VERSION ""

NS_ :

BS_:

BU_: CGM_HS TCM_HS RDCM_HS EPS_HS ECM_HS EBCM_HS BSM_HS BCM_HS

BO_ 313 Body_Information_4_HS: 8 BCM_HS
 SG_ LnchCtrlRelLnLockReqd : 15|1@0+ (1,0) [0|1] ""  CGM_HS,EBCM_HS
 SG_ VehStbEnhmntCurStRq : 47|2@0+ (1,0) [0|3] ""  CGM_HS,EBCM_HS
 SG_ TCSysCurStReq : 23|2@0+ (1,0) [0|3] ""  CGM_HS,EBCM_HS
 SG_ DrvrDrOpenSwVDA : 14|1@0+ (1,0) [0|1] ""  CGM_HS,ECM_HS
 SG_ DrDoorOpenSwActV : 12|1@0+ (1,0) [0|1] ""  CGM_HS,ECM_HS
 SG_ DrDoorOpenSwAct : 11|1@0+ (1,0) [0|1] ""  CGM_HS,ECM_HS
 SG_ LnchCtrlWhlSlpReq : 55|5@0+ (1,0) [0|31] ""  CGM_HS,EBCM_HS
 SG_ LnchCtrlMdReq : 57|2@0+ (1,0) [0|3] ""  CGM_HS,EBCM_HS
 SG_ LnchCtrlEngRPMReq : 63|6@0+ (1,0) [0|63] ""  CGM_HS,EBCM_HS
 SG_ ExtHlStrAssCsStRq : 50|3@0+ (1,0) [0|7] ""  CGM_HS,EBCM_HS
 SG_ DrvStyPerfMdCsStReq : 45|3@0+ (1,0) [0|7] ""  CGM_HS,EBCM_HS
 SG_ PsngStPerfMdCsStReq : 42|3@0+ (1,0) [0|7] ""  CGM_HS,EBCM_HS
 SG_ DrvrStPerfMdCsStReq : 31|3@0+ (1,0) [0|7] ""  CGM_HS,EBCM_HS
 SG_ ACCPerfMdCsStReq : 28|3@0+ (1,0) [0|7] ""  CGM_HS,EBCM_HS
 SG_ PrkAstAdvSysAct : 8|1@0+ (1,0) [0|1] ""  CGM_HS,EBCM_HS
 SG_ SndPerfMdCsStRq : 18|3@0+ (1,0) [0|7] ""  CGM_HS,EBCM_HS
 SG_ HptcStVbnStat : 2|2@0+ (1,0) [0|3] ""  CGM_HS
 SG_ ACCSettingType : 10|2@0+ (1,0) [0|3] ""  CGM_HS
 SG_ FCABrkPrflReq : 13|1@0+ (1,0) [0|1] ""  CGM_HS,EBCM_HS
 SG_ ISA2CCC_ScndCdChr : 36|5@0+ (1,0) [0|31] ""  CGM_HS
 SG_ ISA2CCC_FrstCdChr : 25|5@0+ (1,0) [0|31] ""  CGM_HS
 SG_ DispPerfMdCsStRq : 21|3@0+ (1,0) [0|7] ""  CGM_HS,EBCM_HS
 SG_ CrshAlrtStPrsnt : 0|1@0+ (1,0) [0|1] ""  CGM_HS,EBCM_HS
 SG_ FwdClnAlrtCustStngReq : 5|3@0+ (1,0) [0|7] ""  CGM_HS
 SG_ GNCustStngReq : 7|2@0+ (1,0) [0|3] ""  CGM_HS

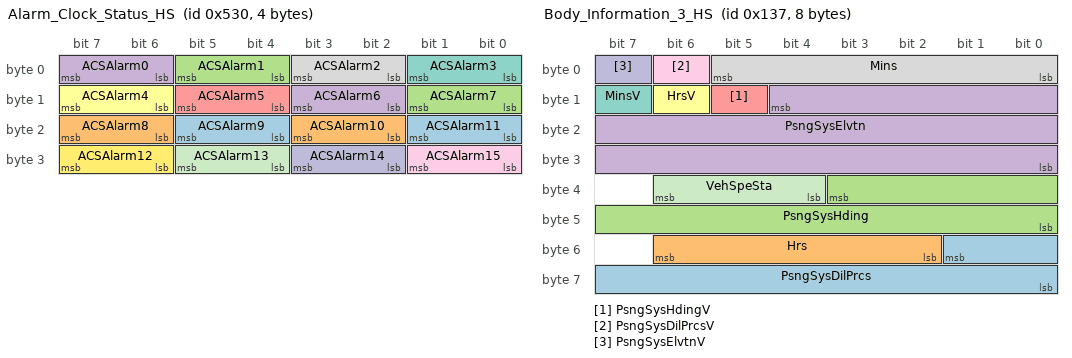
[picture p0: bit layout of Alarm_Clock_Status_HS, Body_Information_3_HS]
BO_ 1328 Alarm_Clock_Status_HS: 4 BCM_HS
 SG_ ACSAlarm9 : 21|2@0+ (1,0) [0|3] ""  CGM_HS
 SG_ ACSAlarm8 : 23|2@0+ (1,0) [0|3] ""  CGM_HS
 SG_ ACSAlarm7 : 9|2@0+ (1,0) [0|3] ""  CGM_HS
 SG_ ACSAlarm6 : 11|2@0+ (1,0) [0|3] ""  CGM_HS
 SG_ ACSAlarm5 : 13|2@0+ (1,0) [0|3] ""  CGM_HS
 SG_ ACSAlarm4 : 15|2@0+ (1,0) [0|3] ""  CGM_HS
 SG_ ACSAlarm3 : 1|2@0+ (1,0) [0|3] ""  CGM_HS
 SG_ ACSAlarm2 : 3|2@0+ (1,0) [0|3] ""  CGM_HS
 SG_ ACSAlarm15 : 25|2@0+ (1,0) [0|3] ""  CGM_HS
 SG_ ACSAlarm14 : 27|2@0+ (1,0) [0|3] ""  CGM_HS
 SG_ ACSAlarm13 : 29|2@0+ (1,0) [0|3] ""  CGM_HS
 SG_ ACSAlarm12 : 31|2@0+ (1,0) [0|3] ""  CGM_HS
 SG_ ACSAlarm11 : 17|2@0+ (1,0) [0|3] ""  CGM_HS
 SG_ ACSAlarm10 : 19|2@0+ (1,0) [0|3] ""  CGM_HS
 SG_ ACSAlarm1 : 5|2@0+ (1,0) [0|3] ""  CGM_HS
 SG_ ACSAlarm0 : 7|2@0+ (1,0) [0|3] ""  CGM_HS

BO_ 311 Body_Information_3_HS: 8 BCM_HS
 SG_ PsngSysDilPrcs : 49|10@0+ (0.1,0) [0|102.3] ""  CGM_HS
 SG_ Hrs : 54|5@0+ (1,0) [0|31] "h"  CGM_HS
 SG_ PsngSysHding : 35|12@0+ (0.1,0) [0|409.5] "deg"  CGM_HS
 SG_ PsngSysElvtn : 12|21@0+ (1,-100000) [-100000|1997151] "cm"  CGM_HS
 SG_ PsngSysHdingV : 13|1@0+ (1,0) [0|1] ""  CGM_HS
 SG_ HrsV : 14|1@0+ (1,0) [0|1] ""  CGM_HS
 SG_ MinsV : 15|1@0+ (1,0) [0|1] ""  CGM_HS
 SG_ Mins : 5|6@0+ (1,0) [0|63] "min"  CGM_HS
 SG_ PsngSysDilPrcsV : 6|1@0+ (1,0) [0|1] ""  CGM_HS
 SG_ PsngSysElvtnV : 7|1@0+ (1,0) [0|1] ""  CGM_HS
 SG_ VehSpeSta : 38|3@0+ (1,0) [0|7] ""  CGM_HS

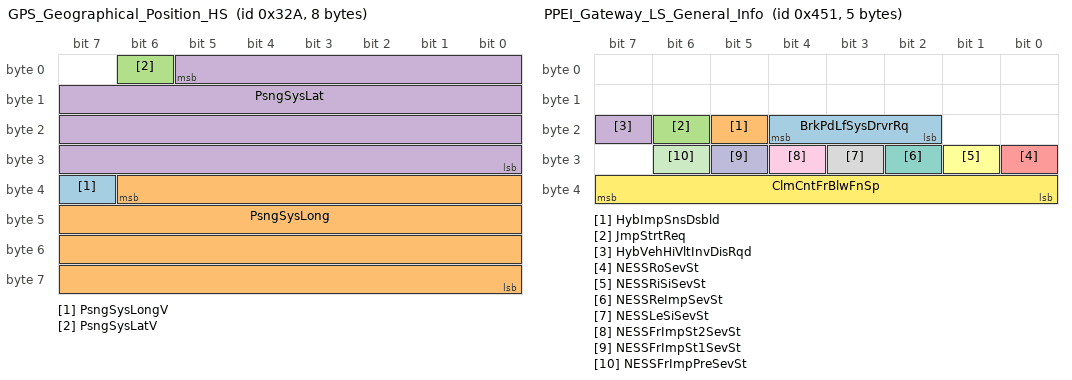
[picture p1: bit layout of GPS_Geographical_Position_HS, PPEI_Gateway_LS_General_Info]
BO_ 810 GPS_Geographical_Position_HS: 8 BCM_HS
 SG_ PsngSysLongV : 39|1@0+ (1,0) [0|1] ""  CGM_HS,EBCM_HS
 SG_ PsngSysLong : 38|31@0- (1,0) [-1073741824|1073741823] "ms arc"  CGM_HS,EBCM_HS
 SG_ PsngSysLatV : 6|1@0+ (1,0) [0|1] ""  CGM_HS,EBCM_HS
 SG_ PsngSysLat : 5|30@0- (1,0) [-536870912|536870911] "ms arc"  CGM_HS,EBCM_HS

BO_ 304 Content_Theft_Sensor_Status_HS: 1 BCM_HS
 SG_ PedFrndlyAlrtCsStReq : 5|3@0+ (1,0) [0|7] ""  CGM_HS
 SG_ AlrmStat : 2|3@0+ (1,0) [0|7] ""  CGM_HS

BO_ 1105 PPEI_Gateway_LS_General_Info: 5 BCM_HS
 SG_ BrkPdLfSysDrvrRq : 20|3@0+ (1,0) [0|7] ""  CGM_HS,EBCM_HS
 SG_ HybImpSnsDsbld : 21|1@0+ (1,0) [0|1] ""  CGM_HS
 SG_ JmpStrtReq : 22|1@0+ (1,0) [0|1] ""  CGM_HS,BSM_HS
 SG_ HybVehHiVltInvDisRqd : 23|1@0+ (1,0) [0|1] ""  CGM_HS
 SG_ NESSRoSevSt : 24|1@0+ (1,0) [0|1] ""  CGM_HS,ECM_HS
 SG_ NESSRiSiSevSt : 25|1@0+ (1,0) [0|1] ""  CGM_HS,ECM_HS
 SG_ NESSReImpSevSt : 26|1@0+ (1,0) [0|1] ""  CGM_HS,ECM_HS
 SG_ NESSLeSiSevSt : 27|1@0+ (1,0) [0|1] ""  CGM_HS,ECM_HS
 SG_ NESSFrImpSt2SevSt : 28|1@0+ (1,0) [0|1] ""  CGM_HS,ECM_HS
 SG_ NESSFrImpSt1SevSt : 29|1@0+ (1,0) [0|1] ""  CGM_HS,ECM_HS
 SG_ NESSFrImpPreSevSt : 30|1@0+ (1,0) [0|1] ""  CGM_HS,ECM_HS
 SG_ ClmCntFrBlwFnSp : 39|8@0+ (0.392157,0) [0|100.000035] "%"  CGM_HS,EBCM_HS

BO_ 1345 UUDT_Resp_From_BCM_HS: 8 BCM_HS
 SG_ DgnInf_HS541 : 7|64@0+ (1,0) [0|1.84467440737096E+019] ""  CGM_HS

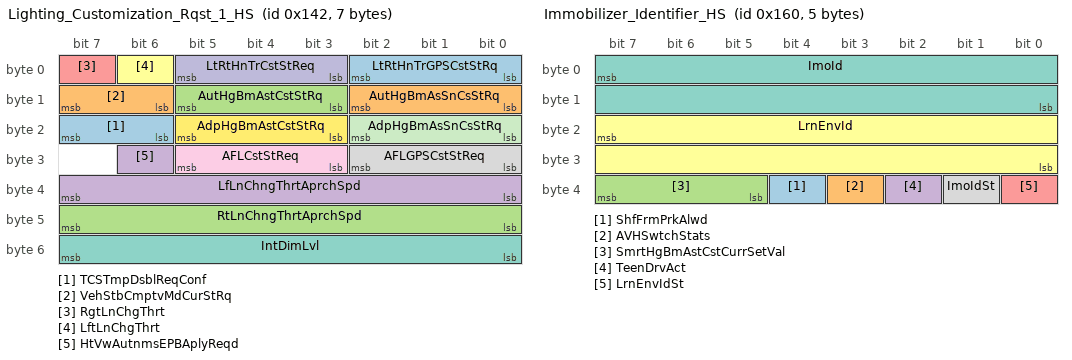
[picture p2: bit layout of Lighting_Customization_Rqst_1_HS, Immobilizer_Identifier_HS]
BO_ 322 Lighting_Customization_Rqst_1_HS: 7 BCM_HS
 SG_ TCSTmpDsblReqConf : 23|2@0+ (1,0) [0|3] ""  CGM_HS,EBCM_HS
 SG_ VehStbCmptvMdCurStRq : 15|2@0+ (1,0) [0|3] ""  CGM_HS,EBCM_HS
 SG_ RtLnChngThrtAprchSpd : 47|8@0- (1,0) [-128|127] "km/h"  CGM_HS
 SG_ LfLnChngThrtAprchSpd : 39|8@0- (1,0) [-128|127] "km/h"  CGM_HS
 SG_ RgtLnChgThrt : 7|1@0+ (1,0) [0|1] ""  CGM_HS
 SG_ LftLnChgThrt : 6|1@0+ (1,0) [0|1] ""  CGM_HS
 SG_ IntDimLvl : 55|8@0+ (0.392157,0) [0|100.000035] "%"  CGM_HS,ECM_HS,EBCM_HS
 SG_ AFLGPSCstStReq : 26|3@0+ (1,0) [0|7] ""  CGM_HS
 SG_ AFLCstStReq : 29|3@0+ (1,0) [0|7] ""  CGM_HS
 SG_ LtRtHnTrCstStReq : 5|3@0+ (1,0) [0|7] ""  CGM_HS
 SG_ AdpHgBmAsSnCsStRq : 18|3@0+ (1,0) [0|7] ""  CGM_HS
 SG_ AdpHgBmAstCstStRq : 21|3@0+ (1,0) [0|7] ""  CGM_HS
 SG_ LtRtHnTrGPSCstStRq : 2|3@0+ (1,0) [0|7] ""  CGM_HS
 SG_ AutHgBmAsSnCsStRq : 10|3@0+ (1,0) [0|7] ""  CGM_HS
 SG_ AutHgBmAstCstStRq : 13|3@0+ (1,0) [0|7] ""  CGM_HS
 SG_ HtVwAutnmsEPBAplyReqd : 30|1@0+ (1,0) [0|1] ""  CGM_HS,EBCM_HS

BO_ 309 Body_Information_2_HS: 8 BCM_HS
 SG_ PedFrndlyAlrtSndMnAct : 8|1@0+ (1,0) [0|1] ""  CGM_HS
 SG_ StBltTgtCSRq : 23|3@0+ (1,0) [0|7] ""  CGM_HS,EBCM_HS
 SG_ ColPrSysCustReq : 15|3@0+ (1,0) [0|7] ""  CGM_HS
 SG_ SecV : 62|1@0+ (1,0) [0|1] ""  CGM_HS
 SG_ Sec : 61|6@0+ (1,0) [0|63] "s"  CGM_HS
 SG_ CldrYr_154 : 55|8@0+ (1,2000) [2000|2255] "year"  CGM_HS
 SG_ CldrYr : 47|8@0+ (1,2000) [2000|2255] "year"  CGM_HS,EBCM_HS
 SG_ CldrMth_154 : 39|4@0+ (1,0) [0|15] ""  CGM_HS
 SG_ CldrMth : 35|4@0+ (1,0) [0|15] ""  CGM_HS,EBCM_HS
 SG_ CldrDay_154 : 30|5@0+ (1,0) [0|31] "days"  CGM_HS
 SG_ CldrDay : 20|5@0+ (1,0) [0|31] "days"  CGM_HS,EBCM_HS
 SG_ AutoHiBmVDA : 25|1@0+ (1,0) [0|1] ""  CGM_HS
 SG_ CtLghtDet : 24|1@0+ (1,0) [0|1] ""  CGM_HS
 SG_ RrClosVDA : 11|1@0+ (1,0) [0|1] ""  CGM_HS
 SG_ TCSysDisSwAtv : 4|1@0+ (1,0) [0|1] ""  CGM_HS,EBCM_HS
 SG_ VehMovState : 2|3@0+ (1,0) [0|7] ""  CGM_HS,RDCM_HS,EBCM_HS
 SG_ TCSysDisSwAtvV : 3|1@0+ (1,0) [0|1] ""  CGM_HS,EBCM_HS
 SG_ HillDesCtrlMdSwActV : 10|1@0+ (1,0) [0|1] ""  CGM_HS,EBCM_HS
 SG_ WSWshSwAtv : 5|1@0+ (1,0) [0|1] ""  CGM_HS
 SG_ HillDesCtrlMdSwAct : 9|1@0+ (1,0) [0|1] ""  CGM_HS,EBCM_HS
 SG_ RrClosAjarSwAct : 12|1@0+ (1,0) [0|1] ""  CGM_HS
 SG_ WSWprAct : 6|1@0+ (1,0) [0|1] ""  CGM_HS,ECM_HS,EBCM_HS

BO_ 352 Immobilizer_Identifier_HS: 5 BCM_HS
 SG_ ShfFrmPrkAlwd : 36|1@0+ (1,0) [0|1] ""  CGM_HS,ECM_HS
 SG_ AVHSwtchStats : 35|1@0+ (1,0) [0|1] ""  CGM_HS,EBCM_HS
 SG_ SmrtHgBmAstCstCurrSetVal : 39|3@0+ (1,0) [0|7] ""  CGM_HS
 SG_ TeenDrvAct : 34|1@0+ (1,0) [0|1] ""  CGM_HS,EBCM_HS
 SG_ LrnEnvIdSt : 32|1@0+ (1,0) [0|1] ""  CGM_HS,EBCM_HS
 SG_ LrnEnvId : 23|16@0+ (1,0) [0|65535] ""  CGM_HS,EBCM_HS
 SG_ ImoId : 7|16@0+ (1,0) [0|65535] ""  CGM_HS,EBCM_HS
 SG_ ImoIdSt : 33|1@0+ (1,0) [0|1] ""  CGM_HS,EBCM_HS

BO_ 320 Exterior_Lighting_HS: 3 BCM_HS
 SG_ Ky_IdDevPrgmAuthReq : 14|1@0+ (1,0) [0|1] ""  CGM_HS,EPS_HS
 SG_ ClmnLckStatV : 15|1@0+ (1,0) [0|1] ""  CGM_HS,EPS_HS
 SG_ ClmnLckStat : 21|2@0+ (1,0) [0|3] ""  CGM_HS,EPS_HS
 SG_ AutoBmSlctAllwd : 13|1@0+ (1,0) [0|1] ""  CGM_HS
 SG_ BrkLtsAtv : 6|1@0+ (1,0) [0|1] ""  CGM_HS
 SG_ TrnSwAct : 19|2@0+ (1,0) [0|3] ""  CGM_HS,ECM_HS,EBCM_HS
 SG_ RrFogLmpsAct : 8|1@0+ (1,0) [0|1] ""  CGM_HS
 SG_ OtsdAmbtLtLvlStatV : 2|1@0+ (1,0) [0|1] ""  CGM_HS,ECM_HS,EBCM_HS
 SG_ OtsdAmbtLtLvlStat : 17|2@0+ (1,0) [0|3] ""  CGM_HS,ECM_HS,EBCM_HS
 SG_ MainLghtSw : 12|2@0+ (1,0) [0|3] "N/A"  CGM_HS
 SG_ LowBmAct : 1|1@0+ (1,0) [0|1] ""  CGM_HS
 SG_ HighBmAct : 7|1@0+ (1,0) [0|1] ""  CGM_HS
 SG_ HdlmpBmSelectStat : 10|2@0+ (1,0) [0|3] ""  CGM_HS
 SG_ FlToPsSwAtv : 5|1@0+ (1,0) [0|1] ""  CGM_HS
 SG_ AdvFrntLghtSysEnbld : 3|1@0+ (1,0) [0|1] ""  CGM_HS
 SG_ FrFogLmpsAct : 0|1@0+ (1,0) [0|1] ""  CGM_HS
 SG_ AutLghtCtrl : 4|1@0+ (1,0) [0|1] "N/A"  CGM_HS

BO_ 2041 PCU_Resp_From_SDM_HS: 8 BCM_HS
 SG_ PCUInfo_7F9 : 7|64@0+ (1,0) [0|1.84467440737096E+019] ""  CGM_HS

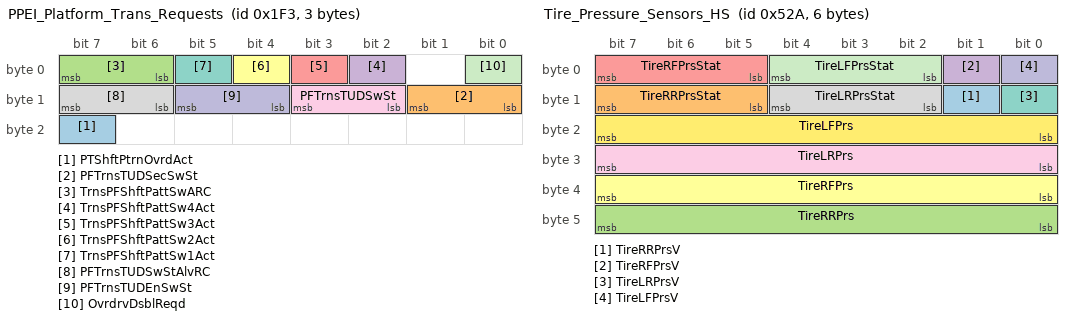
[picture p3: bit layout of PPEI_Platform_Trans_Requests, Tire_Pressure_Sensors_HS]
BO_ 499 PPEI_Platform_Trans_Requests: 3 BCM_HS
 SG_ PTShftPtrnOvrdAct : 23|1@0+ (1,0) [0|1] ""  CGM_HS,TCM_HS
 SG_ PFTrnsTUDSecSwSt : 9|2@0+ (1,0) [0|3] ""  CGM_HS,TCM_HS
 SG_ TrnsPFShftPattSwARC : 7|2@0+ (1,0) [0|3] ""  CGM_HS,TCM_HS,ECM_HS
 SG_ TrnsPFShftPattSw4Act : 2|1@0+ (1,0) [0|1] ""  CGM_HS,TCM_HS,ECM_HS
 SG_ TrnsPFShftPattSw3Act : 3|1@0+ (1,0) [0|1] ""  CGM_HS,TCM_HS,ECM_HS
 SG_ TrnsPFShftPattSw2Act : 4|1@0+ (1,0) [0|1] ""  CGM_HS,TCM_HS,ECM_HS
 SG_ TrnsPFShftPattSw1Act : 5|1@0+ (1,0) [0|1] ""  CGM_HS,TCM_HS,ECM_HS
 SG_ PFTrnsTUDSwStAlvRC : 15|2@0+ (1,0) [0|3] ""  CGM_HS,TCM_HS
 SG_ PFTrnsTUDSwSt : 11|2@0+ (1,0) [0|3] ""  CGM_HS,TCM_HS
 SG_ PFTrnsTUDEnSwSt : 13|2@0+ (1,0) [0|3] ""  CGM_HS,TCM_HS
 SG_ OvrdrvDsblReqd : 0|1@0+ (1,0) [0|1] ""  CGM_HS

BO_ 298 Body_Information_HS: 8 BCM_HS
 SG_ DrvrDrAjrSwVDA : 58|1@0+ (1,0) [0|1] ""  CGM_HS,ECM_HS
 SG_ ValetMdAct : 59|1@0+ (1,0) [0|1] ""  CGM_HS,EBCM_HS
 SG_ AutoMdSpdLmtCnfrmd : 57|1@0+ (1,0) [0|1] ""  CGM_HS,ECM_HS
 SG_ TCSysDisSwAtvARC : 61|2@0+ (1,0) [0|3] ""  CGM_HS,ECM_HS,EBCM_HS
 SG_ TCSysDisSwAtv_12A : 62|1@0+ (1,0) [0|1] ""  CGM_HS,ECM_HS
 SG_ ChmAct : 55|1@0+ (1,0) [0|1] ""  CGM_HS
 SG_ Ky_IdDevPr : 56|1@0+ (1,0) [0|1] ""  CGM_HS,EBCM_HS
 SG_ DDAjrSwAtvM : 63|1@0+ (1,0) [0|1] ""  CGM_HS,ECM_HS,EBCM_HS
 SG_ CrshAlrtDrvrSlctdType : 5|1@0+ (1,0) [0|1] ""  CGM_HS,EBCM_HS
 SG_ PsSbltAtcV : 54|1@0+ (1,0) [0|1] ""  CGM_HS,EBCM_HS
 SG_ PsSbltAtc : 53|1@0+ (1,0) [0|1] ""  CGM_HS,EBCM_HS
 SG_ TrlrBrkDsplyAct : 51|1@0+ (1,0) [0|1] ""  CGM_HS,EBCM_HS
 SG_ RdSpdCatType : 45|2@0+ (1,0) [0|3] ""  CGM_HS
 SG_ LnCat : 47|2@0+ (1,0) [0|3] ""  CGM_HS
 SG_ FncRdClass : 50|3@0+ (1,0) [0|7] ""  CGM_HS
 SG_ SprtLnRd : 43|1@0+ (1,0) [0|1] ""  CGM_HS
 SG_ CntrldAccRd : 39|1@0+ (1,0) [0|1] ""  CGM_HS
 SG_ BldUpArDet : 11|1@0+ (1,0) [0|1] ""  CGM_HS
 SG_ MpDataAvlbl : 3|1@0+ (1,0) [0|1] ""  CGM_HS
 SG_ SusCustStngReq : 42|3@0+ (1,0) [0|7] ""  CGM_HS,EBCM_HS
 SG_ StrCustStngReq : 38|3@0+ (1,0) [0|7] ""  CGM_HS,EBCM_HS
 SG_ RstrCustFctrDef : 35|1@0+ (1,0) [0|1] ""  CGM_HS,EBCM_HS
 SG_ DrvlnCustStngReq : 34|3@0+ (1,0) [0|7] ""  CGM_HS,EBCM_HS
 SG_ ChmMstrVDA : 22|1@0+ (1,0) [0|1] ""  CGM_HS
 SG_ IPCVDA : 21|1@0+ (1,0) [0|1] ""  CGM_HS,EBCM_HS
 SG_ HeadUpDispVDA : 20|1@0+ (1,0) [0|1] ""  CGM_HS
 SG_ HapticSeatVDA : 52|1@0+ (1,0) [0|1] ""  CGM_HS
 SG_ RRDoorAjarSwAct : 23|1@0+ (1,0) [0|1] ""  CGM_HS
 SG_ PDAjrSwAtv : 10|1@0+ (1,0) [0|1] ""  CGM_HS
 SG_ DDAjrSwAtv : 9|1@0+ (1,0) [0|1] ""  CGM_HS,ECM_HS,EBCM_HS
 SG_ TrlrHWIntrfcVDA : 4|1@0+ (1,0) [0|1] ""  CGM_HS,RDCM_HS,EBCM_HS
 SG_ DrId : 15|3@0+ (1,0) [0|7] ""  CGM_HS,EBCM_HS
 SG_ EnrgMgtLdShdRq : 19|4@0+ (1,0) [0|15] ""  CGM_HS
 SG_ DrSbltAtcV : 2|1@0+ (1,0) [0|1] ""  CGM_HS,ECM_HS,EBCM_HS
 SG_ TrlrHtchSwAtv : 0|1@0+ (1,0) [0|1] ""  CGM_HS,RDCM_HS,ECM_HS,EBCM_HS
 SG_ TreInfMonSysRstReq : 7|1@0+ (1,0) [0|1] ""  CGM_HS,EBCM_HS
 SG_ HUDActv : 6|1@0+ (1,0) [0|1] ""  CGM_HS
 SG_ BatVltV : 1|1@0+ (1,0) [0|1] ""  CGM_HS,TCM_HS,ECM_HS
 SG_ BatVlt : 31|8@0+ (0.1,3) [3|28.5] "volts"  CGM_HS,TCM_HS,ECM_HS
 SG_ RLDoorAjarSwAct : 8|1@0+ (1,0) [0|1] ""  CGM_HS
 SG_ DrSbltAtc : 12|1@0+ (1,0) [0|1] ""  CGM_HS,ECM_HS,EBCM_HS

BO_ 1322 Tire_Pressure_Sensors_HS: 6 BCM_HS
 SG_ TireRRPrsV : 9|1@0+ (1,0) [0|1] ""  CGM_HS,RDCM_HS,EBCM_HS
 SG_ TireRRPrsStat : 15|3@0+ (1,0) [0|7] ""  CGM_HS,RDCM_HS,EBCM_HS
 SG_ TireRRPrs : 47|8@0+ (4,0) [0|1020] "kPaG"  CGM_HS,RDCM_HS,EBCM_HS
 SG_ TireRFPrsV : 1|1@0+ (1,0) [0|1] ""  CGM_HS,RDCM_HS,EBCM_HS
 SG_ TireRFPrsStat : 7|3@0+ (1,0) [0|7] ""  CGM_HS,RDCM_HS,EBCM_HS
 SG_ TireRFPrs : 39|8@0+ (4,0) [0|1020] "kPaG"  CGM_HS,RDCM_HS,EBCM_HS
 SG_ TireLRPrsV : 8|1@0+ (1,0) [0|1] ""  CGM_HS,RDCM_HS,EBCM_HS
 SG_ TireLRPrsStat : 12|3@0+ (1,0) [0|7] ""  CGM_HS,RDCM_HS,EBCM_HS
 SG_ TireLRPrs : 31|8@0+ (4,0) [0|1020] "kPaG"  CGM_HS,RDCM_HS,EBCM_HS
 SG_ TireLFPrsV : 0|1@0+ (1,0) [0|1] ""  CGM_HS,RDCM_HS,EBCM_HS
 SG_ TireLFPrsStat : 4|3@0+ (1,0) [0|7] ""  CGM_HS,RDCM_HS,EBCM_HS
 SG_ TireLFPrs : 23|8@0+ (4,0) [0|1020] "kPaG"  CGM_HS,RDCM_HS,EBCM_HS

BO_ 1601 USDT_Resp_From_BCM_HS: 8 BCM_HS
 SG_ DgnInf : 7|64@0+ (1,0) [0|1.84467440737096E+019] ""  CGM_HS

BO_ 1300 VIN_Digits_2_to_9_HS: 8 BCM_HS
 SG_ VehIdNmDig2_9 : 7|64@0+ (1,0) [0|1] ""  CGM_HS,RDCM_HS,EPS_HS,EBCM_HS

BO_ 288 Vehicle_Odometer_HS: 5 BCM_HS
 SG_ VehOdo : 7|32@0+ (0.015625,0) [0|67108863.984375] "km"  CGM_HS,RDCM_HS,ECM_HS,EBCM_HS
 SG_ VehOdoV : 32|1@0+ (1,0) [0|1] ""  CGM_HS,RDCM_HS,ECM_HS,EBCM_HS

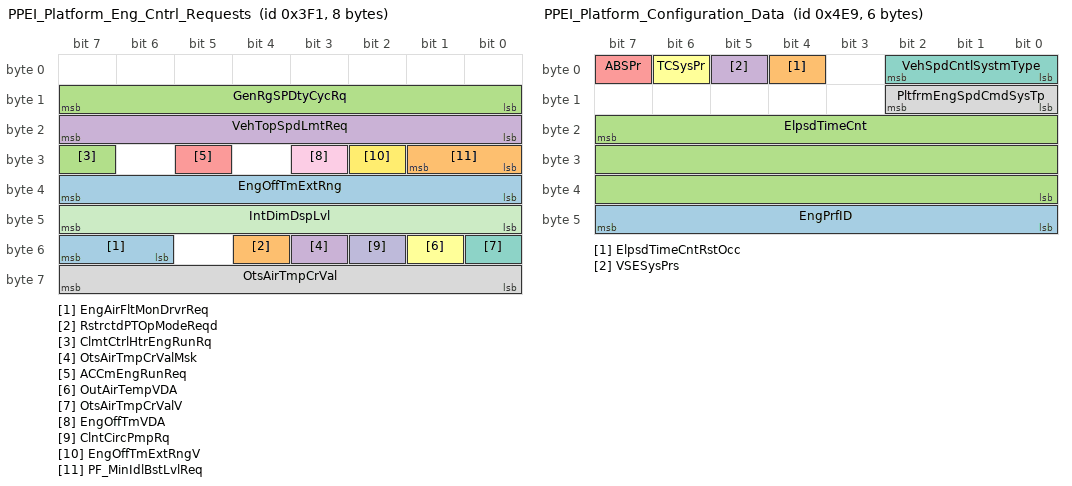
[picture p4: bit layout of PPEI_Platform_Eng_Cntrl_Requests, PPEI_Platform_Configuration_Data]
BO_ 1009 PPEI_Platform_Eng_Cntrl_Requests: 8 BCM_HS
 SG_ EngAirFltMonDrvrReq : 55|2@0+ (1,0) [0|3] ""  CGM_HS,ECM_HS
 SG_ RstrctdPTOpModeReqd : 52|1@0+ (1,0) [0|1] ""  CGM_HS,ECM_HS
 SG_ ClmtCtrlHtrEngRunRq : 31|1@0+ (1,0) [0|1] ""  CGM_HS,ECM_HS
 SG_ OtsAirTmpCrValMsk : 51|1@0+ (1,0) [0|1] ""  CGM_HS,RDCM_HS,ECM_HS,EPS_HS
 SG_ ACCmEngRunReq : 29|1@0+ (1,0) [0|1] ""  CGM_HS,ECM_HS,BSM_HS
 SG_ OutAirTempVDA : 49|1@0+ (1,0) [0|1] ""  CGM_HS,TCM_HS,RDCM_HS,ECM_HS
 SG_ OtsAirTmpCrValV : 48|1@0+ (1,0) [0|1] ""  CGM_HS,TCM_HS,RDCM_HS,ECM_HS,EPS_HS,EBCM_HS
 SG_ OtsAirTmpCrVal : 63|8@0+ (0.5,-40) [-40|87.5] "deg C"  CGM_HS,TCM_HS,RDCM_HS,ECM_HS,EPS_HS,EBCM_HS
 SG_ EngOffTmVDA : 27|1@0+ (1,0) [0|1] ""  CGM_HS,EPS_HS,EBCM_HS
 SG_ ClntCircPmpRq : 50|1@0+ (1,0) [0|1] ""  CGM_HS,ECM_HS,BSM_HS
 SG_ IntDimDspLvl : 47|8@0+ (0.392157,0) [0|100.000035] "%"  CGM_HS,ECM_HS,EBCM_HS
 SG_ EngOffTmExtRngV : 26|1@0+ (1,0) [0|1] ""  CGM_HS,RDCM_HS,EPS_HS,EBCM_HS
 SG_ EngOffTmExtRng : 39|8@0+ (4,0) [0|1020] "min"  CGM_HS,RDCM_HS,EPS_HS,EBCM_HS
 SG_ PF_MinIdlBstLvlReq : 25|2@0+ (1,0) [0|3] ""  CGM_HS,ECM_HS
 SG_ GenRgSPDtyCycRq : 15|8@0+ (0.392157,0) [0|100.000035] "%"  CGM_HS,ECM_HS
 SG_ VehTopSpdLmtReq : 23|8@0+ (2,0) [0|510] "km / h"  CGM_HS,ECM_HS

BO_ 1257 PPEI_Platform_Configuration_Data: 6 BCM_HS
 SG_ EngPrfID : 47|8@0+ (2,0) [0|510] "kW"  CGM_HS,ECM_HS
 SG_ ElpsdTimeCntRstOcc : 4|1@0+ (1,0) [0|1] ""  CGM_HS,RDCM_HS
 SG_ ElpsdTimeCnt : 23|24@0+ (1,0) [0|16777215] "min"  CGM_HS,RDCM_HS,ECM_HS
 SG_ VSESysPrs : 5|1@0+ (1,0) [0|1] ""  CGM_HS,TCM_HS,ECM_HS
 SG_ ABSPr : 7|1@0+ (1,0) [0|1] ""  CGM_HS,TCM_HS,ECM_HS
 SG_ TCSysPr : 6|1@0+ (1,0) [0|1] ""  CGM_HS,TCM_HS,ECM_HS
 SG_ VehSpdCntlSystmType : 2|3@0+ (1,0) [0|7] ""  CGM_HS,ECM_HS
 SG_ PltfrmEngSpdCmdSysTp : 10|3@0+ (1,0) [0|7] ""  CGM_HS,TCM_HS,ECM_HS

BO_ 505 PPEI_PTO_Command_Data: 8 BCM_HS
 SG_ AllNodesVNA_1F9 : 43|1@0+ (1,0) [0|1] ""  CGM_HS,BCM_HS
 SG_ PTOVehTopSpdLimVal : 63|8@0+ (2,0) [0|510] "km / h"  CGM_HS,BCM_HS
 SG_ AccPdlPwrTkOffOvrAct : 4|1@0+ (1,0) [0|1] ""  CGM_HS,ECM_HS
 SG_ PTOTGRReqdGear : 35|4@0+ (1,0) [0|15] ""  CGM_HS,TCM_HS
 SG_ PTOTGRReqType : 37|2@0+ (1,0) [0|3] ""  CGM_HS,TCM_HS
 SG_ PTORmtEngStrtReq : 44|1@0+ (1,0) [0|1] ""  CGM_HS,BCM_HS
 SG_ TrnsPTOCltchRelRqd : 38|1@0+ (1,0) [0|1] ""  CGM_HS,TCM_HS
 SG_ FstIdlMdAct : 47|1@0+ (1,0) [0|1] ""  CGM_HS,ECM_HS,BCM_HS
 SG_ PTOMdAct : 46|1@0+ (1,0) [0|1] ""  CGM_HS,ECM_HS,EBCM_HS
 SG_ PTOEngTrqLmtRchd : 45|1@0+ (1,0) [0|1] ""  CGM_HS,ECM_HS
 SG_ PTOEngTrqLmtValER : 55|8@0+ (8,0) [0|2040] "Nm"  CGM_HS,ECM_HS
 SG_ PltfrmEngSpdCmdMdAct : 3|1@0+ (1,0) [0|1] ""  CGM_HS,TCM_HS,ECM_HS,EBCM_HS
 SG_ PltfrmEngSpdReq : 2|11@0+ (4,0) [0|8188] "rpm"  CGM_HS,TCM_HS,ECM_HS,EBCM_HS
 SG_ PFESpdCmdOnSwAct : 7|1@0+ (1,0) [0|1] ""  CGM_HS,ECM_HS
 SG_ PFESpdCmdDeSwAct : 5|1@0+ (1,0) [0|1] ""  CGM_HS,ECM_HS
 SG_ PFESpdCmdInSwAct : 6|1@0+ (1,0) [0|1] ""  CGM_HS,ECM_HS
 SG_ PFESpdCmdSwDIntg : 21|2@0+ (1,0) [0|3] ""  CGM_HS,ECM_HS
 SG_ PFEngSpdCmdAlvRlgCnt : 23|2@0+ (1,0) [0|3] ""  CGM_HS,TCM_HS,ECM_HS,EBCM_HS
 SG_ PltfrmEngSpdCmdProtVal : 19|12@0+ (1,0) [0|4095] ""  CGM_HS,ECM_HS,EBCM_HS
 SG_ PTORmtEngShtdwnReqd : 39|1@0+ (1,0) [0|1] ""  CGM_HS,ECM_HS,BCM_HS

BO_ 497 PPEI_Platform_General_Status: 8 BCM_HS
 SG_ ElvtdIdlCstStReq : 33|2@0+ (1,0) [0|3] ""  CGM_HS,ECM_HS
 SG_ FuelFltLfRstRqd : 56|1@0+ (1,0) [0|1] ""  CGM_HS,ECM_HS
 SG_ ACCompSysVDA : 9|1@0+ (1,0) [0|1] ""  CGM_HS,ECM_HS
 SG_ BkupPwrModeMstrVDA : 7|1@0+ (1,0) [0|1] ""  CGM_HS,EBCM_HS
 SG_ PrkBrkVDA : 35|1@0+ (1,0) [0|1] ""  CGM_HS,RDCM_HS
 SG_ PrkBrkVDM : 62|1@0+ (1,0) [0|1] ""  CGM_HS
 SG_ BkupPwrModeMstrVDM : 61|1@0+ (1,0) [0|1] ""  CGM_HS
 SG_ ACCompSysVDM : 60|1@0+ (1,0) [0|1] ""  CGM_HS
 SG_ AirbgVDA : 57|1@0+ (1,0) [0|1] ""  CGM_HS,ECM_HS
 SG_ SysBkupPwrMdEn : 6|1@0+ (1,0) [0|1] ""  CGM_HS,TCM_HS,RDCM_HS,ECM_HS,EPS_HS,EBCM_HS
 SG_ SysBkUpPwrMd : 5|2@0+ (1,0) [0|3] ""  CGM_HS,TCM_HS,RDCM_HS,ECM_HS,EPS_HS,EBCM_HS
 SG_ SysPwrMd : 1|2@0+ (1,0) [0|3] ""  CGM_HS,TCM_HS,RDCM_HS,ECM_HS,EPS_HS,EBCM_HS,BSM_HS
 SG_ TrStLgMdAtv : 34|1@0+ (1,0) [0|1] ""  CGM_HS,TCM_HS,RDCM_HS,ECM_HS,EPS_HS,EBCM_HS,BSM_HS
 SG_ DispMeasSys : 59|1@0+ (1,0) [0|1] ""  CGM_HS,ECM_HS,EBCM_HS
 SG_ ACCmpsrFldOn : 63|1@0+ (1,0) [0|1] ""  CGM_HS,ECM_HS
 SG_ ACCompModReq : 12|2@0+ (1,0) [0|3] ""  CGM_HS,ECM_HS
 SG_ ACCompNormLd : 55|8@0+ (0.1,0) [0|25.5] "l/min"  CGM_HS,ECM_HS
 SG_ ACCompNormLdV : 10|1@0+ (1,0) [0|1] ""  CGM_HS,ECM_HS
 SG_ PTORSMstrEngShtReq : 13|1@0+ (1,0) [0|1] ""  CGM_HS,ECM_HS
 SG_ EngOilLfRstRq : 37|1@0+ (1,0) [0|1] ""  CGM_HS,ECM_HS
 SG_ SIRDpl : 58|1@0+ (1,0) [0|1] ""  CGM_HS,ECM_HS
 SG_ PTORmStMsEngStRq : 14|1@0+ (1,0) [0|1] ""  CGM_HS,TCM_HS,ECM_HS
 SG_ RmVehStrRq : 15|1@0+ (1,0) [0|1] ""  CGM_HS,ECM_HS,BSM_HS
 SG_ ThrtlPrgrsnReq : 39|2@0+ (1,0) [0|3] ""  CGM_HS,ECM_HS
 SG_ PrkBrkSwAtv : 36|1@0+ (1,0) [0|1] ""  CGM_HS,TCM_HS,RDCM_HS,ECM_HS,EBCM_HS
 SG_ PMMAccTrmSt : 2|1@0+ (1,0) [0|1] ""  CGM_HS,TCM_HS,ECM_HS
 SG_ PMMRunCrkTrmSt : 3|1@0+ (1,0) [0|1] ""  CGM_HS,TCM_HS,ECM_HS
 SG_ ImmblzrPreRelPswdStat : 8|1@0+ (1,0) [0|1] ""  CGM_HS,ECM_HS
 SG_ ImmblzrPreRelPswrd : 23|16@0+ (1,0) [0|65535] "passwrd"  CGM_HS,ECM_HS

BO_ 969 PPEI_Platform_Immobilizer_Data: 8 BCM_HS
 SG_ ImoInf : 7|64@0+ (1,0) [0|1.84467440737096E+019] ""  CGM_HS,ECM_HS

BO_ 1249 PPEI_VIN_Digits_10_to_17: 8 BCM_HS
 SG_ VehIdNmDig10_17 : 7|64@0+ (1,0) [0|1] ""  CGM_HS,TCM_HS,RDCM_HS,ECM_HS,EPS_HS,EBCM_HS

BO_ 481 PPEI_Cruise_Control_Sw_Status: 7 BCM_HS
 SG_ CrsSecSwStatPVal : 51|4@0+ (1,0) [0|15] ""  CGM_HS,ECM_HS
 SG_ CrsSecSwStatARC : 41|2@0+ (1,0) [0|3] ""  CGM_HS,ECM_HS
 SG_ CrsSecSwStat : 27|4@0+ (1,0) [0|15] ""  CGM_HS,ECM_HS
 SG_ DrvSelMdSw3Sta : 37|1@0+ (1,0) [0|1] ""  CGM_HS,ECM_HS
 SG_ DrvSelMdSw2Sta : 38|1@0+ (1,0) [0|1] ""  CGM_HS,ECM_HS
 SG_ AuxHtrRq : 31|1@0+ (1,0) [0|1] ""  CGM_HS,ECM_HS
 SG_ AuxHtrAtv : 30|1@0+ (1,0) [0|1] ""  CGM_HS,ECM_HS
 SG_ DrvSelMdSwStaARC : 33|2@0+ (1,0) [0|3] ""  CGM_HS,ECM_HS
 SG_ DrvSelMdSw1Sta : 39|1@0+ (1,0) [0|1] ""  CGM_HS,ECM_HS
 SG_ CrsSpdLmtrSwStatPVal : 55|4@0+ (1,0) [0|15] ""  CGM_HS,ECM_HS,EBCM_HS
 SG_ CrsSpdLmtrSwStatARC : 43|2@0+ (1,0) [0|3] ""  CGM_HS,ECM_HS,EBCM_HS
 SG_ FuelMdSwActV : 29|1@0+ (1,0) [0|1] ""  CGM_HS,ECM_HS
 SG_ FuelMdSwAct : 28|1@0+ (1,0) [0|1] ""  CGM_HS,ECM_HS
 SG_ CrsSpdLmtrSwStat : 47|4@0+ (1,0) [0|15] ""  CGM_HS,ECM_HS,EBCM_HS
 SG_ AdptCrsGapSwAct : 23|2@0+ (1,0) [0|3] ""  CGM_HS
 SG_ CrsCntrlSwStCanSwAct : 7|1@0+ (1,0) [0|1] ""  CGM_HS,ECM_HS
 SG_ CrsCntrlSwStSwDataIntgty : 1|2@0+ (1,0) [0|3] ""  CGM_HS,ECM_HS
 SG_ CrsCntrlSwStSpdInSwAct : 3|1@0+ (1,0) [0|1] ""  CGM_HS,ECM_HS
 SG_ CrsCntrlSwStSpDcSwAct : 2|1@0+ (1,0) [0|1] ""  CGM_HS,ECM_HS
 SG_ CrsCntrlSwStSetSwAct : 4|1@0+ (1,0) [0|1] ""  CGM_HS,ECM_HS
 SG_ CrsCntrlSwStResSwAct : 5|1@0+ (1,0) [0|1] ""  CGM_HS,ECM_HS
 SG_ CrsCntrlSwStOnSwAct : 6|1@0+ (1,0) [0|1] ""  CGM_HS,ECM_HS
 SG_ CrsCntrlSwStatProtValue : 15|8@0+ (1,0) [0|255] ""  CGM_HS,ECM_HS
 SG_ CrsCntrlSwStAlvRollCnt : 17|2@0+ (1,0) [0|3] ""  CGM_HS,ECM_HS
 SG_ CrsCntCncRq : 18|1@0+ (1,0) [0|1] ""  CGM_HS,ECM_HS

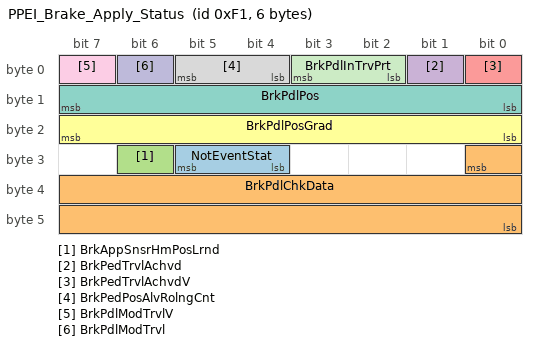
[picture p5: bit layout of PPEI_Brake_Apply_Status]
BO_ 241 PPEI_Brake_Apply_Status: 6 BCM_HS
 SG_ NotEventStat : 29|2@0+ (1,0) [0|3] ""  ECM_HS,EPS_HS,CGM_HS,EBCM_HS
 SG_ BrkPdlChkData : 24|17@0+ (1,0) [0|131071] ""  CGM_HS
 SG_ BrkAppSnsrHmPosLrnd : 30|1@0+ (1,0) [0|1] ""  ECM_HS,EPS_HS,CGM_HS,EBCM_HS
 SG_ BrkPedTrvlAchvd : 1|1@0+ (1,0) [0|1] ""  RDCM_HS,ECM_HS,TCM_HS,EPS_HS,CGM_HS,EBCM_HS,BSM_HS
 SG_ BrkPedTrvlAchvdV : 0|1@0+ (1,0) [0|1] ""  RDCM_HS,ECM_HS,TCM_HS,EPS_HS,CGM_HS,EBCM_HS,BSM_HS
 SG_ BrkPdlPosGrad : 23|8@0- (40,0) [-5120|5080] "%/s"  EPS_HS,CGM_HS,EBCM_HS
 SG_ BrkPdlPos : 15|8@0+ (0.392157,0) [0|100.000035] "% full"  ECM_HS,TCM_HS,EPS_HS,CGM_HS,EBCM_HS
 SG_ BrkPedPosAlvRolngCnt : 5|2@0+ (1,0) [0|3] ""  RDCM_HS,ECM_HS,TCM_HS,EPS_HS,CGM_HS,EBCM_HS
 SG_ BrkPdlModTrvlV : 7|1@0+ (1,0) [0|1] ""  ECM_HS,TCM_HS,EPS_HS,CGM_HS,EBCM_HS
 SG_ BrkPdlModTrvl : 6|1@0+ (1,0) [0|1] ""  ECM_HS,TCM_HS,EPS_HS,CGM_HS,EBCM_HS
 SG_ BrkPdlInTrvPrt : 3|2@0+ (1,0) [0|3] ""  RDCM_HS,ECM_HS,TCM_HS,EPS_HS,CGM_HS,EBCM_HS

CM_ SG_ 311 PsngSysHding "The 'usable' range is somewhat less than the encoded range (0.0 to 359.9 degrees).  0.0 degrees represents North, 90.0 degrees represents East.";
CM_ SG_ 810 PsngSysLong "The units of the data are milli-arcseconds (1/3,600,000 of a degree).  The actual 'usable' range of this data is somewhat less than the encoded range (+/- 648,000,000, corresponding to +/- 180 degrees)";
CM_ SG_ 810 PsngSysLat "The units of the data are milli-arcseconds (1/3,600,000 of a degree).  The actual 'usable' range of this data is somewhat less than the encoded range (+/- 324,000,000, corresponding to +/- 90 degrees)";
CM_ SG_ 320 MainLghtSw "Operator selection for the main lighting switch";
CM_ SG_ 320 AutLghtCtrl "This signal represents if Automatic Lights Control feature is active/inactive";
CM_ SG_ 499 PFTrnsTUDSecSwSt "Added 2006 Nov 10 according to CR1112";
CM_ SG_ 298 DrId "Driver 8 changed to Unknown on 3/30/99";
CM_ SG_ 1300 VehIdNmDig2_9 "Desc: 8 ASCII Characters";
CM_ SG_ 1249 VehIdNmDig10_17 "Desc: 8 ASCII Characters";
CM_ SG_ 481 AuxHtrRq "Auxiliary Heater shall be used to denote a heater function that uses some kind of power, electrical or mechanical,  that was generated by the engine.";
CM_ SG_ 481 AuxHtrAtv "Auxiliary Heater shall be used to denote a heater function that uses some kind of power, electrical or mechanical,  that was generated by the engine.";
CM_ SG_ 241 BrkPdlModTrvlV "Indicates that the brake pedal position has passed a threshold for brake torque management and some 2 channel Vehicle Dynamics Control systems.";
CM_ SG_ 241 BrkPdlModTrvl "Indicates that the brake pedal position has passed a threshold for brake torque management and some 2 channel Vehicle Dynamics Control systems.";
BA_DEF_ SG_  "GenSigSendOnInit" ENUM  "Not Initialized","Application","Handler","DLCLS","DLCHS","DLCCE","DLCFO";
BA_DEF_ SG_  "GenSigSendType" ENUM  "not used","not used","not used","not used","not used","not used","not used","NoSigSendType","not used","not used","OnAnyChange","OnChangeIfActive","OnDelta","DLCLS","DLCHS","DLCCE","DLCFO";
BA_DEF_ SG_  "GenSigDeltaValue" INT 0 0;
BA_DEF_ SG_  "VNSigAllNodes" ENUM  "No","Yes","DLCLS","DLCHS","DLCCE","DLCFO";
BA_DEF_ SG_  "VNSigSLHSSharedDiagnostic" ENUM  "No","Yes","DLCLS","DLCHS","DLCCE","DLCFO";
BA_DEF_ SG_  "VNSigSLHS_VNReq" ENUM  "No","Yes","DLCLS","DLCHS","DLCCE","DLCFO";
BA_DEF_ SG_  "SignalType" STRING ;
BA_DEF_ SG_  "PacketOrder" INT 0 65535;
BA_DEF_ SG_  "SignalLongName" STRING ;
BA_DEF_ SG_  "GenSigStartValue" INT 0 65535;
BA_DEF_ SG_  "TxSignalSendOnInit" ENUM  "Not Initialized","Application","Handler";
BA_DEF_ BO_  "GenMsgILSupport" ENUM  "No","Yes","DLCLS","DLCHS","DLCCE","DLCFO";
BA_DEF_ BO_  "AppGenMsgCycleTime" INT 0 0;
BA_DEF_ BO_  "TpApplType" STRING ;
BA_DEF_ BO_  "Prio" INT 0 7;
BA_DEF_ BO_  "MessageSubnet" ENUM  "LS","MS","HS","CE","PE","HV","FO","S1","HE","LE","HE2","DLCLS","DLCHS","DLCCE","DLCFO","vector_leerstring";
BA_DEF_ BO_  "DiagState" ENUM  "No","Yes";
BA_DEF_ BO_  "GenMsgIlSupport" ENUM  "No","Yes";
BA_DEF_ BO_  "GenMsgStartDelayTime" INT 0 100000;
BA_DEF_ BO_  "GenMsgDelayTime" INT 0 100000;
BA_DEF_ BO_  "GenMsgCycleTime" INT 0 100000;
BA_DEF_ BO_  "GenMsgSendType" ENUM  "cyclicX","spontanX","cyclicIfActiveX","spontanWithDelay","cyclicAndSpontanX","cyclicAndSpontanWithDelay","spontanWithRepitition","cyclicIfActiveAndSpontanWD";
BA_DEF_ BO_  "DiagResponse" ENUM  "No","Yes";
BA_DEF_ BO_  "DiagRequest" ENUM  "No","Yes";
BA_DEF_ BO_  "NmMessage" ENUM  "No","Yes";
BA_DEF_REL_ BU_SG_REL_  "GenSigSuprvResp" ENUM  "None","Notify App","Substitute Default","DLCLS","DLCHS","DLCCE","DLCFO";
BA_DEF_REL_ BU_SG_REL_  "GenSigSuprvRespSubValue" INT 0 65535;
BA_DEF_REL_ BU_SG_REL_  "GenSigRxStartValue" STRING ;
BA_DEF_REL_ BU_SG_REL_  "GenSigVDAFailResp" ENUM  "No","Yes","DLCLS","DLCHS","DLCCE","DLCFO";
BA_DEF_REL_ BU_SG_REL_  "GenSigVDAFailComment" STRING ;
BA_DEF_REL_ BU_SG_REL_  "GenSigVBitRespComment" STRING ;
BA_DEF_REL_ BU_SG_REL_  "GenSigVBitResp" ENUM  "No","Yes","DLCLS","DLCHS","DLCCE","DLCFO";
BA_DEF_REL_ BU_SG_REL_  "GenSigSuprvRespComment" STRING ;
BA_DEF_REL_ BU_SG_REL_  "GenSigTimeoutMsg" HEX 0 268435455;
BA_DEF_REL_ BU_SG_REL_  "GenSigTimeoutTime" INT 0 5000;
BA_DEF_DEF_  "GenSigSendOnInit" "Not Initialized";
BA_DEF_DEF_  "GenSigSendType" "NoSigSendType";
BA_DEF_DEF_  "GenSigDeltaValue" 0;
BA_DEF_DEF_  "VNSigAllNodes" "No";
BA_DEF_DEF_  "VNSigSLHSSharedDiagnostic" "No";
BA_DEF_DEF_  "VNSigSLHS_VNReq" "No";
BA_DEF_DEF_  "SignalType" "";
BA_DEF_DEF_  "PacketOrder" 0;
BA_DEF_DEF_  "SignalLongName" "";
BA_DEF_DEF_  "GenSigStartValue" 0;
BA_DEF_DEF_  "TxSignalSendOnInit" "Not Initialized";
BA_DEF_DEF_  "GenMsgILSupport" "Yes";
BA_DEF_DEF_  "AppGenMsgCycleTime" 0;
BA_DEF_DEF_  "TpApplType" "";
BA_DEF_DEF_  "Prio" 0;
BA_DEF_DEF_  "MessageSubnet" "LS";
BA_DEF_DEF_  "DiagState" "No";
BA_DEF_DEF_  "GenMsgIlSupport" "Yes";
BA_DEF_DEF_  "GenMsgStartDelayTime" 0;
BA_DEF_DEF_  "GenMsgDelayTime" 0;
BA_DEF_DEF_  "GenMsgCycleTime" 0;
BA_DEF_DEF_  "GenMsgSendType" "spontanX";
BA_DEF_DEF_  "DiagResponse" "No";
BA_DEF_DEF_  "DiagRequest" "No";
BA_DEF_DEF_  "NmMessage" "No";
BA_DEF_DEF_REL_ "GenSigSuprvResp" "None";
BA_DEF_DEF_REL_ "GenSigSuprvRespSubValue" 0;
BA_DEF_DEF_REL_ "GenSigRxStartValue" "";
BA_DEF_DEF_REL_ "GenSigVDAFailResp" "No";
BA_DEF_DEF_REL_ "GenSigVDAFailComment" "";
BA_DEF_DEF_REL_ "GenSigVBitRespComment" "";
BA_DEF_DEF_REL_ "GenSigVBitResp" "No";
BA_DEF_DEF_REL_ "GenSigSuprvRespComment" "";
BA_DEF_DEF_REL_ "GenSigTimeoutMsg" 0;
BA_DEF_DEF_REL_ "GenSigTimeoutTime" 0;
BA_ "GenMsgSendType" BO_ 313 0;
BA_ "GenMsgCycleTime" BO_ 313 100;
BA_ "GenMsgStartDelayTime" BO_ 313 70;
BA_ "MessageSubnet" BO_ 313 2;
BA_ "GenMsgSendType" BO_ 1328 0;
BA_ "GenMsgCycleTime" BO_ 1328 1000;
BA_ "GenMsgStartDelayTime" BO_ 1328 80;
BA_ "MessageSubnet" BO_ 1328 2;
BA_ "GenMsgSendType" BO_ 311 0;
BA_ "GenMsgCycleTime" BO_ 311 100;
BA_ "GenMsgStartDelayTime" BO_ 311 60;
BA_ "MessageSubnet" BO_ 311 2;
BA_ "GenMsgSendType" BO_ 810 0;
BA_ "GenMsgCycleTime" BO_ 810 100;
BA_ "GenMsgStartDelayTime" BO_ 810 80;
BA_ "MessageSubnet" BO_ 810 2;
BA_ "GenMsgSendType" BO_ 304 0;
BA_ "GenMsgCycleTime" BO_ 304 1000;
BA_ "GenMsgStartDelayTime" BO_ 304 20;
BA_ "MessageSubnet" BO_ 304 2;
BA_ "GenMsgSendType" BO_ 1105 0;
BA_ "GenMsgCycleTime" BO_ 1105 100;
BA_ "GenMsgStartDelayTime" BO_ 1105 10;
BA_ "MessageSubnet" BO_ 1105 2;
BA_ "MessageSubnet" BO_ 1345 2;
BA_ "TpApplType" BO_ 1345 "DiagUUDTResponse";
BA_ "GenMsgILSupport" BO_ 1345 0;
BA_ "GenMsgSendType" BO_ 322 0;
BA_ "GenMsgCycleTime" BO_ 322 100;
BA_ "GenMsgStartDelayTime" BO_ 322 90;
BA_ "MessageSubnet" BO_ 322 2;
BA_ "GenMsgSendType" BO_ 309 0;
BA_ "GenMsgCycleTime" BO_ 309 100;
BA_ "GenMsgStartDelayTime" BO_ 309 50;
BA_ "MessageSubnet" BO_ 309 2;
BA_ "GenMsgSendType" BO_ 352 0;
BA_ "GenMsgCycleTime" BO_ 352 100;
BA_ "GenMsgStartDelayTime" BO_ 352 30;
BA_ "MessageSubnet" BO_ 352 2;
BA_ "GenMsgSendType" BO_ 320 0;
BA_ "GenMsgCycleTime" BO_ 320 1000;
BA_ "GenMsgDelayTime" BO_ 320 10;
BA_ "GenMsgStartDelayTime" BO_ 320 30;
BA_ "MessageSubnet" BO_ 320 2;
BA_ "MessageSubnet" BO_ 2041 2;
BA_ "GenMsgSendType" BO_ 499 0;
BA_ "GenMsgCycleTime" BO_ 499 30;
BA_ "GenMsgStartDelayTime" BO_ 499 20;
BA_ "MessageSubnet" BO_ 499 2;
BA_ "GenMsgSendType" BO_ 298 0;
BA_ "GenMsgCycleTime" BO_ 298 100;
BA_ "GenMsgStartDelayTime" BO_ 298 40;
BA_ "MessageSubnet" BO_ 298 2;
BA_ "GenMsgSendType" BO_ 1322 0;
BA_ "GenMsgCycleTime" BO_ 1322 1000;
BA_ "GenMsgStartDelayTime" BO_ 1322 40;
BA_ "MessageSubnet" BO_ 1322 2;
BA_ "DiagResponse" BO_ 1601 1;
BA_ "MessageSubnet" BO_ 1601 2;
BA_ "GenMsgSendType" BO_ 1300 0;
BA_ "GenMsgCycleTime" BO_ 1300 1000;
BA_ "GenMsgStartDelayTime" BO_ 1300 70;
BA_ "MessageSubnet" BO_ 1300 2;
BA_ "GenMsgSendType" BO_ 288 0;
BA_ "GenMsgCycleTime" BO_ 288 1000;
BA_ "GenMsgStartDelayTime" BO_ 288 10;
BA_ "MessageSubnet" BO_ 288 2;
BA_ "GenMsgSendType" BO_ 1009 0;
BA_ "GenMsgCycleTime" BO_ 1009 250;
BA_ "GenMsgStartDelayTime" BO_ 1009 10;
BA_ "MessageSubnet" BO_ 1009 2;
BA_ "GenMsgSendType" BO_ 1257 0;
BA_ "GenMsgCycleTime" BO_ 1257 1000;
BA_ "GenMsgStartDelayTime" BO_ 1257 10;
BA_ "MessageSubnet" BO_ 1257 2;
BA_ "GenMsgSendType" BO_ 505 0;
BA_ "GenMsgCycleTime" BO_ 505 30;
BA_ "GenMsgStartDelayTime" BO_ 505 20;
BA_ "MessageSubnet" BO_ 505 2;
BA_ "GenMsgSendType" BO_ 497 0;
BA_ "GenMsgCycleTime" BO_ 497 100;
BA_ "GenMsgDelayTime" BO_ 497 30;
BA_ "GenMsgStartDelayTime" BO_ 497 10;
BA_ "MessageSubnet" BO_ 497 2;
BA_ "GenMsgSendType" BO_ 969 0;
BA_ "GenMsgCycleTime" BO_ 969 100;
BA_ "GenMsgStartDelayTime" BO_ 969 20;
BA_ "MessageSubnet" BO_ 969 2;
BA_ "GenMsgSendType" BO_ 1249 0;
BA_ "GenMsgCycleTime" BO_ 1249 1000;
BA_ "GenMsgStartDelayTime" BO_ 1249 60;
BA_ "MessageSubnet" BO_ 1249 2;
BA_ "GenMsgSendType" BO_ 481 0;
BA_ "GenMsgCycleTime" BO_ 481 30;
BA_ "GenMsgStartDelayTime" BO_ 481 10;
BA_ "MessageSubnet" BO_ 481 2;
BA_ "GenMsgSendType" BO_ 241 0;
BA_ "GenMsgCycleTime" BO_ 241 10;
BA_ "MessageSubnet" BO_ 241 2;
BA_ "SignalLongName" SG_ 313 LnchCtrlRelLnLockReqd "Launch Control Release Line Lock Requested";
BA_ "SignalType" SG_ 313 LnchCtrlRelLnLockReqd "BLN";
BA_ "VNSigAllNodes" SG_ 313 LnchCtrlRelLnLockReqd 1;
BA_ "GenSigSendType" SG_ 313 LnchCtrlRelLnLockReqd 10;
BA_ "SignalLongName" SG_ 313 VehStbEnhmntCurStRq "Vehicle Stability Enhancement Current State Request";
BA_ "SignalType" SG_ 313 VehStbEnhmntCurStRq "ENM";
BA_ "VNSigAllNodes" SG_ 313 VehStbEnhmntCurStRq 1;
BA_ "GenSigSendType" SG_ 313 VehStbEnhmntCurStRq 10;
BA_ "SignalLongName" SG_ 313 TCSysCurStReq "Traction Control System Current State Request";
BA_ "SignalType" SG_ 313 TCSysCurStReq "ENM";
BA_ "VNSigAllNodes" SG_ 313 TCSysCurStReq 1;
BA_ "GenSigSendType" SG_ 313 TCSysCurStReq 10;
BA_ "SignalLongName" SG_ 313 DrvrDrOpenSwVDA "Driver Door Open Switch Virtual Device Availability";
BA_ "SignalType" SG_ 313 DrvrDrOpenSwVDA "ENM";
BA_ "VNSigAllNodes" SG_ 313 DrvrDrOpenSwVDA 1;
BA_ "SignalLongName" SG_ 313 DrDoorOpenSwActV "Driver Door Open Switch Active Validity";
BA_ "SignalType" SG_ 313 DrDoorOpenSwActV "ENM";
BA_ "VNSigAllNodes" SG_ 313 DrDoorOpenSwActV 1;
BA_ "GenSigSendType" SG_ 313 DrDoorOpenSwActV 10;
BA_ "SignalLongName" SG_ 313 DrDoorOpenSwAct "Driver Door Open Switch Active";
BA_ "SignalType" SG_ 313 DrDoorOpenSwAct "BLN";
BA_ "VNSigAllNodes" SG_ 313 DrDoorOpenSwAct 1;
BA_ "GenSigSendType" SG_ 313 DrDoorOpenSwAct 10;
BA_ "GenSigSendOnInit" SG_ 313 DrDoorOpenSwAct 1;
BA_ "SignalLongName" SG_ 313 LnchCtrlWhlSlpReq "Launch Control Wheel Slip Request";
BA_ "SignalType" SG_ 313 LnchCtrlWhlSlpReq "ENM";
BA_ "VNSigAllNodes" SG_ 313 LnchCtrlWhlSlpReq 1;
BA_ "GenSigSendType" SG_ 313 LnchCtrlWhlSlpReq 10;
BA_ "SignalLongName" SG_ 313 LnchCtrlMdReq "Launch Control Mode Request";
BA_ "SignalType" SG_ 313 LnchCtrlMdReq "ENM";
BA_ "VNSigAllNodes" SG_ 313 LnchCtrlMdReq 1;
BA_ "GenSigSendType" SG_ 313 LnchCtrlMdReq 10;
BA_ "SignalLongName" SG_ 313 LnchCtrlEngRPMReq "Launch Control Engine RPM Request";
BA_ "SignalType" SG_ 313 LnchCtrlEngRPMReq "ENM";
BA_ "VNSigAllNodes" SG_ 313 LnchCtrlEngRPMReq 1;
BA_ "GenSigSendType" SG_ 313 LnchCtrlEngRPMReq 10;
BA_ "SignalLongName" SG_ 313 ExtHlStrAssCsStRq "Extended Hill Start Assist Customization Setting Request";
BA_ "SignalType" SG_ 313 ExtHlStrAssCsStRq "ENM";
BA_ "VNSigAllNodes" SG_ 313 ExtHlStrAssCsStRq 1;
BA_ "GenSigSendType" SG_ 313 ExtHlStrAssCsStRq 10;
BA_ "GenSigSendOnInit" SG_ 313 ExtHlStrAssCsStRq 1;
BA_ "SignalLongName" SG_ 313 DrvStyPerfMdCsStReq "Driving Style Performance Mode Customization Setting Request";
BA_ "SignalType" SG_ 313 DrvStyPerfMdCsStReq "ENM";
BA_ "VNSigAllNodes" SG_ 313 DrvStyPerfMdCsStReq 1;
BA_ "GenSigSendType" SG_ 313 DrvStyPerfMdCsStReq 10;
BA_ "SignalLongName" SG_ 313 PsngStPerfMdCsStReq "Passenger Seat Performance Mode Customization Setting Request";
BA_ "SignalType" SG_ 313 PsngStPerfMdCsStReq "ENM";
BA_ "VNSigAllNodes" SG_ 313 PsngStPerfMdCsStReq 1;
BA_ "GenSigSendType" SG_ 313 PsngStPerfMdCsStReq 10;
BA_ "SignalLongName" SG_ 313 DrvrStPerfMdCsStReq "Driver Seat Performance Mode Customization Setting Request";
BA_ "SignalType" SG_ 313 DrvrStPerfMdCsStReq "ENM";
BA_ "VNSigAllNodes" SG_ 313 DrvrStPerfMdCsStReq 1;
BA_ "GenSigSendType" SG_ 313 DrvrStPerfMdCsStReq 10;
BA_ "SignalLongName" SG_ 313 ACCPerfMdCsStReq "Adaptive Cruise Control Performance Mode Customization Setting Request";
BA_ "SignalType" SG_ 313 ACCPerfMdCsStReq "ENM";
BA_ "VNSigAllNodes" SG_ 313 ACCPerfMdCsStReq 1;
BA_ "GenSigSendType" SG_ 313 ACCPerfMdCsStReq 10;
BA_ "SignalLongName" SG_ 313 PrkAstAdvSysAct "Parking Assistance Advanced  System Active";
BA_ "SignalType" SG_ 313 PrkAstAdvSysAct "BLN";
BA_ "VNSigAllNodes" SG_ 313 PrkAstAdvSysAct 1;
BA_ "GenSigSendType" SG_ 313 PrkAstAdvSysAct 10;
BA_ "SignalLongName" SG_ 313 SndPerfMdCsStRq "Sound Performance Mode Customization Setting Request";
BA_ "SignalType" SG_ 313 SndPerfMdCsStRq "ENM";
BA_ "VNSigAllNodes" SG_ 313 SndPerfMdCsStRq 1;
BA_ "GenSigSendType" SG_ 313 SndPerfMdCsStRq 10;
BA_ "SignalLongName" SG_ 313 HptcStVbnStat "Haptic Seat Vibration Status";
BA_ "SignalType" SG_ 313 HptcStVbnStat "ENM";
BA_ "VNSigAllNodes" SG_ 313 HptcStVbnStat 1;
BA_ "GenSigSendType" SG_ 313 HptcStVbnStat 10;
BA_ "SignalLongName" SG_ 313 ACCSettingType "Adaptive Cruise Control Setting Type";
BA_ "SignalType" SG_ 313 ACCSettingType "ENM";
BA_ "VNSigAllNodes" SG_ 313 ACCSettingType 1;
BA_ "GenSigSendType" SG_ 313 ACCSettingType 10;
BA_ "SignalLongName" SG_ 313 FCABrkPrflReq "Forward Collision Alert Brake Prefill Request";
BA_ "SignalType" SG_ 313 FCABrkPrflReq "BLN";
BA_ "VNSigAllNodes" SG_ 313 FCABrkPrflReq 1;
BA_ "GenSigSendType" SG_ 313 FCABrkPrflReq 10;
BA_ "SignalLongName" SG_ 313 ISA2CCC_ScndCdChr "International Standard Alpha 2 Coded Country Code : Second Code Character";
BA_ "PacketOrder" SG_ 313 ISA2CCC_ScndCdChr 2;
BA_ "SignalType" SG_ 313 ISA2CCC_ScndCdChr "ENM";
BA_ "VNSigAllNodes" SG_ 313 ISA2CCC_ScndCdChr 1;
BA_ "GenSigSendType" SG_ 313 ISA2CCC_ScndCdChr 10;
BA_ "SignalLongName" SG_ 313 ISA2CCC_FrstCdChr "International Standard Alpha 2 Coded Country Code : First Code Character";
BA_ "PacketOrder" SG_ 313 ISA2CCC_FrstCdChr 1;
BA_ "SignalType" SG_ 313 ISA2CCC_FrstCdChr "ENM";
BA_ "VNSigAllNodes" SG_ 313 ISA2CCC_FrstCdChr 1;
BA_ "GenSigSendType" SG_ 313 ISA2CCC_FrstCdChr 10;
BA_ "SignalLongName" SG_ 313 DispPerfMdCsStRq "Display Performance Mode Customization Setting Request";
BA_ "SignalType" SG_ 313 DispPerfMdCsStRq "ENM";
BA_ "VNSigAllNodes" SG_ 313 DispPerfMdCsStRq 1;
BA_ "GenSigSendType" SG_ 313 DispPerfMdCsStRq 10;
BA_ "SignalLongName" SG_ 313 CrshAlrtStPrsnt "Crash Alert Seat Present";
BA_ "SignalType" SG_ 313 CrshAlrtStPrsnt "BLN";
BA_ "VNSigAllNodes" SG_ 313 CrshAlrtStPrsnt 1;
BA_ "GenSigSendType" SG_ 313 CrshAlrtStPrsnt 10;
BA_ "GenSigSendOnInit" SG_ 313 CrshAlrtStPrsnt 1;
BA_ "SignalLongName" SG_ 313 FwdClnAlrtCustStngReq "Forward Collision Alert Customization Setting Request";
BA_ "SignalType" SG_ 313 FwdClnAlrtCustStngReq "ENM";
BA_ "VNSigAllNodes" SG_ 313 FwdClnAlrtCustStngReq 1;
BA_ "GenSigSendType" SG_ 313 FwdClnAlrtCustStngReq 10;
BA_ "GenSigSendOnInit" SG_ 313 FwdClnAlrtCustStngReq 1;
BA_ "SignalLongName" SG_ 313 GNCustStngReq "Go Notifier Customization Setting Request";
BA_ "SignalType" SG_ 313 GNCustStngReq "ENM";
BA_ "VNSigAllNodes" SG_ 313 GNCustStngReq 1;
BA_ "GenSigSendType" SG_ 313 GNCustStngReq 10;
BA_ "GenSigSendOnInit" SG_ 313 GNCustStngReq 1;
BA_ "SignalLongName" SG_ 1328 ACSAlarm9 "Alarm Clock Status : Alarm 9";
BA_ "PacketOrder" SG_ 1328 ACSAlarm9 10;
BA_ "SignalType" SG_ 1328 ACSAlarm9 "ENM";
BA_ "VNSigAllNodes" SG_ 1328 ACSAlarm9 1;
BA_ "GenSigSendType" SG_ 1328 ACSAlarm9 10;
BA_ "SignalLongName" SG_ 1328 ACSAlarm8 "Alarm Clock Status : Alarm 8";
BA_ "PacketOrder" SG_ 1328 ACSAlarm8 9;
BA_ "SignalType" SG_ 1328 ACSAlarm8 "ENM";
BA_ "VNSigAllNodes" SG_ 1328 ACSAlarm8 1;
BA_ "GenSigSendType" SG_ 1328 ACSAlarm8 10;
BA_ "SignalLongName" SG_ 1328 ACSAlarm7 "Alarm Clock Status : Alarm 7";
BA_ "PacketOrder" SG_ 1328 ACSAlarm7 8;
BA_ "SignalType" SG_ 1328 ACSAlarm7 "ENM";
BA_ "VNSigAllNodes" SG_ 1328 ACSAlarm7 1;
BA_ "GenSigSendType" SG_ 1328 ACSAlarm7 10;
BA_ "SignalLongName" SG_ 1328 ACSAlarm6 "Alarm Clock Status : Alarm 6";
BA_ "PacketOrder" SG_ 1328 ACSAlarm6 7;
BA_ "SignalType" SG_ 1328 ACSAlarm6 "ENM";
BA_ "VNSigAllNodes" SG_ 1328 ACSAlarm6 1;
BA_ "GenSigSendType" SG_ 1328 ACSAlarm6 10;
BA_ "SignalLongName" SG_ 1328 ACSAlarm5 "Alarm Clock Status : Alarm 5";
BA_ "PacketOrder" SG_ 1328 ACSAlarm5 6;
BA_ "SignalType" SG_ 1328 ACSAlarm5 "ENM";
BA_ "VNSigAllNodes" SG_ 1328 ACSAlarm5 1;
BA_ "GenSigSendType" SG_ 1328 ACSAlarm5 10;
BA_ "SignalLongName" SG_ 1328 ACSAlarm4 "Alarm Clock Status : Alarm 4";
BA_ "PacketOrder" SG_ 1328 ACSAlarm4 5;
BA_ "SignalType" SG_ 1328 ACSAlarm4 "ENM";
BA_ "VNSigAllNodes" SG_ 1328 ACSAlarm4 1;
BA_ "GenSigSendType" SG_ 1328 ACSAlarm4 10;
BA_ "SignalLongName" SG_ 1328 ACSAlarm3 "Alarm Clock Status : Alarm 3";
BA_ "PacketOrder" SG_ 1328 ACSAlarm3 4;
BA_ "SignalType" SG_ 1328 ACSAlarm3 "ENM";
BA_ "VNSigAllNodes" SG_ 1328 ACSAlarm3 1;
BA_ "GenSigSendType" SG_ 1328 ACSAlarm3 10;
BA_ "SignalLongName" SG_ 1328 ACSAlarm2 "Alarm Clock Status : Alarm 2";
BA_ "PacketOrder" SG_ 1328 ACSAlarm2 3;
BA_ "SignalType" SG_ 1328 ACSAlarm2 "ENM";
BA_ "VNSigAllNodes" SG_ 1328 ACSAlarm2 1;
BA_ "GenSigSendType" SG_ 1328 ACSAlarm2 10;
BA_ "SignalLongName" SG_ 1328 ACSAlarm15 "Alarm Clock Status : Alarm 15";
BA_ "PacketOrder" SG_ 1328 ACSAlarm15 16;
BA_ "SignalType" SG_ 1328 ACSAlarm15 "ENM";
BA_ "VNSigAllNodes" SG_ 1328 ACSAlarm15 1;
BA_ "GenSigSendType" SG_ 1328 ACSAlarm15 10;
BA_ "SignalLongName" SG_ 1328 ACSAlarm14 "Alarm Clock Status : Alarm 14";
BA_ "PacketOrder" SG_ 1328 ACSAlarm14 15;
BA_ "SignalType" SG_ 1328 ACSAlarm14 "ENM";
BA_ "VNSigAllNodes" SG_ 1328 ACSAlarm14 1;
BA_ "GenSigSendType" SG_ 1328 ACSAlarm14 10;
BA_ "SignalLongName" SG_ 1328 ACSAlarm13 "Alarm Clock Status : Alarm 13";
BA_ "PacketOrder" SG_ 1328 ACSAlarm13 14;
BA_ "SignalType" SG_ 1328 ACSAlarm13 "ENM";
BA_ "VNSigAllNodes" SG_ 1328 ACSAlarm13 1;
BA_ "GenSigSendType" SG_ 1328 ACSAlarm13 10;
BA_ "SignalLongName" SG_ 1328 ACSAlarm12 "Alarm Clock Status : Alarm 12";
BA_ "PacketOrder" SG_ 1328 ACSAlarm12 13;
BA_ "SignalType" SG_ 1328 ACSAlarm12 "ENM";
BA_ "VNSigAllNodes" SG_ 1328 ACSAlarm12 1;
BA_ "GenSigSendType" SG_ 1328 ACSAlarm12 10;
BA_ "SignalLongName" SG_ 1328 ACSAlarm11 "Alarm Clock Status : Alarm 11";
BA_ "PacketOrder" SG_ 1328 ACSAlarm11 12;
BA_ "SignalType" SG_ 1328 ACSAlarm11 "ENM";
BA_ "VNSigAllNodes" SG_ 1328 ACSAlarm11 1;
BA_ "GenSigSendType" SG_ 1328 ACSAlarm11 10;
BA_ "SignalLongName" SG_ 1328 ACSAlarm10 "Alarm Clock Status : Alarm 10";
BA_ "PacketOrder" SG_ 1328 ACSAlarm10 11;
BA_ "SignalType" SG_ 1328 ACSAlarm10 "ENM";
BA_ "VNSigAllNodes" SG_ 1328 ACSAlarm10 1;
BA_ "GenSigSendType" SG_ 1328 ACSAlarm10 10;
BA_ "SignalLongName" SG_ 1328 ACSAlarm1 "Alarm Clock Status : Alarm 1";
BA_ "PacketOrder" SG_ 1328 ACSAlarm1 2;
BA_ "SignalType" SG_ 1328 ACSAlarm1 "ENM";
BA_ "VNSigAllNodes" SG_ 1328 ACSAlarm1 1;
BA_ "GenSigSendType" SG_ 1328 ACSAlarm1 10;
BA_ "SignalLongName" SG_ 1328 ACSAlarm0 "Alarm Clock Status : Alarm 0";
BA_ "PacketOrder" SG_ 1328 ACSAlarm0 1;
BA_ "SignalType" SG_ 1328 ACSAlarm0 "ENM";
BA_ "VNSigAllNodes" SG_ 1328 ACSAlarm0 1;
BA_ "GenSigSendType" SG_ 1328 ACSAlarm0 10;
BA_ "SignalLongName" SG_ 311 PsngSysDilPrcs "Positioning System Dilution of Precision";
BA_ "SignalType" SG_ 311 PsngSysDilPrcs "UNM";
BA_ "VNSigAllNodes" SG_ 311 PsngSysDilPrcs 1;
BA_ "GenSigDeltaValue" SG_ 311 PsngSysDilPrcs 10;
BA_ "GenSigSendType" SG_ 311 PsngSysDilPrcs 12;
BA_ "SignalLongName" SG_ 311 Hrs "Hours";
BA_ "SignalType" SG_ 311 Hrs "UNM";
BA_ "VNSigAllNodes" SG_ 311 Hrs 1;
BA_ "GenSigDeltaValue" SG_ 311 Hrs 1;
BA_ "GenSigSendType" SG_ 311 Hrs 12;
BA_ "GenSigSendOnInit" SG_ 311 Hrs 1;
BA_ "SignalLongName" SG_ 311 PsngSysHding "Positioning System Heading";
BA_ "SignalType" SG_ 311 PsngSysHding "UNM";
BA_ "VNSigAllNodes" SG_ 311 PsngSysHding 1;
BA_ "GenSigDeltaValue" SG_ 311 PsngSysHding 50;
BA_ "GenSigSendType" SG_ 311 PsngSysHding 12;
BA_ "SignalLongName" SG_ 311 PsngSysElvtn "Positioning System Elevation";
BA_ "SignalType" SG_ 311 PsngSysElvtn "UNM";
BA_ "VNSigAllNodes" SG_ 311 PsngSysElvtn 1;
BA_ "GenSigDeltaValue" SG_ 311 PsngSysElvtn 100;
BA_ "GenSigSendType" SG_ 311 PsngSysElvtn 12;
BA_ "SignalLongName" SG_ 311 PsngSysHdingV "Positioning System Heading Validity";
BA_ "SignalType" SG_ 311 PsngSysHdingV "ENM";
BA_ "VNSigAllNodes" SG_ 311 PsngSysHdingV 1;
BA_ "GenSigSendType" SG_ 311 PsngSysHdingV 10;
BA_ "SignalLongName" SG_ 311 HrsV "Hours Validity";
BA_ "SignalType" SG_ 311 HrsV "ENM";
BA_ "VNSigAllNodes" SG_ 311 HrsV 1;
BA_ "GenSigSendType" SG_ 311 HrsV 10;
BA_ "GenSigSendOnInit" SG_ 311 HrsV 1;
BA_ "SignalLongName" SG_ 311 MinsV "Minutes Validity";
BA_ "SignalType" SG_ 311 MinsV "ENM";
BA_ "VNSigAllNodes" SG_ 311 MinsV 1;
BA_ "GenSigSendType" SG_ 311 MinsV 10;
BA_ "GenSigSendOnInit" SG_ 311 MinsV 1;
BA_ "SignalLongName" SG_ 311 Mins "Minutes";
BA_ "SignalType" SG_ 311 Mins "UNM";
BA_ "VNSigAllNodes" SG_ 311 Mins 1;
BA_ "GenSigDeltaValue" SG_ 311 Mins 1;
BA_ "GenSigSendType" SG_ 311 Mins 12;
BA_ "GenSigSendOnInit" SG_ 311 Mins 1;
BA_ "SignalLongName" SG_ 311 PsngSysDilPrcsV "Positioning System Dilution of Precision Validity";
BA_ "SignalType" SG_ 311 PsngSysDilPrcsV "ENM";
BA_ "VNSigAllNodes" SG_ 311 PsngSysDilPrcsV 1;
BA_ "GenSigSendType" SG_ 311 PsngSysDilPrcsV 10;
BA_ "SignalLongName" SG_ 311 PsngSysElvtnV "Positioning System Elevation Validity";
BA_ "SignalType" SG_ 311 PsngSysElvtnV "ENM";
BA_ "VNSigAllNodes" SG_ 311 PsngSysElvtnV 1;
BA_ "GenSigSendType" SG_ 311 PsngSysElvtnV 10;
BA_ "SignalLongName" SG_ 311 VehSpeSta "Vehicle Speed State";
BA_ "SignalType" SG_ 311 VehSpeSta "ENM";
BA_ "VNSigAllNodes" SG_ 311 VehSpeSta 1;
BA_ "SignalLongName" SG_ 810 PsngSysLongV "Positioning System Longitude Validity";
BA_ "SignalType" SG_ 810 PsngSysLongV "ENM";
BA_ "VNSigAllNodes" SG_ 810 PsngSysLongV 1;
BA_ "GenSigSendType" SG_ 810 PsngSysLongV 10;
BA_ "SignalLongName" SG_ 810 PsngSysLong "Positioning System Longitude";
BA_ "SignalType" SG_ 810 PsngSysLong "SNM";
BA_ "VNSigAllNodes" SG_ 810 PsngSysLong 1;
BA_ "GenSigDeltaValue" SG_ 810 PsngSysLong 10;
BA_ "GenSigSendType" SG_ 810 PsngSysLong 12;
BA_ "SignalLongName" SG_ 810 PsngSysLatV "Positioning System Latitude Validity";
BA_ "SignalType" SG_ 810 PsngSysLatV "ENM";
BA_ "VNSigAllNodes" SG_ 810 PsngSysLatV 1;
BA_ "GenSigSendType" SG_ 810 PsngSysLatV 10;
BA_ "SignalLongName" SG_ 810 PsngSysLat "Positioning System Latitude";
BA_ "SignalType" SG_ 810 PsngSysLat "SNM";
BA_ "VNSigAllNodes" SG_ 810 PsngSysLat 1;
BA_ "GenSigDeltaValue" SG_ 810 PsngSysLat 10;
BA_ "GenSigSendType" SG_ 810 PsngSysLat 12;
BA_ "GenSigSendOnInit" SG_ 810 PsngSysLat 2;
BA_ "SignalLongName" SG_ 304 PedFrndlyAlrtCsStReq "Pedestrian Friendly Alert Customization Setting Request";
BA_ "SignalType" SG_ 304 PedFrndlyAlrtCsStReq "ENM";
BA_ "VNSigAllNodes" SG_ 304 PedFrndlyAlrtCsStReq 1;
BA_ "GenSigSendType" SG_ 304 PedFrndlyAlrtCsStReq 10;
BA_ "SignalLongName" SG_ 304 AlrmStat "Alarm Status";
BA_ "SignalType" SG_ 304 AlrmStat "ENM";
BA_ "VNSigAllNodes" SG_ 304 AlrmStat 1;
BA_ "GenSigSendType" SG_ 304 AlrmStat 10;
BA_ "GenSigSendOnInit" SG_ 304 AlrmStat 2;
BA_ "SignalLongName" SG_ 1105 BrkPdLfSysDrvrRq "Brake Pad Life System Driver Request";
BA_ "SignalType" SG_ 1105 BrkPdLfSysDrvrRq "ENM";
BA_ "VNSigAllNodes" SG_ 1105 BrkPdLfSysDrvrRq 1;
BA_ "GenSigSendType" SG_ 1105 BrkPdLfSysDrvrRq 10;
BA_ "GenSigSendOnInit" SG_ 1105 BrkPdLfSysDrvrRq 1;
BA_ "SignalLongName" SG_ 1105 HybImpSnsDsbld "Hybrid Impact Sensing Disabled";
BA_ "SignalType" SG_ 1105 HybImpSnsDsbld "BLN";
BA_ "VNSigAllNodes" SG_ 1105 HybImpSnsDsbld 1;
BA_ "GenSigSendType" SG_ 1105 HybImpSnsDsbld 10;
BA_ "SignalLongName" SG_ 1105 JmpStrtReq "Jump Start Requested";
BA_ "SignalType" SG_ 1105 JmpStrtReq "BLN";
BA_ "VNSigAllNodes" SG_ 1105 JmpStrtReq 1;
BA_ "GenSigSendType" SG_ 1105 JmpStrtReq 10;
BA_ "GenSigSendOnInit" SG_ 1105 JmpStrtReq 1;
BA_ "SignalLongName" SG_ 1105 HybVehHiVltInvDisRqd "Hybrid Vehicle High Voltage Inverter Disable Requested";
BA_ "SignalType" SG_ 1105 HybVehHiVltInvDisRqd "BLN";
BA_ "VNSigAllNodes" SG_ 1105 HybVehHiVltInvDisRqd 1;
BA_ "GenSigSendType" SG_ 1105 HybVehHiVltInvDisRqd 10;
BA_ "SignalLongName" SG_ 1105 NESSRoSevSt "Notification Event Severity Status : Rollover Severity Achieved";
BA_ "PacketOrder" SG_ 1105 NESSRoSevSt 7;
BA_ "SignalType" SG_ 1105 NESSRoSevSt "BLN";
BA_ "VNSigAllNodes" SG_ 1105 NESSRoSevSt 1;
BA_ "GenSigSendType" SG_ 1105 NESSRoSevSt 10;
BA_ "SignalLongName" SG_ 1105 NESSRiSiSevSt "Notification Event Severity Status : Right Side Severity Achieved";
BA_ "PacketOrder" SG_ 1105 NESSRiSiSevSt 6;
BA_ "SignalType" SG_ 1105 NESSRiSiSevSt "BLN";
BA_ "VNSigAllNodes" SG_ 1105 NESSRiSiSevSt 1;
BA_ "GenSigSendType" SG_ 1105 NESSRiSiSevSt 10;
BA_ "SignalLongName" SG_ 1105 NESSReImpSevSt "Notification Event Severity Status : Rear Impact Severity Achieved";
BA_ "PacketOrder" SG_ 1105 NESSReImpSevSt 5;
BA_ "SignalType" SG_ 1105 NESSReImpSevSt "BLN";
BA_ "VNSigAllNodes" SG_ 1105 NESSReImpSevSt 1;
BA_ "GenSigSendType" SG_ 1105 NESSReImpSevSt 10;
BA_ "SignalLongName" SG_ 1105 NESSLeSiSevSt "Notification Event Severity Status : Left Side Severity Achieved";
BA_ "PacketOrder" SG_ 1105 NESSLeSiSevSt 4;
BA_ "SignalType" SG_ 1105 NESSLeSiSevSt "BLN";
BA_ "VNSigAllNodes" SG_ 1105 NESSLeSiSevSt 1;
BA_ "GenSigSendType" SG_ 1105 NESSLeSiSevSt 10;
BA_ "SignalLongName" SG_ 1105 NESSFrImpSt2SevSt "Notification Event Severity Status : Frontal Impact Stage 2 Severity Achieved";
BA_ "PacketOrder" SG_ 1105 NESSFrImpSt2SevSt 3;
BA_ "SignalType" SG_ 1105 NESSFrImpSt2SevSt "BLN";
BA_ "VNSigAllNodes" SG_ 1105 NESSFrImpSt2SevSt 1;
BA_ "GenSigSendType" SG_ 1105 NESSFrImpSt2SevSt 10;
BA_ "SignalLongName" SG_ 1105 NESSFrImpSt1SevSt "Notification Event Severity Status : Frontal Impact Stage 1 Severity Achieved";
BA_ "PacketOrder" SG_ 1105 NESSFrImpSt1SevSt 2;
BA_ "SignalType" SG_ 1105 NESSFrImpSt1SevSt "BLN";
BA_ "VNSigAllNodes" SG_ 1105 NESSFrImpSt1SevSt 1;
BA_ "GenSigSendType" SG_ 1105 NESSFrImpSt1SevSt 10;
BA_ "SignalLongName" SG_ 1105 NESSFrImpPreSevSt "Notification Event Severity Status : Frontal Impact Pretensioner Severity Achieved";
BA_ "PacketOrder" SG_ 1105 NESSFrImpPreSevSt 1;
BA_ "SignalType" SG_ 1105 NESSFrImpPreSevSt "BLN";
BA_ "VNSigAllNodes" SG_ 1105 NESSFrImpPreSevSt 1;
BA_ "GenSigSendType" SG_ 1105 NESSFrImpPreSevSt 10;
BA_ "SignalLongName" SG_ 1105 ClmCntFrBlwFnSp "Climate Control Front Blower Fan Speed";
BA_ "SignalType" SG_ 1105 ClmCntFrBlwFnSp "UNM";
BA_ "VNSigAllNodes" SG_ 1105 ClmCntFrBlwFnSp 1;
BA_ "GenSigDeltaValue" SG_ 1105 ClmCntFrBlwFnSp 1;
BA_ "GenSigSendType" SG_ 1105 ClmCntFrBlwFnSp 12;
BA_ "GenSigSendOnInit" SG_ 1105 ClmCntFrBlwFnSp 2;
BA_ "SignalLongName" SG_ 1345 DgnInf_HS541 "Diagnostic Information HS541";
BA_ "SignalType" SG_ 1345 DgnInf_HS541 "UNM";
BA_ "VNSigSLHSSharedDiagnostic" SG_ 1345 DgnInf_HS541 1;
BA_ "VNSigAllNodes" SG_ 1345 DgnInf_HS541 1;
BA_ "SignalLongName" SG_ 322 TCSTmpDsblReqConf "Traction Control System Temporary Disable Request Confirmation";
BA_ "SignalType" SG_ 322 TCSTmpDsblReqConf "ENM";
BA_ "VNSigAllNodes" SG_ 322 TCSTmpDsblReqConf 1;
BA_ "GenSigSendType" SG_ 322 TCSTmpDsblReqConf 10;
BA_ "SignalLongName" SG_ 322 VehStbCmptvMdCurStRq "Vehicle Stability Competitive Mode Current State Request";
BA_ "SignalType" SG_ 322 VehStbCmptvMdCurStRq "ENM";
BA_ "VNSigAllNodes" SG_ 322 VehStbCmptvMdCurStRq 1;
BA_ "GenSigSendType" SG_ 322 VehStbCmptvMdCurStRq 10;
BA_ "SignalLongName" SG_ 322 RtLnChngThrtAprchSpd "Right Lane Change Threat Approach Speed";
BA_ "SignalType" SG_ 322 RtLnChngThrtAprchSpd "SNM";
BA_ "VNSigAllNodes" SG_ 322 RtLnChngThrtAprchSpd 1;
BA_ "GenSigDeltaValue" SG_ 322 RtLnChngThrtAprchSpd 1;
BA_ "GenSigSendType" SG_ 322 RtLnChngThrtAprchSpd 12;
BA_ "SignalLongName" SG_ 322 LfLnChngThrtAprchSpd "Left Lane Change Threat Approach Speed";
BA_ "SignalType" SG_ 322 LfLnChngThrtAprchSpd "SNM";
BA_ "VNSigAllNodes" SG_ 322 LfLnChngThrtAprchSpd 1;
BA_ "GenSigDeltaValue" SG_ 322 LfLnChngThrtAprchSpd 1;
BA_ "GenSigSendType" SG_ 322 LfLnChngThrtAprchSpd 12;
BA_ "SignalLongName" SG_ 322 RgtLnChgThrt "Right Lane Change Threat";
BA_ "SignalType" SG_ 322 RgtLnChgThrt "BLN";
BA_ "VNSigAllNodes" SG_ 322 RgtLnChgThrt 1;
BA_ "GenSigSendType" SG_ 322 RgtLnChgThrt 10;
BA_ "GenSigSendOnInit" SG_ 322 RgtLnChgThrt 2;
BA_ "SignalLongName" SG_ 322 LftLnChgThrt "Left Lane Change Threat";
BA_ "SignalType" SG_ 322 LftLnChgThrt "BLN";
BA_ "VNSigAllNodes" SG_ 322 LftLnChgThrt 1;
BA_ "GenSigSendType" SG_ 322 LftLnChgThrt 10;
BA_ "GenSigSendOnInit" SG_ 322 LftLnChgThrt 2;
BA_ "SignalLongName" SG_ 322 IntDimLvl "Interior Dimming Level";
BA_ "SignalType" SG_ 322 IntDimLvl "UNM";
BA_ "VNSigAllNodes" SG_ 322 IntDimLvl 1;
BA_ "GenSigDeltaValue" SG_ 322 IntDimLvl 1;
BA_ "GenSigSendType" SG_ 322 IntDimLvl 12;
BA_ "GenSigSendOnInit" SG_ 322 IntDimLvl 2;
BA_ "SignalLongName" SG_ 322 AFLGPSCstStReq "Adaptive Forward Lighting With GPS Customization Setting Request";
BA_ "SignalType" SG_ 322 AFLGPSCstStReq "ENM";
BA_ "VNSigAllNodes" SG_ 322 AFLGPSCstStReq 1;
BA_ "GenSigSendType" SG_ 322 AFLGPSCstStReq 10;
BA_ "SignalLongName" SG_ 322 AFLCstStReq "Adaptive Forward Lighting Customization Setting Request";
BA_ "SignalType" SG_ 322 AFLCstStReq "ENM";
BA_ "VNSigAllNodes" SG_ 322 AFLCstStReq 1;
BA_ "GenSigSendType" SG_ 322 AFLCstStReq 10;
BA_ "SignalLongName" SG_ 322 LtRtHnTrCstStReq "Left Right Hand Traffic Customization Setting Request";
BA_ "SignalType" SG_ 322 LtRtHnTrCstStReq "ENM";
BA_ "VNSigAllNodes" SG_ 322 LtRtHnTrCstStReq 1;
BA_ "GenSigSendType" SG_ 322 LtRtHnTrCstStReq 10;
BA_ "SignalLongName" SG_ 322 AdpHgBmAsSnCsStRq "Adaptive High Beam Assist With Sensitivity Customization Setting Request";
BA_ "SignalType" SG_ 322 AdpHgBmAsSnCsStRq "ENM";
BA_ "VNSigAllNodes" SG_ 322 AdpHgBmAsSnCsStRq 1;
BA_ "GenSigSendType" SG_ 322 AdpHgBmAsSnCsStRq 10;
BA_ "SignalLongName" SG_ 322 AdpHgBmAstCstStRq "Adaptive High Beam Assist Customization Setting Request";
BA_ "SignalType" SG_ 322 AdpHgBmAstCstStRq "ENM";
BA_ "VNSigAllNodes" SG_ 322 AdpHgBmAstCstStRq 1;
BA_ "GenSigSendType" SG_ 322 AdpHgBmAstCstStRq 10;
BA_ "SignalLongName" SG_ 322 LtRtHnTrGPSCstStRq "Left Right Hand Traffic With GPS Customization Setting Request";
BA_ "SignalType" SG_ 322 LtRtHnTrGPSCstStRq "ENM";
BA_ "VNSigAllNodes" SG_ 322 LtRtHnTrGPSCstStRq 1;
BA_ "GenSigSendType" SG_ 322 LtRtHnTrGPSCstStRq 10;
BA_ "SignalLongName" SG_ 322 AutHgBmAsSnCsStRq "Auto High Beam Assist With Sensitivity Customization Setting Request";
BA_ "SignalType" SG_ 322 AutHgBmAsSnCsStRq "ENM";
BA_ "VNSigAllNodes" SG_ 322 AutHgBmAsSnCsStRq 1;
BA_ "GenSigSendType" SG_ 322 AutHgBmAsSnCsStRq 10;
BA_ "SignalLongName" SG_ 322 AutHgBmAstCstStRq "Auto High Beam Assist Customization Setting Request";
BA_ "SignalType" SG_ 322 AutHgBmAstCstStRq "ENM";
BA_ "VNSigAllNodes" SG_ 322 AutHgBmAstCstStRq 1;
BA_ "GenSigSendType" SG_ 322 AutHgBmAstCstStRq 10;
BA_ "SignalLongName" SG_ 322 HtVwAutnmsEPBAplyReqd "Hitch View Autonomous Electric Park Brake Apply Requested";
BA_ "SignalType" SG_ 322 HtVwAutnmsEPBAplyReqd "BLN";
BA_ "VNSigAllNodes" SG_ 322 HtVwAutnmsEPBAplyReqd 1;
BA_ "GenSigSendType" SG_ 322 HtVwAutnmsEPBAplyReqd 10;
BA_ "SignalLongName" SG_ 309 PedFrndlyAlrtSndMnAct "Pedestrian Friendly Alert Sound Manual Activation";
BA_ "SignalType" SG_ 309 PedFrndlyAlrtSndMnAct "BLN";
BA_ "VNSigAllNodes" SG_ 309 PedFrndlyAlrtSndMnAct 1;
BA_ "SignalLongName" SG_ 309 StBltTgtCSRq "Seat Belt Tightening Customize Setting Request";
BA_ "SignalType" SG_ 309 StBltTgtCSRq "ENM";
BA_ "VNSigAllNodes" SG_ 309 StBltTgtCSRq 1;
BA_ "GenSigSendType" SG_ 309 StBltTgtCSRq 10;
BA_ "GenSigSendOnInit" SG_ 309 StBltTgtCSRq 1;
BA_ "SignalLongName" SG_ 309 ColPrSysCustReq "Collision Preparation System Customization Setting Request";
BA_ "SignalType" SG_ 309 ColPrSysCustReq "ENM";
BA_ "VNSigAllNodes" SG_ 309 ColPrSysCustReq 1;
BA_ "GenSigSendType" SG_ 309 ColPrSysCustReq 10;
BA_ "GenSigSendOnInit" SG_ 309 ColPrSysCustReq 1;
BA_ "SignalLongName" SG_ 309 SecV "Seconds Validity";
BA_ "SignalType" SG_ 309 SecV "ENM";
BA_ "VNSigAllNodes" SG_ 309 SecV 1;
BA_ "GenSigSendType" SG_ 309 SecV 10;
BA_ "GenSigSendOnInit" SG_ 309 SecV 1;
BA_ "SignalLongName" SG_ 309 Sec "Seconds";
BA_ "SignalType" SG_ 309 Sec "UNM";
BA_ "VNSigAllNodes" SG_ 309 Sec 1;
BA_ "GenSigDeltaValue" SG_ 309 Sec 1;
BA_ "GenSigSendType" SG_ 309 Sec 12;
BA_ "GenSigSendOnInit" SG_ 309 Sec 1;
BA_ "SignalLongName" SG_ 309 CldrYr_154 "Calendar Year";
BA_ "SignalType" SG_ 309 CldrYr_154 "UNM";
BA_ "VNSigAllNodes" SG_ 309 CldrYr_154 1;
BA_ "GenSigDeltaValue" SG_ 309 CldrYr_154 1;
BA_ "GenSigSendType" SG_ 309 CldrYr_154 12;
BA_ "GenSigSendOnInit" SG_ 309 CldrYr_154 1;
BA_ "SignalLongName" SG_ 309 CldrYr "Calendar Year";
BA_ "SignalType" SG_ 309 CldrYr "UNM";
BA_ "VNSigAllNodes" SG_ 309 CldrYr 1;
BA_ "GenSigDeltaValue" SG_ 309 CldrYr 1;
BA_ "GenSigSendType" SG_ 309 CldrYr 12;
BA_ "GenSigSendOnInit" SG_ 309 CldrYr 1;
BA_ "SignalLongName" SG_ 309 CldrMth_154 "Calendar Month";
BA_ "SignalType" SG_ 309 CldrMth_154 "ENM";
BA_ "VNSigAllNodes" SG_ 309 CldrMth_154 1;
BA_ "GenSigSendType" SG_ 309 CldrMth_154 10;
BA_ "GenSigSendOnInit" SG_ 309 CldrMth_154 1;
BA_ "SignalLongName" SG_ 309 CldrMth "Calendar Month";
BA_ "SignalType" SG_ 309 CldrMth "ENM";
BA_ "VNSigAllNodes" SG_ 309 CldrMth 1;
BA_ "GenSigSendType" SG_ 309 CldrMth 10;
BA_ "GenSigSendOnInit" SG_ 309 CldrMth 1;
BA_ "SignalLongName" SG_ 309 CldrDay_154 "Calendar Day";
BA_ "SignalType" SG_ 309 CldrDay_154 "UNM";
BA_ "VNSigAllNodes" SG_ 309 CldrDay_154 1;
BA_ "GenSigDeltaValue" SG_ 309 CldrDay_154 1;
BA_ "GenSigSendType" SG_ 309 CldrDay_154 12;
BA_ "GenSigSendOnInit" SG_ 309 CldrDay_154 1;
BA_ "SignalLongName" SG_ 309 CldrDay "Calendar Day";
BA_ "SignalType" SG_ 309 CldrDay "UNM";
BA_ "VNSigAllNodes" SG_ 309 CldrDay 1;
BA_ "GenSigDeltaValue" SG_ 309 CldrDay 1;
BA_ "GenSigSendType" SG_ 309 CldrDay 12;
BA_ "GenSigSendOnInit" SG_ 309 CldrDay 1;
BA_ "GenSigStartValue" SG_ 309 AutoHiBmVDA 1;
BA_ "SignalLongName" SG_ 309 AutoHiBmVDA "Automatic High Beam Virtual Device Availability";
BA_ "SignalType" SG_ 309 AutoHiBmVDA "ENM";
BA_ "VNSigAllNodes" SG_ 309 AutoHiBmVDA 1;
BA_ "SignalLongName" SG_ 309 CtLghtDet "City Light Detected";
BA_ "SignalType" SG_ 309 CtLghtDet "BLN";
BA_ "VNSigAllNodes" SG_ 309 CtLghtDet 1;
BA_ "GenSigSendType" SG_ 309 CtLghtDet 10;
BA_ "GenSigSendOnInit" SG_ 309 CtLghtDet 2;
BA_ "GenSigStartValue" SG_ 309 RrClosVDA 1;
BA_ "SignalLongName" SG_ 309 RrClosVDA "Rear Closure Virtual Device Availability";
BA_ "SignalType" SG_ 309 RrClosVDA "ENM";
BA_ "VNSigAllNodes" SG_ 309 RrClosVDA 1;
BA_ "SignalLongName" SG_ 309 TCSysDisSwAtv "Traction Control System Disable Switch Active";
BA_ "SignalType" SG_ 309 TCSysDisSwAtv "BLN";
BA_ "VNSigAllNodes" SG_ 309 TCSysDisSwAtv 1;
BA_ "SignalLongName" SG_ 309 VehMovState "Vehicle Movement State";
BA_ "SignalType" SG_ 309 VehMovState "ENM";
BA_ "VNSigAllNodes" SG_ 309 VehMovState 1;
BA_ "GenSigSendType" SG_ 309 VehMovState 10;
BA_ "GenSigSendOnInit" SG_ 309 VehMovState 1;
BA_ "SignalLongName" SG_ 309 TCSysDisSwAtvV "Traction Control System Disable Switch Active Validity";
BA_ "SignalType" SG_ 309 TCSysDisSwAtvV "ENM";
BA_ "VNSigAllNodes" SG_ 309 TCSysDisSwAtvV 1;
BA_ "SignalLongName" SG_ 309 HillDesCtrlMdSwActV "Hill Descent Control Mode Switch Active Validity";
BA_ "SignalType" SG_ 309 HillDesCtrlMdSwActV "ENM";
BA_ "VNSigAllNodes" SG_ 309 HillDesCtrlMdSwActV 1;
BA_ "SignalLongName" SG_ 309 WSWshSwAtv "Windshield Washer Switch Active";
BA_ "SignalType" SG_ 309 WSWshSwAtv "BLN";
BA_ "VNSigAllNodes" SG_ 309 WSWshSwAtv 1;
BA_ "GenSigSendType" SG_ 309 WSWshSwAtv 10;
BA_ "SignalLongName" SG_ 309 HillDesCtrlMdSwAct "Hill Descent Control Mode Switch Active";
BA_ "SignalType" SG_ 309 HillDesCtrlMdSwAct "BLN";
BA_ "VNSigAllNodes" SG_ 309 HillDesCtrlMdSwAct 1;
BA_ "SignalLongName" SG_ 309 RrClosAjarSwAct "Rear Closure Ajar Switch Active";
BA_ "SignalType" SG_ 309 RrClosAjarSwAct "BLN";
BA_ "VNSigAllNodes" SG_ 309 RrClosAjarSwAct 1;
BA_ "GenSigSendType" SG_ 309 RrClosAjarSwAct 10;
BA_ "GenSigSendOnInit" SG_ 309 RrClosAjarSwAct 1;
BA_ "SignalLongName" SG_ 309 WSWprAct "Windshield Wiper Active";
BA_ "SignalType" SG_ 309 WSWprAct "BLN";
BA_ "VNSigAllNodes" SG_ 309 WSWprAct 1;
BA_ "GenSigSendType" SG_ 309 WSWprAct 10;
BA_ "SignalLongName" SG_ 352 ShfFrmPrkAlwd "Shift From Park Allowed";
BA_ "SignalType" SG_ 352 ShfFrmPrkAlwd "BLN";
BA_ "VNSigAllNodes" SG_ 352 ShfFrmPrkAlwd 1;
BA_ "SignalLongName" SG_ 352 AVHSwtchStats "Auto Vehicle Hold Switch Status";
BA_ "SignalType" SG_ 352 AVHSwtchStats "ENM";
BA_ "VNSigAllNodes" SG_ 352 AVHSwtchStats 1;
BA_ "SignalLongName" SG_ 352 SmrtHgBmAstCstCurrSetVal "Smart High Beam Assist Customization Current Setting Value";
BA_ "SignalType" SG_ 352 SmrtHgBmAstCstCurrSetVal "ENM";
BA_ "VNSigAllNodes" SG_ 352 SmrtHgBmAstCstCurrSetVal 1;
BA_ "GenSigSendType" SG_ 352 SmrtHgBmAstCstCurrSetVal 10;
BA_ "GenSigSendOnInit" SG_ 352 SmrtHgBmAstCstCurrSetVal 2;
BA_ "SignalLongName" SG_ 352 TeenDrvAct "Teen Driver Active";
BA_ "SignalType" SG_ 352 TeenDrvAct "BLN";
BA_ "VNSigAllNodes" SG_ 352 TeenDrvAct 1;
BA_ "GenSigSendType" SG_ 352 TeenDrvAct 10;
BA_ "GenSigSendOnInit" SG_ 352 TeenDrvAct 2;
BA_ "SignalLongName" SG_ 352 LrnEnvIdSt "Learn Environment Identification Status";
BA_ "SignalType" SG_ 352 LrnEnvIdSt "ENM";
BA_ "VNSigAllNodes" SG_ 352 LrnEnvIdSt 1;
BA_ "GenSigSendOnInit" SG_ 352 LrnEnvIdSt 2;
BA_ "SignalLongName" SG_ 352 LrnEnvId "Learn Environment Identification";
BA_ "SignalType" SG_ 352 LrnEnvId "UNM";
BA_ "VNSigAllNodes" SG_ 352 LrnEnvId 1;
BA_ "GenSigSendOnInit" SG_ 352 LrnEnvId 2;
BA_ "SignalLongName" SG_ 352 ImoId "Immobilizer Identifier";
BA_ "SignalType" SG_ 352 ImoId "UNM";
BA_ "VNSigAllNodes" SG_ 352 ImoId 1;
BA_ "GenSigSendOnInit" SG_ 352 ImoId 2;
BA_ "SignalLongName" SG_ 352 ImoIdSt "Immobilizer Identifier Status";
BA_ "SignalType" SG_ 352 ImoIdSt "ENM";
BA_ "VNSigAllNodes" SG_ 352 ImoIdSt 1;
BA_ "GenSigSendOnInit" SG_ 352 ImoIdSt 2;
BA_ "SignalLongName" SG_ 320 Ky_IdDevPrgmAuthReq "Key / Identification Device Programming Authentication Requested";
BA_ "SignalType" SG_ 320 Ky_IdDevPrgmAuthReq "BLN";
BA_ "VNSigAllNodes" SG_ 320 Ky_IdDevPrgmAuthReq 1;
BA_ "GenSigSendType" SG_ 320 Ky_IdDevPrgmAuthReq 10;
BA_ "SignalLongName" SG_ 320 ClmnLckStatV "Column Lock Status Validity";
BA_ "SignalType" SG_ 320 ClmnLckStatV "ENM";
BA_ "VNSigAllNodes" SG_ 320 ClmnLckStatV 1;
BA_ "GenSigSendType" SG_ 320 ClmnLckStatV 10;
BA_ "SignalLongName" SG_ 320 ClmnLckStat "Column Lock Status";
BA_ "SignalType" SG_ 320 ClmnLckStat "ENM";
BA_ "VNSigAllNodes" SG_ 320 ClmnLckStat 1;
BA_ "GenSigSendType" SG_ 320 ClmnLckStat 10;
BA_ "GenSigSendOnInit" SG_ 320 ClmnLckStat 2;
BA_ "SignalLongName" SG_ 320 AutoBmSlctAllwd "Automatic Beam Select Allowed";
BA_ "SignalType" SG_ 320 AutoBmSlctAllwd "BLN";
BA_ "VNSigAllNodes" SG_ 320 AutoBmSlctAllwd 1;
BA_ "GenSigSendType" SG_ 320 AutoBmSlctAllwd 10;
BA_ "GenSigSendOnInit" SG_ 320 AutoBmSlctAllwd 2;
BA_ "SignalLongName" SG_ 320 BrkLtsAtv "Brake Lights Active";
BA_ "SignalType" SG_ 320 BrkLtsAtv "BLN";
BA_ "VNSigAllNodes" SG_ 320 BrkLtsAtv 1;
BA_ "GenSigSendType" SG_ 320 BrkLtsAtv 10;
BA_ "GenSigSendOnInit" SG_ 320 BrkLtsAtv 1;
BA_ "SignalLongName" SG_ 320 TrnSwAct "Turn Switch Activation";
BA_ "SignalType" SG_ 320 TrnSwAct "ENM";
BA_ "VNSigAllNodes" SG_ 320 TrnSwAct 1;
BA_ "GenSigSendType" SG_ 320 TrnSwAct 10;
BA_ "GenSigSendOnInit" SG_ 320 TrnSwAct 1;
BA_ "SignalLongName" SG_ 320 RrFogLmpsAct "Rear Fog Lamps Active";
BA_ "SignalType" SG_ 320 RrFogLmpsAct "BLN";
BA_ "VNSigAllNodes" SG_ 320 RrFogLmpsAct 1;
BA_ "GenSigSendType" SG_ 320 RrFogLmpsAct 10;
BA_ "GenSigSendOnInit" SG_ 320 RrFogLmpsAct 1;
BA_ "SignalLongName" SG_ 320 OtsdAmbtLtLvlStatV "Outside Ambient Light Level Status Validity";
BA_ "SignalType" SG_ 320 OtsdAmbtLtLvlStatV "ENM";
BA_ "VNSigAllNodes" SG_ 320 OtsdAmbtLtLvlStatV 1;
BA_ "GenSigSendType" SG_ 320 OtsdAmbtLtLvlStatV 10;
BA_ "SignalLongName" SG_ 320 OtsdAmbtLtLvlStat "Outside Ambient Light Level Status";
BA_ "SignalType" SG_ 320 OtsdAmbtLtLvlStat "ENM";
BA_ "VNSigAllNodes" SG_ 320 OtsdAmbtLtLvlStat 1;
BA_ "GenSigSendType" SG_ 320 OtsdAmbtLtLvlStat 10;
BA_ "SignalLongName" SG_ 320 MainLghtSw "Main Light Switch";
BA_ "SignalType" SG_ 320 MainLghtSw "ENM";
BA_ "VNSigAllNodes" SG_ 320 MainLghtSw 1;
BA_ "GenSigSendType" SG_ 320 MainLghtSw 10;
BA_ "GenSigSendOnInit" SG_ 320 MainLghtSw 1;
BA_ "SignalLongName" SG_ 320 LowBmAct "Low Beam Active";
BA_ "SignalType" SG_ 320 LowBmAct "BLN";
BA_ "VNSigAllNodes" SG_ 320 LowBmAct 1;
BA_ "GenSigSendType" SG_ 320 LowBmAct 10;
BA_ "SignalLongName" SG_ 320 HighBmAct "High Beam Active";
BA_ "SignalType" SG_ 320 HighBmAct "BLN";
BA_ "VNSigAllNodes" SG_ 320 HighBmAct 1;
BA_ "GenSigSendType" SG_ 320 HighBmAct 10;
BA_ "SignalLongName" SG_ 320 HdlmpBmSelectStat "Headlamp Beam Select Status";
BA_ "SignalType" SG_ 320 HdlmpBmSelectStat "ENM";
BA_ "VNSigAllNodes" SG_ 320 HdlmpBmSelectStat 1;
BA_ "GenSigSendType" SG_ 320 HdlmpBmSelectStat 10;
BA_ "GenSigSendOnInit" SG_ 320 HdlmpBmSelectStat 1;
BA_ "SignalLongName" SG_ 320 FlToPsSwAtv "Flash To Pass Switch Active";
BA_ "SignalType" SG_ 320 FlToPsSwAtv "BLN";
BA_ "VNSigAllNodes" SG_ 320 FlToPsSwAtv 1;
BA_ "GenSigSendType" SG_ 320 FlToPsSwAtv 10;
BA_ "SignalLongName" SG_ 320 AdvFrntLghtSysEnbld "Advanced Front Lighting System Enabled";
BA_ "SignalType" SG_ 320 AdvFrntLghtSysEnbld "BLN";
BA_ "VNSigAllNodes" SG_ 320 AdvFrntLghtSysEnbld 1;
BA_ "GenSigSendType" SG_ 320 AdvFrntLghtSysEnbld 10;
BA_ "SignalLongName" SG_ 320 FrFogLmpsAct "Front Fog Lamps Active";
BA_ "SignalType" SG_ 320 FrFogLmpsAct "BLN";
BA_ "VNSigAllNodes" SG_ 320 FrFogLmpsAct 1;
BA_ "GenSigSendType" SG_ 320 FrFogLmpsAct 10;
BA_ "SignalLongName" SG_ 320 AutLghtCtrl "Auto Light Control";
BA_ "SignalType" SG_ 320 AutLghtCtrl "BLN";
BA_ "VNSigAllNodes" SG_ 320 AutLghtCtrl 1;
BA_ "GenSigSendType" SG_ 320 AutLghtCtrl 10;
BA_ "SignalLongName" SG_ 2041 PCUInfo_7F9 "Pyrotechnical Control Unit Information 7F9";
BA_ "SignalType" SG_ 2041 PCUInfo_7F9 "UNM";
BA_ "VNSigAllNodes" SG_ 2041 PCUInfo_7F9 1;
BA_ "GenSigDeltaValue" SG_ 2041 PCUInfo_7F9 1;
BA_ "GenSigSendType" SG_ 2041 PCUInfo_7F9 12;
BA_ "SignalLongName" SG_ 499 PTShftPtrnOvrdAct "Powertrain Shift Pattern Override Active";
BA_ "SignalType" SG_ 499 PTShftPtrnOvrdAct "BLN";
BA_ "VNSigAllNodes" SG_ 499 PTShftPtrnOvrdAct 1;
BA_ "SignalLongName" SG_ 499 PFTrnsTUDSecSwSt "Platform Transmission Tap Up/Down Secondary Switch State";
BA_ "SignalType" SG_ 499 PFTrnsTUDSecSwSt "ENM";
BA_ "VNSigAllNodes" SG_ 499 PFTrnsTUDSecSwSt 1;
BA_ "SignalLongName" SG_ 499 TrnsPFShftPattSwARC "Transmission Platform Shift Pattern Switch Alive Rolling Count";
BA_ "SignalType" SG_ 499 TrnsPFShftPattSwARC "UNM";
BA_ "VNSigAllNodes" SG_ 499 TrnsPFShftPattSwARC 1;
BA_ "SignalLongName" SG_ 499 TrnsPFShftPattSw4Act "Transmission Platform Shift Pattern Switch 4 Active";
BA_ "SignalType" SG_ 499 TrnsPFShftPattSw4Act "BLN";
BA_ "VNSigAllNodes" SG_ 499 TrnsPFShftPattSw4Act 1;
BA_ "SignalLongName" SG_ 499 TrnsPFShftPattSw3Act "Transmission Platform Shift Pattern Switch 3 Active";
BA_ "SignalType" SG_ 499 TrnsPFShftPattSw3Act "BLN";
BA_ "VNSigAllNodes" SG_ 499 TrnsPFShftPattSw3Act 1;
BA_ "SignalLongName" SG_ 499 TrnsPFShftPattSw2Act "Transmission Platform Shift Pattern Switch 2 Active";
BA_ "SignalType" SG_ 499 TrnsPFShftPattSw2Act "BLN";
BA_ "VNSigAllNodes" SG_ 499 TrnsPFShftPattSw2Act 1;
BA_ "SignalLongName" SG_ 499 TrnsPFShftPattSw1Act "Transmission Platform Shift Pattern Switch 1 Active";
BA_ "SignalType" SG_ 499 TrnsPFShftPattSw1Act "BLN";
BA_ "VNSigAllNodes" SG_ 499 TrnsPFShftPattSw1Act 1;
BA_ "SignalLongName" SG_ 499 PFTrnsTUDSwStAlvRC "Platform Transmission Tap Up/Down Switch Status Alive Rolling Count";
BA_ "SignalType" SG_ 499 PFTrnsTUDSwStAlvRC "UNM";
BA_ "VNSigAllNodes" SG_ 499 PFTrnsTUDSwStAlvRC 1;
BA_ "SignalLongName" SG_ 499 PFTrnsTUDSwSt "Platform Transmission Tap Up/Down Switch State";
BA_ "SignalType" SG_ 499 PFTrnsTUDSwSt "ENM";
BA_ "VNSigAllNodes" SG_ 499 PFTrnsTUDSwSt 1;
BA_ "SignalLongName" SG_ 499 PFTrnsTUDEnSwSt "Platform Transmission Tap Up/Down Enable Switch State";
BA_ "SignalType" SG_ 499 PFTrnsTUDEnSwSt "ENM";
BA_ "VNSigAllNodes" SG_ 499 PFTrnsTUDEnSwSt 1;
BA_ "SignalLongName" SG_ 499 OvrdrvDsblReqd "Overdrive Disable Requested";
BA_ "SignalType" SG_ 499 OvrdrvDsblReqd "BLN";
BA_ "VNSigAllNodes" SG_ 499 OvrdrvDsblReqd 1;
BA_ "SignalLongName" SG_ 298 DrvrDrAjrSwVDA "Driver Door Ajar Switch Virtual Device Availability";
BA_ "SignalType" SG_ 298 DrvrDrAjrSwVDA "ENM";
BA_ "VNSigAllNodes" SG_ 298 DrvrDrAjrSwVDA 1;
BA_ "SignalLongName" SG_ 298 ValetMdAct "Valet Mode Active";
BA_ "SignalType" SG_ 298 ValetMdAct "BLN";
BA_ "VNSigAllNodes" SG_ 298 ValetMdAct 1;
BA_ "GenSigSendType" SG_ 298 ValetMdAct 10;
BA_ "SignalLongName" SG_ 298 AutoMdSpdLmtCnfrmd "Auto Mode Speed Limit Confirmed";
BA_ "SignalType" SG_ 298 AutoMdSpdLmtCnfrmd "BLN";
BA_ "VNSigAllNodes" SG_ 298 AutoMdSpdLmtCnfrmd 1;
BA_ "GenSigSendType" SG_ 298 AutoMdSpdLmtCnfrmd 10;
BA_ "SignalLongName" SG_ 298 TCSysDisSwAtvARC "Traction Control System Disable Switch Active Alive Rolling Count";
BA_ "SignalType" SG_ 298 TCSysDisSwAtvARC "UNM";
BA_ "VNSigAllNodes" SG_ 298 TCSysDisSwAtvARC 1;
BA_ "SignalLongName" SG_ 298 TCSysDisSwAtv_12A "Traction Control System Disable Switch Active";
BA_ "SignalType" SG_ 298 TCSysDisSwAtv_12A "BLN";
BA_ "VNSigAllNodes" SG_ 298 TCSysDisSwAtv_12A 1;
BA_ "SignalLongName" SG_ 298 ChmAct "Chime Active";
BA_ "SignalType" SG_ 298 ChmAct "BLN";
BA_ "VNSigAllNodes" SG_ 298 ChmAct 1;
BA_ "GenSigSendType" SG_ 298 ChmAct 10;
BA_ "GenSigSendOnInit" SG_ 298 ChmAct 1;
BA_ "SignalLongName" SG_ 298 Ky_IdDevPr "Key / Identification Device Present";
BA_ "SignalType" SG_ 298 Ky_IdDevPr "BLN";
BA_ "VNSigAllNodes" SG_ 298 Ky_IdDevPr 1;
BA_ "GenSigSendType" SG_ 298 Ky_IdDevPr 10;
BA_ "GenSigSendOnInit" SG_ 298 Ky_IdDevPr 1;
BA_ "SignalLongName" SG_ 298 DDAjrSwAtvM "Driver Door Ajar Switch Active Mask";
BA_ "SignalType" SG_ 298 DDAjrSwAtvM "ENM";
BA_ "VNSigAllNodes" SG_ 298 DDAjrSwAtvM 1;
BA_ "GenSigSendType" SG_ 298 DDAjrSwAtvM 10;
BA_ "SignalLongName" SG_ 298 CrshAlrtDrvrSlctdType "Crash Alert Driver Selected Type";
BA_ "SignalType" SG_ 298 CrshAlrtDrvrSlctdType "ENM";
BA_ "VNSigAllNodes" SG_ 298 CrshAlrtDrvrSlctdType 1;
BA_ "GenSigSendType" SG_ 298 CrshAlrtDrvrSlctdType 10;
BA_ "GenSigSendOnInit" SG_ 298 CrshAlrtDrvrSlctdType 1;
BA_ "SignalLongName" SG_ 298 PsSbltAtcV "Passenger Seatbelt Attached Validity";
BA_ "SignalType" SG_ 298 PsSbltAtcV "ENM";
BA_ "VNSigAllNodes" SG_ 298 PsSbltAtcV 1;
BA_ "GenSigSendType" SG_ 298 PsSbltAtcV 10;
BA_ "GenSigSendOnInit" SG_ 298 PsSbltAtcV 2;
BA_ "SignalLongName" SG_ 298 PsSbltAtc "Passenger Seatbelt Attached";
BA_ "SignalType" SG_ 298 PsSbltAtc "BLN";
BA_ "VNSigAllNodes" SG_ 298 PsSbltAtc 1;
BA_ "GenSigSendType" SG_ 298 PsSbltAtc 10;
BA_ "GenSigSendOnInit" SG_ 298 PsSbltAtc 2;
BA_ "SignalLongName" SG_ 298 TrlrBrkDsplyAct "Trailer Brake Display Active";
BA_ "SignalType" SG_ 298 TrlrBrkDsplyAct "BLN";
BA_ "VNSigAllNodes" SG_ 298 TrlrBrkDsplyAct 1;
BA_ "GenSigSendType" SG_ 298 TrlrBrkDsplyAct 10;
BA_ "GenSigSendOnInit" SG_ 298 TrlrBrkDsplyAct 1;
BA_ "SignalLongName" SG_ 298 RdSpdCatType "Road Speed Category Type";
BA_ "SignalType" SG_ 298 RdSpdCatType "ENM";
BA_ "VNSigAllNodes" SG_ 298 RdSpdCatType 1;
BA_ "GenSigSendType" SG_ 298 RdSpdCatType 10;
BA_ "GenSigSendOnInit" SG_ 298 RdSpdCatType 1;
BA_ "SignalLongName" SG_ 298 LnCat "Lane Category";
BA_ "SignalType" SG_ 298 LnCat "ENM";
BA_ "VNSigAllNodes" SG_ 298 LnCat 1;
BA_ "GenSigSendType" SG_ 298 LnCat 10;
BA_ "GenSigSendOnInit" SG_ 298 LnCat 1;
BA_ "SignalLongName" SG_ 298 FncRdClass "Functional Road Class";
BA_ "SignalType" SG_ 298 FncRdClass "ENM";
BA_ "VNSigAllNodes" SG_ 298 FncRdClass 1;
BA_ "GenSigSendType" SG_ 298 FncRdClass 10;
BA_ "GenSigSendOnInit" SG_ 298 FncRdClass 1;
BA_ "SignalLongName" SG_ 298 SprtLnRd "Separate Lane Road";
BA_ "SignalType" SG_ 298 SprtLnRd "BLN";
BA_ "VNSigAllNodes" SG_ 298 SprtLnRd 1;
BA_ "GenSigSendType" SG_ 298 SprtLnRd 10;
BA_ "GenSigSendOnInit" SG_ 298 SprtLnRd 1;
BA_ "SignalLongName" SG_ 298 CntrldAccRd "Controlled Access Road";
BA_ "SignalType" SG_ 298 CntrldAccRd "BLN";
BA_ "VNSigAllNodes" SG_ 298 CntrldAccRd 1;
BA_ "GenSigSendType" SG_ 298 CntrldAccRd 10;
BA_ "GenSigSendOnInit" SG_ 298 CntrldAccRd 1;
BA_ "SignalLongName" SG_ 298 BldUpArDet "Build Up Area Detected";
BA_ "SignalType" SG_ 298 BldUpArDet "BLN";
BA_ "VNSigAllNodes" SG_ 298 BldUpArDet 1;
BA_ "GenSigSendType" SG_ 298 BldUpArDet 10;
BA_ "GenSigSendOnInit" SG_ 298 BldUpArDet 1;
BA_ "SignalLongName" SG_ 298 MpDataAvlbl "Map Data Available";
BA_ "SignalType" SG_ 298 MpDataAvlbl "BLN";
BA_ "VNSigAllNodes" SG_ 298 MpDataAvlbl 1;
BA_ "GenSigSendType" SG_ 298 MpDataAvlbl 10;
BA_ "GenSigSendOnInit" SG_ 298 MpDataAvlbl 1;
BA_ "SignalLongName" SG_ 298 SusCustStngReq "Suspension Customization Setting Request";
BA_ "SignalType" SG_ 298 SusCustStngReq "ENM";
BA_ "VNSigAllNodes" SG_ 298 SusCustStngReq 1;
BA_ "GenSigSendType" SG_ 298 SusCustStngReq 10;
BA_ "GenSigSendOnInit" SG_ 298 SusCustStngReq 1;
BA_ "SignalLongName" SG_ 298 StrCustStngReq "Steering Customization Setting Request";
BA_ "SignalType" SG_ 298 StrCustStngReq "ENM";
BA_ "VNSigAllNodes" SG_ 298 StrCustStngReq 1;
BA_ "GenSigSendType" SG_ 298 StrCustStngReq 10;
BA_ "GenSigSendOnInit" SG_ 298 StrCustStngReq 1;
BA_ "SignalLongName" SG_ 298 RstrCustFctrDef "Restore Customization Factory Defaults";
BA_ "SignalType" SG_ 298 RstrCustFctrDef "ENM";
BA_ "VNSigAllNodes" SG_ 298 RstrCustFctrDef 1;
BA_ "GenSigSendType" SG_ 298 RstrCustFctrDef 10;
BA_ "GenSigSendOnInit" SG_ 298 RstrCustFctrDef 1;
BA_ "SignalLongName" SG_ 298 DrvlnCustStngReq "Driveline Customization Setting Request";
BA_ "SignalType" SG_ 298 DrvlnCustStngReq "ENM";
BA_ "VNSigAllNodes" SG_ 298 DrvlnCustStngReq 1;
BA_ "GenSigSendType" SG_ 298 DrvlnCustStngReq 10;
BA_ "GenSigSendOnInit" SG_ 298 DrvlnCustStngReq 1;
BA_ "GenSigStartValue" SG_ 298 ChmMstrVDA 1;
BA_ "SignalLongName" SG_ 298 ChmMstrVDA "Chime Master Virtual Device Availability";
BA_ "SignalType" SG_ 298 ChmMstrVDA "ENM";
BA_ "VNSigAllNodes" SG_ 298 ChmMstrVDA 1;
BA_ "GenSigStartValue" SG_ 298 IPCVDA 1;
BA_ "SignalLongName" SG_ 298 IPCVDA "Instrument Panel Cluster Virtual Device Availability";
BA_ "SignalType" SG_ 298 IPCVDA "ENM";
BA_ "VNSigAllNodes" SG_ 298 IPCVDA 1;
BA_ "GenSigStartValue" SG_ 298 HeadUpDispVDA 1;
BA_ "SignalLongName" SG_ 298 HeadUpDispVDA "Head Up Display Virtual Device Availability";
BA_ "SignalType" SG_ 298 HeadUpDispVDA "ENM";
BA_ "VNSigAllNodes" SG_ 298 HeadUpDispVDA 1;
BA_ "GenSigStartValue" SG_ 298 HapticSeatVDA 1;
BA_ "SignalLongName" SG_ 298 HapticSeatVDA "Haptic Seat Virtual Device Availability";
BA_ "SignalType" SG_ 298 HapticSeatVDA "ENM";
BA_ "VNSigAllNodes" SG_ 298 HapticSeatVDA 1;
BA_ "SignalLongName" SG_ 298 RRDoorAjarSwAct "Rear Right Door Ajar Switch Active";
BA_ "SignalType" SG_ 298 RRDoorAjarSwAct "BLN";
BA_ "VNSigAllNodes" SG_ 298 RRDoorAjarSwAct 1;
BA_ "GenSigSendType" SG_ 298 RRDoorAjarSwAct 10;
BA_ "GenSigSendOnInit" SG_ 298 RRDoorAjarSwAct 2;
BA_ "SignalLongName" SG_ 298 PDAjrSwAtv "Passenger Door Ajar Switch Active";
BA_ "SignalType" SG_ 298 PDAjrSwAtv "BLN";
BA_ "VNSigAllNodes" SG_ 298 PDAjrSwAtv 1;
BA_ "GenSigSendType" SG_ 298 PDAjrSwAtv 10;
BA_ "GenSigSendOnInit" SG_ 298 PDAjrSwAtv 2;
BA_ "SignalLongName" SG_ 298 DDAjrSwAtv "Driver Door Ajar Switch Active";
BA_ "SignalType" SG_ 298 DDAjrSwAtv "BLN";
BA_ "VNSigAllNodes" SG_ 298 DDAjrSwAtv 1;
BA_ "GenSigSendType" SG_ 298 DDAjrSwAtv 10;
BA_ "GenSigSendOnInit" SG_ 298 DDAjrSwAtv 2;
BA_ "GenSigStartValue" SG_ 298 TrlrHWIntrfcVDA 1;
BA_ "SignalLongName" SG_ 298 TrlrHWIntrfcVDA "Trailer Hardware Interface Virtual Device Availability";
BA_ "SignalType" SG_ 298 TrlrHWIntrfcVDA "ENM";
BA_ "VNSigAllNodes" SG_ 298 TrlrHWIntrfcVDA 1;
BA_ "GenSigStartValue" SG_ 298 DrId 7;
BA_ "SignalLongName" SG_ 298 DrId "Driver Identifier";
BA_ "SignalType" SG_ 298 DrId "ENM";
BA_ "VNSigAllNodes" SG_ 298 DrId 1;
BA_ "GenSigSendType" SG_ 298 DrId 10;
BA_ "GenSigSendOnInit" SG_ 298 DrId 1;
BA_ "SignalLongName" SG_ 298 EnrgMgtLdShdRq "Energy Management Load Shedding Request";
BA_ "SignalType" SG_ 298 EnrgMgtLdShdRq "ENM";
BA_ "VNSigAllNodes" SG_ 298 EnrgMgtLdShdRq 1;
BA_ "SignalLongName" SG_ 298 DrSbltAtcV "Driver Seatbelt Attached Validity";
BA_ "SignalType" SG_ 298 DrSbltAtcV "ENM";
BA_ "VNSigAllNodes" SG_ 298 DrSbltAtcV 1;
BA_ "GenSigSendType" SG_ 298 DrSbltAtcV 10;
BA_ "SignalLongName" SG_ 298 TrlrHtchSwAtv "Trailer Hitch Switch Active";
BA_ "SignalType" SG_ 298 TrlrHtchSwAtv "BLN";
BA_ "VNSigAllNodes" SG_ 298 TrlrHtchSwAtv 1;
BA_ "GenSigSendType" SG_ 298 TrlrHtchSwAtv 10;
BA_ "GenSigSendOnInit" SG_ 298 TrlrHtchSwAtv 2;
BA_ "SignalLongName" SG_ 298 TreInfMonSysRstReq "Tire Inflation Monitoring System Reset Requested";
BA_ "SignalType" SG_ 298 TreInfMonSysRstReq "BLN";
BA_ "VNSigAllNodes" SG_ 298 TreInfMonSysRstReq 1;
BA_ "GenSigSendType" SG_ 298 TreInfMonSysRstReq 10;
BA_ "SignalLongName" SG_ 298 HUDActv "Head Up Display Active";
BA_ "SignalType" SG_ 298 HUDActv "BLN";
BA_ "VNSigAllNodes" SG_ 298 HUDActv 1;
BA_ "GenSigSendType" SG_ 298 HUDActv 10;
BA_ "SignalLongName" SG_ 298 BatVltV "Battery Voltage Validity";
BA_ "SignalType" SG_ 298 BatVltV "ENM";
BA_ "VNSigAllNodes" SG_ 298 BatVltV 1;
BA_ "SignalLongName" SG_ 298 BatVlt "Battery Voltage";
BA_ "SignalType" SG_ 298 BatVlt "UNM";
BA_ "VNSigAllNodes" SG_ 298 BatVlt 1;
BA_ "SignalLongName" SG_ 298 RLDoorAjarSwAct "Rear Left Door Ajar Switch Active";
BA_ "SignalType" SG_ 298 RLDoorAjarSwAct "BLN";
BA_ "VNSigAllNodes" SG_ 298 RLDoorAjarSwAct 1;
BA_ "GenSigSendType" SG_ 298 RLDoorAjarSwAct 10;
BA_ "GenSigSendOnInit" SG_ 298 RLDoorAjarSwAct 2;
BA_ "SignalLongName" SG_ 298 DrSbltAtc "Driver Seatbelt Attached";
BA_ "SignalType" SG_ 298 DrSbltAtc "BLN";
BA_ "VNSigAllNodes" SG_ 298 DrSbltAtc 1;
BA_ "GenSigSendType" SG_ 298 DrSbltAtc 10;
BA_ "SignalLongName" SG_ 1322 TireRRPrsV "Tire Right Rear Pressure Validity";
BA_ "SignalType" SG_ 1322 TireRRPrsV "ENM";
BA_ "VNSigAllNodes" SG_ 1322 TireRRPrsV 1;
BA_ "GenSigSendType" SG_ 1322 TireRRPrsV 10;
BA_ "GenSigSendOnInit" SG_ 1322 TireRRPrsV 1;
BA_ "SignalLongName" SG_ 1322 TireRRPrsStat "Tire Right Rear Pressure Status";
BA_ "SignalType" SG_ 1322 TireRRPrsStat "ENM";
BA_ "VNSigAllNodes" SG_ 1322 TireRRPrsStat 1;
BA_ "GenSigSendType" SG_ 1322 TireRRPrsStat 10;
BA_ "GenSigSendOnInit" SG_ 1322 TireRRPrsStat 1;
BA_ "GenSigStartValue" SG_ 1322 TireRRPrs 255;
BA_ "SignalLongName" SG_ 1322 TireRRPrs "Tire Right Rear Pressure";
BA_ "SignalType" SG_ 1322 TireRRPrs "UNM";
BA_ "VNSigAllNodes" SG_ 1322 TireRRPrs 1;
BA_ "GenSigDeltaValue" SG_ 1322 TireRRPrs 1;
BA_ "GenSigSendType" SG_ 1322 TireRRPrs 12;
BA_ "GenSigSendOnInit" SG_ 1322 TireRRPrs 1;
BA_ "SignalLongName" SG_ 1322 TireRFPrsV "Tire Right Front Pressure Validity";
BA_ "SignalType" SG_ 1322 TireRFPrsV "ENM";
BA_ "VNSigAllNodes" SG_ 1322 TireRFPrsV 1;
BA_ "GenSigSendType" SG_ 1322 TireRFPrsV 10;
BA_ "GenSigSendOnInit" SG_ 1322 TireRFPrsV 1;
BA_ "SignalLongName" SG_ 1322 TireRFPrsStat "Tire Right Front Pressure Status";
BA_ "SignalType" SG_ 1322 TireRFPrsStat "ENM";
BA_ "VNSigAllNodes" SG_ 1322 TireRFPrsStat 1;
BA_ "GenSigSendType" SG_ 1322 TireRFPrsStat 10;
BA_ "GenSigSendOnInit" SG_ 1322 TireRFPrsStat 1;
BA_ "GenSigStartValue" SG_ 1322 TireRFPrs 255;
BA_ "SignalLongName" SG_ 1322 TireRFPrs "Tire Right Front Pressure";
BA_ "SignalType" SG_ 1322 TireRFPrs "UNM";
BA_ "VNSigAllNodes" SG_ 1322 TireRFPrs 1;
BA_ "GenSigDeltaValue" SG_ 1322 TireRFPrs 1;
BA_ "GenSigSendType" SG_ 1322 TireRFPrs 12;
BA_ "GenSigSendOnInit" SG_ 1322 TireRFPrs 1;
BA_ "SignalLongName" SG_ 1322 TireLRPrsV "Tire Left Rear Pressure Validity";
BA_ "SignalType" SG_ 1322 TireLRPrsV "ENM";
BA_ "VNSigAllNodes" SG_ 1322 TireLRPrsV 1;
BA_ "GenSigSendType" SG_ 1322 TireLRPrsV 10;
BA_ "GenSigSendOnInit" SG_ 1322 TireLRPrsV 1;
BA_ "SignalLongName" SG_ 1322 TireLRPrsStat "Tire Left Rear Pressure Status";
BA_ "SignalType" SG_ 1322 TireLRPrsStat "ENM";
BA_ "VNSigAllNodes" SG_ 1322 TireLRPrsStat 1;
BA_ "GenSigSendType" SG_ 1322 TireLRPrsStat 10;
BA_ "GenSigSendOnInit" SG_ 1322 TireLRPrsStat 1;
BA_ "GenSigStartValue" SG_ 1322 TireLRPrs 255;
BA_ "SignalLongName" SG_ 1322 TireLRPrs "Tire Left Rear Pressure";
BA_ "SignalType" SG_ 1322 TireLRPrs "UNM";
BA_ "VNSigAllNodes" SG_ 1322 TireLRPrs 1;
BA_ "GenSigDeltaValue" SG_ 1322 TireLRPrs 1;
BA_ "GenSigSendType" SG_ 1322 TireLRPrs 12;
BA_ "GenSigSendOnInit" SG_ 1322 TireLRPrs 1;
BA_ "SignalLongName" SG_ 1322 TireLFPrsV "Tire Left Front Pressure Validity";
BA_ "SignalType" SG_ 1322 TireLFPrsV "ENM";
BA_ "VNSigAllNodes" SG_ 1322 TireLFPrsV 1;
BA_ "GenSigSendType" SG_ 1322 TireLFPrsV 10;
BA_ "GenSigSendOnInit" SG_ 1322 TireLFPrsV 1;
BA_ "SignalLongName" SG_ 1322 TireLFPrsStat "Tire Left Front Pressure Status";
BA_ "SignalType" SG_ 1322 TireLFPrsStat "ENM";
BA_ "VNSigAllNodes" SG_ 1322 TireLFPrsStat 1;
BA_ "GenSigSendType" SG_ 1322 TireLFPrsStat 10;
BA_ "GenSigSendOnInit" SG_ 1322 TireLFPrsStat 1;
BA_ "GenSigStartValue" SG_ 1322 TireLFPrs 255;
BA_ "SignalLongName" SG_ 1322 TireLFPrs "Tire Left Front Pressure";
BA_ "SignalType" SG_ 1322 TireLFPrs "UNM";
BA_ "VNSigAllNodes" SG_ 1322 TireLFPrs 1;
BA_ "GenSigDeltaValue" SG_ 1322 TireLFPrs 1;
BA_ "GenSigSendType" SG_ 1322 TireLFPrs 12;
BA_ "GenSigSendOnInit" SG_ 1322 TireLFPrs 1;
BA_ "SignalLongName" SG_ 1601 DgnInf "Diagnostic Information";
BA_ "SignalType" SG_ 1601 DgnInf "UNM";
BA_ "VNSigSLHSSharedDiagnostic" SG_ 1601 DgnInf 1;
BA_ "VNSigAllNodes" SG_ 1601 DgnInf 1;
BA_ "GenSigDeltaValue" SG_ 1601 DgnInf 1;
BA_ "GenSigSendType" SG_ 1601 DgnInf 12;
BA_ "SignalLongName" SG_ 1300 VehIdNmDig2_9 "Vehicle Identification Number Digits 2-9";
BA_ "SignalType" SG_ 1300 VehIdNmDig2_9 "ASC";
BA_ "VNSigAllNodes" SG_ 1300 VehIdNmDig2_9 1;
BA_ "GenSigSendOnInit" SG_ 1300 VehIdNmDig2_9 2;
BA_ "SignalLongName" SG_ 288 VehOdo "Vehicle Odometer";
BA_ "SignalType" SG_ 288 VehOdo "UNM";
BA_ "VNSigAllNodes" SG_ 288 VehOdo 1;
BA_ "SignalLongName" SG_ 288 VehOdoV "Vehicle Odometer Validity";
BA_ "SignalType" SG_ 288 VehOdoV "ENM";
BA_ "VNSigAllNodes" SG_ 288 VehOdoV 1;
BA_ "SignalLongName" SG_ 1009 EngAirFltMonDrvrReq "Engine Air Filter Monitor Driver Request";
BA_ "SignalType" SG_ 1009 EngAirFltMonDrvrReq "ENM";
BA_ "VNSigAllNodes" SG_ 1009 EngAirFltMonDrvrReq 1;
BA_ "GenSigSendType" SG_ 1009 EngAirFltMonDrvrReq 10;
BA_ "SignalLongName" SG_ 1009 RstrctdPTOpModeReqd "Restricted Powertrain Operation Mode Requested";
BA_ "SignalType" SG_ 1009 RstrctdPTOpModeReqd "BLN";
BA_ "VNSigAllNodes" SG_ 1009 RstrctdPTOpModeReqd 1;
BA_ "SignalLongName" SG_ 1009 ClmtCtrlHtrEngRunRq "Climate Control Heater Engine Run Request";
BA_ "SignalType" SG_ 1009 ClmtCtrlHtrEngRunRq "ENM";
BA_ "VNSigAllNodes" SG_ 1009 ClmtCtrlHtrEngRunRq 1;
BA_ "GenSigSendType" SG_ 1009 ClmtCtrlHtrEngRunRq 10;
BA_ "SignalLongName" SG_ 1009 OtsAirTmpCrValMsk "Outside Air Temperature Corrected Value Mask";
BA_ "SignalType" SG_ 1009 OtsAirTmpCrValMsk "ENM";
BA_ "VNSigAllNodes" SG_ 1009 OtsAirTmpCrValMsk 1;
BA_ "GenSigSendType" SG_ 1009 OtsAirTmpCrValMsk 10;
BA_ "SignalLongName" SG_ 1009 ACCmEngRunReq "Air Conditioning Compressor Engine Run Request";
BA_ "SignalType" SG_ 1009 ACCmEngRunReq "ENM";
BA_ "VNSigAllNodes" SG_ 1009 ACCmEngRunReq 1;
BA_ "GenSigSendType" SG_ 1009 ACCmEngRunReq 10;
BA_ "GenSigStartValue" SG_ 1009 OutAirTempVDA 1;
BA_ "SignalLongName" SG_ 1009 OutAirTempVDA "Outside Air Temperature Virtual Device Availability";
BA_ "SignalType" SG_ 1009 OutAirTempVDA "ENM";
BA_ "VNSigAllNodes" SG_ 1009 OutAirTempVDA 1;
BA_ "SignalLongName" SG_ 1009 OtsAirTmpCrValV "Outside Air Temperature Corrected Value Validity";
BA_ "SignalType" SG_ 1009 OtsAirTmpCrValV "ENM";
BA_ "VNSigAllNodes" SG_ 1009 OtsAirTmpCrValV 1;
BA_ "GenSigSendType" SG_ 1009 OtsAirTmpCrValV 10;
BA_ "SignalLongName" SG_ 1009 OtsAirTmpCrVal "Outside Air Temperature Corrected Value";
BA_ "SignalType" SG_ 1009 OtsAirTmpCrVal "UNM";
BA_ "VNSigAllNodes" SG_ 1009 OtsAirTmpCrVal 1;
BA_ "GenSigDeltaValue" SG_ 1009 OtsAirTmpCrVal 1;
BA_ "GenSigSendType" SG_ 1009 OtsAirTmpCrVal 12;
BA_ "GenSigSendOnInit" SG_ 1009 OtsAirTmpCrVal 1;
BA_ "GenSigStartValue" SG_ 1009 EngOffTmVDA 1;
BA_ "SignalLongName" SG_ 1009 EngOffTmVDA "Engine Off Time Virtual Device Availability";
BA_ "SignalType" SG_ 1009 EngOffTmVDA "ENM";
BA_ "VNSigAllNodes" SG_ 1009 EngOffTmVDA 1;
BA_ "SignalLongName" SG_ 1009 ClntCircPmpRq "Coolant Circulation Pump Request";
BA_ "SignalType" SG_ 1009 ClntCircPmpRq "ENM";
BA_ "VNSigAllNodes" SG_ 1009 ClntCircPmpRq 1;
BA_ "GenSigSendType" SG_ 1009 ClntCircPmpRq 10;
BA_ "GenSigSendOnInit" SG_ 1009 ClntCircPmpRq 2;
BA_ "SignalLongName" SG_ 1009 IntDimDspLvl "Interior Dimming Display Level";
BA_ "SignalType" SG_ 1009 IntDimDspLvl "UNM";
BA_ "VNSigAllNodes" SG_ 1009 IntDimDspLvl 1;
BA_ "GenSigDeltaValue" SG_ 1009 IntDimDspLvl 1;
BA_ "GenSigSendType" SG_ 1009 IntDimDspLvl 12;
BA_ "GenSigSendOnInit" SG_ 1009 IntDimDspLvl 2;
BA_ "SignalLongName" SG_ 1009 EngOffTmExtRngV "Engine Off Time Extended Range Validity";
BA_ "SignalType" SG_ 1009 EngOffTmExtRngV "ENM";
BA_ "VNSigAllNodes" SG_ 1009 EngOffTmExtRngV 1;
BA_ "GenSigSendType" SG_ 1009 EngOffTmExtRngV 10;
BA_ "SignalLongName" SG_ 1009 EngOffTmExtRng "Engine Off Time Extended Range";
BA_ "SignalType" SG_ 1009 EngOffTmExtRng "UNM";
BA_ "VNSigAllNodes" SG_ 1009 EngOffTmExtRng 1;
BA_ "GenSigDeltaValue" SG_ 1009 EngOffTmExtRng 1;
BA_ "GenSigSendType" SG_ 1009 EngOffTmExtRng 12;
BA_ "GenSigSendOnInit" SG_ 1009 EngOffTmExtRng 2;
BA_ "SignalLongName" SG_ 1009 PF_MinIdlBstLvlReq "Platform Minimum Idle Boost Level Request";
BA_ "SignalType" SG_ 1009 PF_MinIdlBstLvlReq "ENM";
BA_ "VNSigAllNodes" SG_ 1009 PF_MinIdlBstLvlReq 1;
BA_ "SignalLongName" SG_ 1009 GenRgSPDtyCycRq "Generator Regulator Setpoint Duty Cycle Request";
BA_ "SignalType" SG_ 1009 GenRgSPDtyCycRq "UNM";
BA_ "VNSigAllNodes" SG_ 1009 GenRgSPDtyCycRq 1;
BA_ "SignalLongName" SG_ 1009 VehTopSpdLmtReq "Vehicle Top Speed Limit Request";
BA_ "SignalType" SG_ 1009 VehTopSpdLmtReq "UNM";
BA_ "VNSigAllNodes" SG_ 1009 VehTopSpdLmtReq 1;
BA_ "SignalLongName" SG_ 1257 EngPrfID "Engine Performance Identifier";
BA_ "SignalType" SG_ 1257 EngPrfID "UNM";
BA_ "VNSigAllNodes" SG_ 1257 EngPrfID 1;
BA_ "SignalLongName" SG_ 1257 ElpsdTimeCntRstOcc "Elapsed Time Count Reset Occurred";
BA_ "SignalType" SG_ 1257 ElpsdTimeCntRstOcc "BLN";
BA_ "VNSigAllNodes" SG_ 1257 ElpsdTimeCntRstOcc 1;
BA_ "GenSigSendType" SG_ 1257 ElpsdTimeCntRstOcc 10;
BA_ "SignalLongName" SG_ 1257 ElpsdTimeCnt "Elapsed Time Count";
BA_ "SignalType" SG_ 1257 ElpsdTimeCnt "UNM";
BA_ "VNSigAllNodes" SG_ 1257 ElpsdTimeCnt 1;
BA_ "GenSigDeltaValue" SG_ 1257 ElpsdTimeCnt 1;
BA_ "GenSigSendType" SG_ 1257 ElpsdTimeCnt 12;
BA_ "SignalLongName" SG_ 1257 VSESysPrs "Vehicle Stability Enhancement System Present";
BA_ "SignalType" SG_ 1257 VSESysPrs "BLN";
BA_ "VNSigAllNodes" SG_ 1257 VSESysPrs 1;
BA_ "SignalLongName" SG_ 1257 ABSPr "Antilock Brake System Present";
BA_ "SignalType" SG_ 1257 ABSPr "BLN";
BA_ "VNSigAllNodes" SG_ 1257 ABSPr 1;
BA_ "SignalLongName" SG_ 1257 TCSysPr "Traction Control System Present";
BA_ "SignalType" SG_ 1257 TCSysPr "BLN";
BA_ "VNSigAllNodes" SG_ 1257 TCSysPr 1;
BA_ "SignalLongName" SG_ 1257 VehSpdCntlSystmType "Vehicle Speed Control System Type";
BA_ "SignalType" SG_ 1257 VehSpdCntlSystmType "ENM";
BA_ "VNSigAllNodes" SG_ 1257 VehSpdCntlSystmType 1;
BA_ "GenSigSendType" SG_ 1257 VehSpdCntlSystmType 10;
BA_ "SignalLongName" SG_ 1257 PltfrmEngSpdCmdSysTp "Platform Engine Speed Command System Type";
BA_ "SignalType" SG_ 1257 PltfrmEngSpdCmdSysTp "ENM";
BA_ "VNSigAllNodes" SG_ 1257 PltfrmEngSpdCmdSysTp 1;
BA_ "SignalLongName" SG_ 505 AllNodesVNA_1F9 "All Nodes Virtual Network Activation";
BA_ "SignalType" SG_ 505 AllNodesVNA_1F9 "ENM";
BA_ "VNSigSLHS_VNReq" SG_ 505 AllNodesVNA_1F9 1;
BA_ "VNSigAllNodes" SG_ 505 AllNodesVNA_1F9 1;
BA_ "SignalLongName" SG_ 505 PTOVehTopSpdLimVal "Power Take Off Vehicle Top Speed Limit Value";
BA_ "SignalType" SG_ 505 PTOVehTopSpdLimVal "UNM";
BA_ "VNSigAllNodes" SG_ 505 PTOVehTopSpdLimVal 1;
BA_ "SignalLongName" SG_ 505 AccPdlPwrTkOffOvrAct "Accelerator Pedal Power Take Off Override Active";
BA_ "SignalType" SG_ 505 AccPdlPwrTkOffOvrAct "BLN";
BA_ "VNSigAllNodes" SG_ 505 AccPdlPwrTkOffOvrAct 1;
BA_ "SignalLongName" SG_ 505 PTOTGRReqdGear "Power Take Off Transmission Gear Request : Requested Gear";
BA_ "PacketOrder" SG_ 505 PTOTGRReqdGear 2;
BA_ "SignalType" SG_ 505 PTOTGRReqdGear "ENM";
BA_ "VNSigAllNodes" SG_ 505 PTOTGRReqdGear 1;
BA_ "SignalLongName" SG_ 505 PTOTGRReqType "Power Take Off Transmission Gear Request : Request Type";
BA_ "PacketOrder" SG_ 505 PTOTGRReqType 1;
BA_ "SignalType" SG_ 505 PTOTGRReqType "ENM";
BA_ "VNSigAllNodes" SG_ 505 PTOTGRReqType 1;
BA_ "SignalLongName" SG_ 505 PTORmtEngStrtReq "Power Take Off Remote Engine Start Request";
BA_ "SignalType" SG_ 505 PTORmtEngStrtReq "ENM";
BA_ "VNSigAllNodes" SG_ 505 PTORmtEngStrtReq 1;
BA_ "SignalLongName" SG_ 505 TrnsPTOCltchRelRqd "Transmission Power Take Off Clutch Release Requested";
BA_ "SignalType" SG_ 505 TrnsPTOCltchRelRqd "BLN";
BA_ "VNSigAllNodes" SG_ 505 TrnsPTOCltchRelRqd 1;
BA_ "SignalLongName" SG_ 505 FstIdlMdAct "Fast Idle Mode Active";
BA_ "SignalType" SG_ 505 FstIdlMdAct "BLN";
BA_ "VNSigAllNodes" SG_ 505 FstIdlMdAct 1;
BA_ "GenSigSendType" SG_ 505 FstIdlMdAct 10;
BA_ "SignalLongName" SG_ 505 PTOMdAct "Power Take Off Mode Active";
BA_ "SignalType" SG_ 505 PTOMdAct "BLN";
BA_ "VNSigAllNodes" SG_ 505 PTOMdAct 1;
BA_ "SignalLongName" SG_ 505 PTOEngTrqLmtRchd "Power Take Off Engine Torque Limit Requested";
BA_ "SignalType" SG_ 505 PTOEngTrqLmtRchd "BLN";
BA_ "VNSigAllNodes" SG_ 505 PTOEngTrqLmtRchd 1;
BA_ "SignalLongName" SG_ 505 PTOEngTrqLmtValER "Power Take Off Engine Torque Limit Value Extended Range";
BA_ "SignalType" SG_ 505 PTOEngTrqLmtValER "UNM";
BA_ "VNSigAllNodes" SG_ 505 PTOEngTrqLmtValER 1;
BA_ "SignalLongName" SG_ 505 PltfrmEngSpdCmdMdAct "Platform Engine Speed Command : Platform Engine Speed Command Mode Active";
BA_ "PacketOrder" SG_ 505 PltfrmEngSpdCmdMdAct 1;
BA_ "SignalType" SG_ 505 PltfrmEngSpdCmdMdAct "BLN";
BA_ "VNSigAllNodes" SG_ 505 PltfrmEngSpdCmdMdAct 1;
BA_ "SignalLongName" SG_ 505 PltfrmEngSpdReq "Platform Engine Speed Command : Platform Engine Speed Request";
BA_ "PacketOrder" SG_ 505 PltfrmEngSpdReq 2;
BA_ "SignalType" SG_ 505 PltfrmEngSpdReq "UNM";
BA_ "VNSigAllNodes" SG_ 505 PltfrmEngSpdReq 1;
BA_ "SignalLongName" SG_ 505 PFESpdCmdOnSwAct "Platform Engine Speed Command On Switch Active";
BA_ "SignalType" SG_ 505 PFESpdCmdOnSwAct "BLN";
BA_ "VNSigAllNodes" SG_ 505 PFESpdCmdOnSwAct 1;
BA_ "SignalLongName" SG_ 505 PFESpdCmdDeSwAct "Platform Engine Speed Command Speed Decrease Switch Active";
BA_ "SignalType" SG_ 505 PFESpdCmdDeSwAct "BLN";
BA_ "VNSigAllNodes" SG_ 505 PFESpdCmdDeSwAct 1;
BA_ "SignalLongName" SG_ 505 PFESpdCmdInSwAct "Platform Engine Speed Command Speed Increase Switch Active";
BA_ "SignalType" SG_ 505 PFESpdCmdInSwAct "BLN";
BA_ "VNSigAllNodes" SG_ 505 PFESpdCmdInSwAct 1;
BA_ "SignalLongName" SG_ 505 PFESpdCmdSwDIntg "Platform Engine Speed Command Switch Data Integrity";
BA_ "SignalType" SG_ 505 PFESpdCmdSwDIntg "ENM";
BA_ "VNSigAllNodes" SG_ 505 PFESpdCmdSwDIntg 1;
BA_ "SignalLongName" SG_ 505 PFEngSpdCmdAlvRlgCnt "Platform Engine Speed Command Alive Rolling Count";
BA_ "SignalType" SG_ 505 PFEngSpdCmdAlvRlgCnt "UNM";
BA_ "VNSigAllNodes" SG_ 505 PFEngSpdCmdAlvRlgCnt 1;
BA_ "SignalLongName" SG_ 505 PltfrmEngSpdCmdProtVal "Platform Engine Speed Command Protection Value";
BA_ "SignalType" SG_ 505 PltfrmEngSpdCmdProtVal "UNM";
BA_ "VNSigAllNodes" SG_ 505 PltfrmEngSpdCmdProtVal 1;
BA_ "SignalLongName" SG_ 505 PTORmtEngShtdwnReqd "Power Take Off Remote Engine Shutdown Requested";
BA_ "SignalType" SG_ 505 PTORmtEngShtdwnReqd "BLN";
BA_ "VNSigAllNodes" SG_ 505 PTORmtEngShtdwnReqd 1;
BA_ "SignalLongName" SG_ 497 ElvtdIdlCstStReq "Elevated Idle Customization Setting Request";
BA_ "SignalType" SG_ 497 ElvtdIdlCstStReq "ENM";
BA_ "VNSigAllNodes" SG_ 497 ElvtdIdlCstStReq 1;
BA_ "GenSigSendType" SG_ 497 ElvtdIdlCstStReq 10;
BA_ "SignalLongName" SG_ 497 FuelFltLfRstRqd "Fuel Filter Life Reset Requested";
BA_ "SignalType" SG_ 497 FuelFltLfRstRqd "BLN";
BA_ "VNSigAllNodes" SG_ 497 FuelFltLfRstRqd 1;
BA_ "GenSigSendType" SG_ 497 FuelFltLfRstRqd 10;
BA_ "GenSigSendOnInit" SG_ 497 FuelFltLfRstRqd 1;
BA_ "GenSigStartValue" SG_ 497 ACCompSysVDA 1;
BA_ "SignalLongName" SG_ 497 ACCompSysVDA "Air Conditioning Compressor System Virtual Device Availability";
BA_ "SignalType" SG_ 497 ACCompSysVDA "ENM";
BA_ "VNSigAllNodes" SG_ 497 ACCompSysVDA 1;
BA_ "GenSigSendType" SG_ 497 ACCompSysVDA 10;
BA_ "GenSigStartValue" SG_ 497 BkupPwrModeMstrVDA 1;
BA_ "SignalLongName" SG_ 497 BkupPwrModeMstrVDA "Backup Power Mode Master Virtual Device Availability";
BA_ "SignalType" SG_ 497 BkupPwrModeMstrVDA "ENM";
BA_ "VNSigAllNodes" SG_ 497 BkupPwrModeMstrVDA 1;
BA_ "GenSigSendType" SG_ 497 BkupPwrModeMstrVDA 10;
BA_ "GenSigStartValue" SG_ 497 PrkBrkVDA 1;
BA_ "SignalLongName" SG_ 497 PrkBrkVDA "Park Brake Virtual Device Availability";
BA_ "SignalType" SG_ 497 PrkBrkVDA "ENM";
BA_ "VNSigAllNodes" SG_ 497 PrkBrkVDA 1;
BA_ "GenSigSendType" SG_ 497 PrkBrkVDA 10;
BA_ "GenSigStartValue" SG_ 497 PrkBrkVDM 1;
BA_ "SignalLongName" SG_ 497 PrkBrkVDM "Park Brake Virtual Device Mask";
BA_ "SignalType" SG_ 497 PrkBrkVDM "ENM";
BA_ "VNSigAllNodes" SG_ 497 PrkBrkVDM 1;
BA_ "GenSigSendType" SG_ 497 PrkBrkVDM 10;
BA_ "SignalLongName" SG_ 497 BkupPwrModeMstrVDM "Backup Power Mode Master Virtual Device Mask";
BA_ "SignalType" SG_ 497 BkupPwrModeMstrVDM "ENM";
BA_ "VNSigAllNodes" SG_ 497 BkupPwrModeMstrVDM 1;
BA_ "GenSigSendType" SG_ 497 BkupPwrModeMstrVDM 10;
BA_ "SignalLongName" SG_ 497 ACCompSysVDM "Air Conditioning Compressor System Virtual Device Mask";
BA_ "SignalType" SG_ 497 ACCompSysVDM "ENM";
BA_ "VNSigAllNodes" SG_ 497 ACCompSysVDM 1;
BA_ "GenSigSendType" SG_ 497 ACCompSysVDM 10;
BA_ "GenSigStartValue" SG_ 497 AirbgVDA 1;
BA_ "SignalLongName" SG_ 497 AirbgVDA "Airbag Virtual Device Availability";
BA_ "SignalType" SG_ 497 AirbgVDA "ENM";
BA_ "VNSigAllNodes" SG_ 497 AirbgVDA 1;
BA_ "GenSigSendType" SG_ 497 AirbgVDA 10;
BA_ "SignalLongName" SG_ 497 SysBkupPwrMdEn "System Backup Power Mode Enabled";
BA_ "SignalType" SG_ 497 SysBkupPwrMdEn "BLN";
BA_ "VNSigAllNodes" SG_ 497 SysBkupPwrMdEn 1;
BA_ "GenSigSendType" SG_ 497 SysBkupPwrMdEn 10;
BA_ "GenSigSendOnInit" SG_ 497 SysBkupPwrMdEn 1;
BA_ "SignalLongName" SG_ 497 SysBkUpPwrMd "System Backup Power Mode";
BA_ "SignalType" SG_ 497 SysBkUpPwrMd "ENM";
BA_ "VNSigAllNodes" SG_ 497 SysBkUpPwrMd 1;
BA_ "GenSigSendType" SG_ 497 SysBkUpPwrMd 10;
BA_ "GenSigSendOnInit" SG_ 497 SysBkUpPwrMd 1;
BA_ "SignalLongName" SG_ 497 SysPwrMd "System Power Mode";
BA_ "SignalType" SG_ 497 SysPwrMd "ENM";
BA_ "VNSigAllNodes" SG_ 497 SysPwrMd 1;
BA_ "GenSigSendType" SG_ 497 SysPwrMd 10;
BA_ "GenSigSendOnInit" SG_ 497 SysPwrMd 2;
BA_ "SignalLongName" SG_ 497 TrStLgMdAtv "Transport Storage Logistic Mode Active";
BA_ "SignalType" SG_ 497 TrStLgMdAtv "BLN";
BA_ "VNSigAllNodes" SG_ 497 TrStLgMdAtv 1;
BA_ "GenSigSendType" SG_ 497 TrStLgMdAtv 10;
BA_ "GenSigSendOnInit" SG_ 497 TrStLgMdAtv 1;
BA_ "SignalLongName" SG_ 497 DispMeasSys "Display Measurement System";
BA_ "SignalType" SG_ 497 DispMeasSys "ENM";
BA_ "VNSigAllNodes" SG_ 497 DispMeasSys 1;
BA_ "GenSigSendType" SG_ 497 DispMeasSys 10;
BA_ "GenSigSendOnInit" SG_ 497 DispMeasSys 1;
BA_ "SignalLongName" SG_ 497 ACCmpsrFldOn "Air Conditioning Compressor Failed On";
BA_ "SignalType" SG_ 497 ACCmpsrFldOn "BLN";
BA_ "VNSigAllNodes" SG_ 497 ACCmpsrFldOn 1;
BA_ "GenSigSendType" SG_ 497 ACCmpsrFldOn 10;
BA_ "SignalLongName" SG_ 497 ACCompModReq "Air Conditioning Compressor Mode Request";
BA_ "SignalType" SG_ 497 ACCompModReq "ENM";
BA_ "VNSigAllNodes" SG_ 497 ACCompModReq 1;
BA_ "GenSigSendType" SG_ 497 ACCompModReq 10;
BA_ "GenSigSendOnInit" SG_ 497 ACCompModReq 2;
BA_ "SignalLongName" SG_ 497 ACCompNormLd "Air Conditioning Compressor Normalized Load";
BA_ "SignalType" SG_ 497 ACCompNormLd "UNM";
BA_ "VNSigAllNodes" SG_ 497 ACCompNormLd 1;
BA_ "GenSigDeltaValue" SG_ 497 ACCompNormLd 1;
BA_ "GenSigSendType" SG_ 497 ACCompNormLd 12;
BA_ "GenSigSendOnInit" SG_ 497 ACCompNormLd 1;
BA_ "SignalLongName" SG_ 497 ACCompNormLdV "Air Conditioning Compressor Normalized Load Validity";
BA_ "SignalType" SG_ 497 ACCompNormLdV "ENM";
BA_ "VNSigAllNodes" SG_ 497 ACCompNormLdV 1;
BA_ "GenSigSendType" SG_ 497 ACCompNormLdV 10;
BA_ "GenSigSendOnInit" SG_ 497 ACCompNormLdV 1;
BA_ "SignalLongName" SG_ 497 PTORSMstrEngShtReq "Power Take Off Remote Start Master Engine Shutdown Requested";
BA_ "SignalType" SG_ 497 PTORSMstrEngShtReq "BLN";
BA_ "VNSigAllNodes" SG_ 497 PTORSMstrEngShtReq 1;
BA_ "GenSigSendType" SG_ 497 PTORSMstrEngShtReq 10;
BA_ "SignalLongName" SG_ 497 EngOilLfRstRq "Engine Oil Life Reset Request";
BA_ "SignalType" SG_ 497 EngOilLfRstRq "BLN";
BA_ "VNSigAllNodes" SG_ 497 EngOilLfRstRq 1;
BA_ "GenSigSendType" SG_ 497 EngOilLfRstRq 10;
BA_ "SignalLongName" SG_ 497 SIRDpl "Airbag Deployed";
BA_ "SignalType" SG_ 497 SIRDpl "BLN";
BA_ "VNSigAllNodes" SG_ 497 SIRDpl 1;
BA_ "GenSigSendType" SG_ 497 SIRDpl 10;
BA_ "GenSigSendOnInit" SG_ 497 SIRDpl 2;
BA_ "SignalLongName" SG_ 497 PTORmStMsEngStRq "Power Take Off Remote Start Master Engine Start Request";
BA_ "SignalType" SG_ 497 PTORmStMsEngStRq "ENM";
BA_ "VNSigAllNodes" SG_ 497 PTORmStMsEngStRq 1;
BA_ "GenSigSendType" SG_ 497 PTORmStMsEngStRq 10;
BA_ "SignalLongName" SG_ 497 RmVehStrRq "Remote Vehicle Start Request";
BA_ "SignalType" SG_ 497 RmVehStrRq "ENM";
BA_ "VNSigAllNodes" SG_ 497 RmVehStrRq 1;
BA_ "GenSigSendType" SG_ 497 RmVehStrRq 10;
BA_ "SignalLongName" SG_ 497 ThrtlPrgrsnReq "Throttle Progression Request";
BA_ "SignalType" SG_ 497 ThrtlPrgrsnReq "ENM";
BA_ "VNSigAllNodes" SG_ 497 ThrtlPrgrsnReq 1;
BA_ "GenSigSendType" SG_ 497 ThrtlPrgrsnReq 10;
BA_ "SignalLongName" SG_ 497 PrkBrkSwAtv "Park Brake Switch Active";
BA_ "SignalType" SG_ 497 PrkBrkSwAtv "BLN";
BA_ "VNSigAllNodes" SG_ 497 PrkBrkSwAtv 1;
BA_ "GenSigSendType" SG_ 497 PrkBrkSwAtv 10;
BA_ "GenSigSendOnInit" SG_ 497 PrkBrkSwAtv 1;
BA_ "SignalLongName" SG_ 497 PMMAccTrmSt "Power Mode Master Accessory Terminal Status";
BA_ "SignalType" SG_ 497 PMMAccTrmSt "ENM";
BA_ "VNSigAllNodes" SG_ 497 PMMAccTrmSt 1;
BA_ "GenSigSendType" SG_ 497 PMMAccTrmSt 10;
BA_ "SignalLongName" SG_ 497 PMMRunCrkTrmSt "Power Mode Master Run Crank Terminal Status";
BA_ "SignalType" SG_ 497 PMMRunCrkTrmSt "ENM";
BA_ "VNSigAllNodes" SG_ 497 PMMRunCrkTrmSt 1;
BA_ "GenSigSendType" SG_ 497 PMMRunCrkTrmSt 10;
BA_ "SignalLongName" SG_ 497 ImmblzrPreRelPswdStat "Immobilizer Pre Release Password Status";
BA_ "SignalType" SG_ 497 ImmblzrPreRelPswdStat "ENM";
BA_ "VNSigAllNodes" SG_ 497 ImmblzrPreRelPswdStat 1;
BA_ "GenSigSendType" SG_ 497 ImmblzrPreRelPswdStat 10;
BA_ "SignalLongName" SG_ 497 ImmblzrPreRelPswrd "Immobilizer Pre Release Password";
BA_ "SignalType" SG_ 497 ImmblzrPreRelPswrd "UNM";
BA_ "VNSigAllNodes" SG_ 497 ImmblzrPreRelPswrd 1;
BA_ "GenSigDeltaValue" SG_ 497 ImmblzrPreRelPswrd 1;
BA_ "GenSigSendType" SG_ 497 ImmblzrPreRelPswrd 12;
BA_ "SignalLongName" SG_ 969 ImoInf "Immobilizer Information";
BA_ "SignalType" SG_ 969 ImoInf "UNM";
BA_ "VNSigAllNodes" SG_ 969 ImoInf 1;
BA_ "SignalLongName" SG_ 1249 VehIdNmDig10_17 "Vehicle Identification Number Digits 10-17";
BA_ "SignalType" SG_ 1249 VehIdNmDig10_17 "ASC";
BA_ "VNSigAllNodes" SG_ 1249 VehIdNmDig10_17 1;
BA_ "GenSigSendOnInit" SG_ 1249 VehIdNmDig10_17 2;
BA_ "SignalLongName" SG_ 481 CrsSecSwStatPVal "Cruise Secondary Switch Status Protection Value";
BA_ "SignalType" SG_ 481 CrsSecSwStatPVal "UNM";
BA_ "VNSigAllNodes" SG_ 481 CrsSecSwStatPVal 1;
BA_ "SignalLongName" SG_ 481 CrsSecSwStatARC "Cruise Secondary Switch Status Alive Rolling Count";
BA_ "SignalType" SG_ 481 CrsSecSwStatARC "UNM";
BA_ "VNSigAllNodes" SG_ 481 CrsSecSwStatARC 1;
BA_ "SignalLongName" SG_ 481 CrsSecSwStat "Cruise Secondary Switch Status";
BA_ "SignalType" SG_ 481 CrsSecSwStat "ENM";
BA_ "VNSigAllNodes" SG_ 481 CrsSecSwStat 1;
BA_ "SignalLongName" SG_ 481 DrvSelMdSw3Sta "Driver Selected Mode Switch 3 State";
BA_ "SignalType" SG_ 481 DrvSelMdSw3Sta "ENM";
BA_ "VNSigAllNodes" SG_ 481 DrvSelMdSw3Sta 1;
BA_ "SignalLongName" SG_ 481 DrvSelMdSw2Sta "Driver Selected Mode Switch 2 State";
BA_ "SignalType" SG_ 481 DrvSelMdSw2Sta "ENM";
BA_ "VNSigAllNodes" SG_ 481 DrvSelMdSw2Sta 1;
BA_ "SignalLongName" SG_ 481 AuxHtrRq "Auxiliary Heater Request";
BA_ "SignalType" SG_ 481 AuxHtrRq "ENM";
BA_ "VNSigAllNodes" SG_ 481 AuxHtrRq 1;
BA_ "GenSigSendType" SG_ 481 AuxHtrRq 10;
BA_ "SignalLongName" SG_ 481 AuxHtrAtv "Auxiliary Heater Active";
BA_ "SignalType" SG_ 481 AuxHtrAtv "BLN";
BA_ "VNSigAllNodes" SG_ 481 AuxHtrAtv 1;
BA_ "GenSigSendType" SG_ 481 AuxHtrAtv 10;
BA_ "SignalLongName" SG_ 481 DrvSelMdSwStaARC "Driver Selected Mode Switch State Alive Rolling Count";
BA_ "SignalType" SG_ 481 DrvSelMdSwStaARC "UNM";
BA_ "VNSigAllNodes" SG_ 481 DrvSelMdSwStaARC 1;
BA_ "SignalLongName" SG_ 481 DrvSelMdSw1Sta "Driver Selected Mode Switch 1 State";
BA_ "SignalType" SG_ 481 DrvSelMdSw1Sta "ENM";
BA_ "VNSigAllNodes" SG_ 481 DrvSelMdSw1Sta 1;
BA_ "SignalLongName" SG_ 481 CrsSpdLmtrSwStatPVal "Cruise and Speed Limiter Switch Status Protection Value";
BA_ "SignalType" SG_ 481 CrsSpdLmtrSwStatPVal "UNM";
BA_ "VNSigAllNodes" SG_ 481 CrsSpdLmtrSwStatPVal 1;
BA_ "SignalLongName" SG_ 481 CrsSpdLmtrSwStatARC "Cruise and Speed Limiter Switch Status Alive Rolling Count";
BA_ "SignalType" SG_ 481 CrsSpdLmtrSwStatARC "UNM";
BA_ "VNSigAllNodes" SG_ 481 CrsSpdLmtrSwStatARC 1;
BA_ "SignalLongName" SG_ 481 FuelMdSwActV "Fuel Mode Switch Active Validity";
BA_ "SignalType" SG_ 481 FuelMdSwActV "ENM";
BA_ "VNSigAllNodes" SG_ 481 FuelMdSwActV 1;
BA_ "SignalLongName" SG_ 481 FuelMdSwAct "Fuel Mode Switch Active";
BA_ "SignalType" SG_ 481 FuelMdSwAct "ENM";
BA_ "VNSigAllNodes" SG_ 481 FuelMdSwAct 1;
BA_ "SignalLongName" SG_ 481 CrsSpdLmtrSwStat "Cruise and Speed Limiter Switch Status";
BA_ "SignalType" SG_ 481 CrsSpdLmtrSwStat "ENM";
BA_ "VNSigAllNodes" SG_ 481 CrsSpdLmtrSwStat 1;
BA_ "GenSigSendType" SG_ 481 CrsSpdLmtrSwStat 10;
BA_ "SignalLongName" SG_ 481 AdptCrsGapSwAct "Adaptive Cruise Control Gap Switch Activation";
BA_ "SignalType" SG_ 481 AdptCrsGapSwAct "ENM";
BA_ "VNSigAllNodes" SG_ 481 AdptCrsGapSwAct 1;
BA_ "GenSigSendType" SG_ 481 AdptCrsGapSwAct 10;
BA_ "SignalLongName" SG_ 481 CrsCntrlSwStCanSwAct "Cruise Control Switch Status : Cancel Switch Active";
BA_ "PacketOrder" SG_ 481 CrsCntrlSwStCanSwAct 1;
BA_ "SignalType" SG_ 481 CrsCntrlSwStCanSwAct "BLN";
BA_ "VNSigAllNodes" SG_ 481 CrsCntrlSwStCanSwAct 1;
BA_ "GenSigSendType" SG_ 481 CrsCntrlSwStCanSwAct 10;
BA_ "GenSigSendOnInit" SG_ 481 CrsCntrlSwStCanSwAct 2;
BA_ "SignalLongName" SG_ 481 CrsCntrlSwStSwDataIntgty "Cruise Control Switch Status : Switch Data Integrity";
BA_ "PacketOrder" SG_ 481 CrsCntrlSwStSwDataIntgty 7;
BA_ "SignalType" SG_ 481 CrsCntrlSwStSwDataIntgty "ENM";
BA_ "VNSigAllNodes" SG_ 481 CrsCntrlSwStSwDataIntgty 1;
BA_ "GenSigSendType" SG_ 481 CrsCntrlSwStSwDataIntgty 10;
BA_ "GenSigSendOnInit" SG_ 481 CrsCntrlSwStSwDataIntgty 2;
BA_ "SignalLongName" SG_ 481 CrsCntrlSwStSpdInSwAct "Cruise Control Switch Status : Speed Increase Switch Active";
BA_ "PacketOrder" SG_ 481 CrsCntrlSwStSpdInSwAct 5;
BA_ "SignalType" SG_ 481 CrsCntrlSwStSpdInSwAct "BLN";
BA_ "VNSigAllNodes" SG_ 481 CrsCntrlSwStSpdInSwAct 1;
BA_ "GenSigSendType" SG_ 481 CrsCntrlSwStSpdInSwAct 10;
BA_ "GenSigSendOnInit" SG_ 481 CrsCntrlSwStSpdInSwAct 2;
BA_ "SignalLongName" SG_ 481 CrsCntrlSwStSpDcSwAct "Cruise Control Switch Status : Speed Decrease Switch Active";
BA_ "PacketOrder" SG_ 481 CrsCntrlSwStSpDcSwAct 6;
BA_ "SignalType" SG_ 481 CrsCntrlSwStSpDcSwAct "BLN";
BA_ "VNSigAllNodes" SG_ 481 CrsCntrlSwStSpDcSwAct 1;
BA_ "GenSigSendType" SG_ 481 CrsCntrlSwStSpDcSwAct 10;
BA_ "GenSigSendOnInit" SG_ 481 CrsCntrlSwStSpDcSwAct 2;
BA_ "SignalLongName" SG_ 481 CrsCntrlSwStSetSwAct "Cruise Control Switch Status : Set Switch Active";
BA_ "PacketOrder" SG_ 481 CrsCntrlSwStSetSwAct 4;
BA_ "SignalType" SG_ 481 CrsCntrlSwStSetSwAct "BLN";
BA_ "VNSigAllNodes" SG_ 481 CrsCntrlSwStSetSwAct 1;
BA_ "GenSigSendType" SG_ 481 CrsCntrlSwStSetSwAct 10;
BA_ "GenSigSendOnInit" SG_ 481 CrsCntrlSwStSetSwAct 2;
BA_ "SignalLongName" SG_ 481 CrsCntrlSwStResSwAct "Cruise Control Switch Status : Resume Switch Active";
BA_ "PacketOrder" SG_ 481 CrsCntrlSwStResSwAct 3;
BA_ "SignalType" SG_ 481 CrsCntrlSwStResSwAct "BLN";
BA_ "VNSigAllNodes" SG_ 481 CrsCntrlSwStResSwAct 1;
BA_ "GenSigSendType" SG_ 481 CrsCntrlSwStResSwAct 10;
BA_ "GenSigSendOnInit" SG_ 481 CrsCntrlSwStResSwAct 2;
BA_ "SignalLongName" SG_ 481 CrsCntrlSwStOnSwAct "Cruise Control Switch Status : On Switch Active";
BA_ "PacketOrder" SG_ 481 CrsCntrlSwStOnSwAct 2;
BA_ "SignalType" SG_ 481 CrsCntrlSwStOnSwAct "BLN";
BA_ "VNSigAllNodes" SG_ 481 CrsCntrlSwStOnSwAct 1;
BA_ "GenSigSendType" SG_ 481 CrsCntrlSwStOnSwAct 10;
BA_ "GenSigSendOnInit" SG_ 481 CrsCntrlSwStOnSwAct 2;
BA_ "SignalLongName" SG_ 481 CrsCntrlSwStatProtValue "Cruise Control Switch Status Protection Value";
BA_ "SignalType" SG_ 481 CrsCntrlSwStatProtValue "UNM";
BA_ "VNSigAllNodes" SG_ 481 CrsCntrlSwStatProtValue 1;
BA_ "SignalLongName" SG_ 481 CrsCntrlSwStAlvRollCnt "Cruise Control Switch Status Alive Rolling Count";
BA_ "SignalType" SG_ 481 CrsCntrlSwStAlvRollCnt "UNM";
BA_ "VNSigAllNodes" SG_ 481 CrsCntrlSwStAlvRollCnt 1;
BA_ "SignalLongName" SG_ 481 CrsCntCncRq "Cruise Control Cancel Request";
BA_ "SignalType" SG_ 481 CrsCntCncRq "ENM";
BA_ "VNSigAllNodes" SG_ 481 CrsCntCncRq 1;
BA_ "SignalLongName" SG_ 241 NotEventStat "Notification Event Status";
BA_ "SignalType" SG_ 241 NotEventStat "ENM";
BA_ "VNSigAllNodes" SG_ 241 NotEventStat 1;
BA_ "GenSigSendType" SG_ 241 NotEventStat 10;
BA_ "SignalLongName" SG_ 241 BrkPdlChkData "Brake Pedal Check Data";
BA_ "SignalType" SG_ 241 BrkPdlChkData "UNM";
BA_ "VNSigAllNodes" SG_ 241 BrkPdlChkData 1;
BA_ "SignalLongName" SG_ 241 BrkAppSnsrHmPosLrnd "Brake Apply Sensor Home Position Learned";
BA_ "SignalType" SG_ 241 BrkAppSnsrHmPosLrnd "BLN";
BA_ "VNSigAllNodes" SG_ 241 BrkAppSnsrHmPosLrnd 1;
BA_ "SignalLongName" SG_ 241 BrkPedTrvlAchvd "Brake Pedal Initial Travel Achieved Status : Brake Pedal Initial Travel Achieved";
BA_ "PacketOrder" SG_ 241 BrkPedTrvlAchvd 1;
BA_ "SignalType" SG_ 241 BrkPedTrvlAchvd "BLN";
BA_ "VNSigAllNodes" SG_ 241 BrkPedTrvlAchvd 1;
BA_ "GenSigSendType" SG_ 241 BrkPedTrvlAchvd 10;
BA_ "SignalLongName" SG_ 241 BrkPedTrvlAchvdV "Brake Pedal Initial Travel Achieved Status : Brake Pedal Initial Travel Achieved Validity";
BA_ "PacketOrder" SG_ 241 BrkPedTrvlAchvdV 2;
BA_ "SignalType" SG_ 241 BrkPedTrvlAchvdV "ENM";
BA_ "VNSigAllNodes" SG_ 241 BrkPedTrvlAchvdV 1;
BA_ "GenSigSendType" SG_ 241 BrkPedTrvlAchvdV 10;
BA_ "SignalLongName" SG_ 241 BrkPdlPosGrad "Brake Pedal Position Gradient";
BA_ "SignalType" SG_ 241 BrkPdlPosGrad "SNM";
BA_ "VNSigAllNodes" SG_ 241 BrkPdlPosGrad 1;
BA_ "SignalLongName" SG_ 241 BrkPdlPos "Brake Pedal Position";
BA_ "SignalType" SG_ 241 BrkPdlPos "UNM";
BA_ "VNSigAllNodes" SG_ 241 BrkPdlPos 1;
BA_ "GenSigDeltaValue" SG_ 241 BrkPdlPos 1;
BA_ "GenSigSendType" SG_ 241 BrkPdlPos 12;
BA_ "GenSigSendOnInit" SG_ 241 BrkPdlPos 1;
BA_ "SignalLongName" SG_ 241 BrkPedPosAlvRolngCnt "Brake Pedal Position Alive Rolling Count";
BA_ "SignalType" SG_ 241 BrkPedPosAlvRolngCnt "UNM";
BA_ "VNSigAllNodes" SG_ 241 BrkPedPosAlvRolngCnt 1;
BA_ "SignalLongName" SG_ 241 BrkPdlModTrvlV "Brake Pedal Moderate Travel Achieved Validity";
BA_ "SignalType" SG_ 241 BrkPdlModTrvlV "ENM";
BA_ "VNSigAllNodes" SG_ 241 BrkPdlModTrvlV 1;
BA_ "GenSigSendType" SG_ 241 BrkPdlModTrvlV 10;
BA_ "SignalLongName" SG_ 241 BrkPdlModTrvl "Brake Pedal Moderate Travel Achieved";
BA_ "SignalType" SG_ 241 BrkPdlModTrvl "BLN";
BA_ "VNSigAllNodes" SG_ 241 BrkPdlModTrvl 1;
BA_ "GenSigSendType" SG_ 241 BrkPdlModTrvl 10;
BA_ "SignalLongName" SG_ 241 BrkPdlInTrvPrt "Brake Pedal Initial Travel Achieved Protection";
BA_ "SignalType" SG_ 241 BrkPdlInTrvPrt "UNM";
BA_ "VNSigAllNodes" SG_ 241 BrkPdlInTrvPrt 1;
BA_REL_ "GenSigTimeoutTime" BU_SG_REL_ ECM_HS SG_ 313 DrDoorOpenSwAct 250;
BA_REL_ "GenSigTimeoutMsg" BU_SG_REL_ ECM_HS SG_ 313 DrDoorOpenSwAct 313;
BA_REL_ "GenSigVDAFailComment" BU_SG_REL_ ECM_HS SG_ 313 DrDoorOpenSwAct "DrvrDrOpenSwVDA";
BA_REL_ "GenSigVDAFailResp" BU_SG_REL_ ECM_HS SG_ 313 DrDoorOpenSwAct 1;
BA_REL_ "GenSigSuprvResp" BU_SG_REL_ ECM_HS SG_ 313 DrDoorOpenSwAct 1;
BA_REL_ "GenSigTimeoutTime" BU_SG_REL_ EBCM_HS SG_ 313 LnchCtrlWhlSlpReq 250;
BA_REL_ "GenSigTimeoutMsg" BU_SG_REL_ EBCM_HS SG_ 313 LnchCtrlWhlSlpReq 313;
BA_REL_ "GenSigSuprvResp" BU_SG_REL_ EBCM_HS SG_ 313 LnchCtrlWhlSlpReq 1;
BA_REL_ "GenSigTimeoutTime" BU_SG_REL_ EBCM_HS SG_ 313 LnchCtrlMdReq 250;
BA_REL_ "GenSigTimeoutMsg" BU_SG_REL_ EBCM_HS SG_ 313 LnchCtrlMdReq 313;
BA_REL_ "GenSigSuprvResp" BU_SG_REL_ EBCM_HS SG_ 313 LnchCtrlMdReq 1;
BA_REL_ "GenSigTimeoutTime" BU_SG_REL_ EBCM_HS SG_ 313 LnchCtrlEngRPMReq 250;
BA_REL_ "GenSigTimeoutMsg" BU_SG_REL_ EBCM_HS SG_ 313 LnchCtrlEngRPMReq 313;
BA_REL_ "GenSigSuprvResp" BU_SG_REL_ EBCM_HS SG_ 313 LnchCtrlEngRPMReq 1;
BA_REL_ "GenSigTimeoutTime" BU_SG_REL_ EBCM_HS SG_ 313 ExtHlStrAssCsStRq 250;
BA_REL_ "GenSigTimeoutMsg" BU_SG_REL_ EBCM_HS SG_ 313 ExtHlStrAssCsStRq 313;
BA_REL_ "GenSigSuprvResp" BU_SG_REL_ EBCM_HS SG_ 313 ExtHlStrAssCsStRq 1;
BA_REL_ "GenSigTimeoutTime" BU_SG_REL_ EBCM_HS SG_ 313 DrvStyPerfMdCsStReq 250;
BA_REL_ "GenSigTimeoutMsg" BU_SG_REL_ EBCM_HS SG_ 313 DrvStyPerfMdCsStReq 313;
BA_REL_ "GenSigSuprvResp" BU_SG_REL_ EBCM_HS SG_ 313 DrvStyPerfMdCsStReq 1;
BA_REL_ "GenSigTimeoutTime" BU_SG_REL_ EBCM_HS SG_ 313 PsngStPerfMdCsStReq 250;
BA_REL_ "GenSigTimeoutMsg" BU_SG_REL_ EBCM_HS SG_ 313 PsngStPerfMdCsStReq 313;
BA_REL_ "GenSigSuprvResp" BU_SG_REL_ EBCM_HS SG_ 313 PsngStPerfMdCsStReq 1;
BA_REL_ "GenSigTimeoutTime" BU_SG_REL_ EBCM_HS SG_ 313 DrvrStPerfMdCsStReq 250;
BA_REL_ "GenSigTimeoutMsg" BU_SG_REL_ EBCM_HS SG_ 313 DrvrStPerfMdCsStReq 313;
BA_REL_ "GenSigSuprvResp" BU_SG_REL_ EBCM_HS SG_ 313 DrvrStPerfMdCsStReq 1;
BA_REL_ "GenSigTimeoutTime" BU_SG_REL_ EBCM_HS SG_ 313 ACCPerfMdCsStReq 250;
BA_REL_ "GenSigTimeoutMsg" BU_SG_REL_ EBCM_HS SG_ 313 ACCPerfMdCsStReq 313;
BA_REL_ "GenSigSuprvResp" BU_SG_REL_ EBCM_HS SG_ 313 ACCPerfMdCsStReq 1;
BA_REL_ "GenSigTimeoutTime" BU_SG_REL_ EBCM_HS SG_ 313 SndPerfMdCsStRq 250;
BA_REL_ "GenSigTimeoutMsg" BU_SG_REL_ EBCM_HS SG_ 313 SndPerfMdCsStRq 313;
BA_REL_ "GenSigSuprvResp" BU_SG_REL_ EBCM_HS SG_ 313 SndPerfMdCsStRq 1;
BA_REL_ "GenSigTimeoutTime" BU_SG_REL_ EBCM_HS SG_ 313 FCABrkPrflReq 250;
BA_REL_ "GenSigTimeoutMsg" BU_SG_REL_ EBCM_HS SG_ 313 FCABrkPrflReq 313;
BA_REL_ "GenSigSuprvResp" BU_SG_REL_ EBCM_HS SG_ 313 FCABrkPrflReq 1;
BA_REL_ "GenSigTimeoutTime" BU_SG_REL_ EBCM_HS SG_ 313 DispPerfMdCsStRq 250;
BA_REL_ "GenSigTimeoutMsg" BU_SG_REL_ EBCM_HS SG_ 313 DispPerfMdCsStRq 313;
BA_REL_ "GenSigSuprvResp" BU_SG_REL_ EBCM_HS SG_ 313 DispPerfMdCsStRq 1;
BA_REL_ "GenSigTimeoutTime" BU_SG_REL_ EBCM_HS SG_ 313 CrshAlrtStPrsnt 250;
BA_REL_ "GenSigTimeoutMsg" BU_SG_REL_ EBCM_HS SG_ 313 CrshAlrtStPrsnt 313;
BA_REL_ "GenSigSuprvResp" BU_SG_REL_ EBCM_HS SG_ 313 CrshAlrtStPrsnt 1;
BA_REL_ "GenSigTimeoutTime" BU_SG_REL_ CGM_HS SG_ 311 PsngSysDilPrcs 250;
BA_REL_ "GenSigTimeoutMsg" BU_SG_REL_ CGM_HS SG_ 311 PsngSysDilPrcs 311;
BA_REL_ "GenSigSuprvResp" BU_SG_REL_ CGM_HS SG_ 311 PsngSysDilPrcs 1;
BA_REL_ "GenSigTimeoutTime" BU_SG_REL_ CGM_HS SG_ 311 Hrs 250;
BA_REL_ "GenSigTimeoutMsg" BU_SG_REL_ CGM_HS SG_ 311 Hrs 311;
BA_REL_ "GenSigSuprvResp" BU_SG_REL_ CGM_HS SG_ 311 Hrs 1;
BA_REL_ "GenSigTimeoutTime" BU_SG_REL_ CGM_HS SG_ 311 PsngSysHding 250;
BA_REL_ "GenSigTimeoutMsg" BU_SG_REL_ CGM_HS SG_ 311 PsngSysHding 311;
BA_REL_ "GenSigSuprvResp" BU_SG_REL_ CGM_HS SG_ 311 PsngSysHding 1;
BA_REL_ "GenSigTimeoutTime" BU_SG_REL_ CGM_HS SG_ 311 PsngSysElvtn 250;
BA_REL_ "GenSigTimeoutMsg" BU_SG_REL_ CGM_HS SG_ 311 PsngSysElvtn 311;
BA_REL_ "GenSigSuprvResp" BU_SG_REL_ CGM_HS SG_ 311 PsngSysElvtn 1;
BA_REL_ "GenSigTimeoutTime" BU_SG_REL_ CGM_HS SG_ 311 Mins 250;
BA_REL_ "GenSigTimeoutMsg" BU_SG_REL_ CGM_HS SG_ 311 Mins 311;
BA_REL_ "GenSigSuprvResp" BU_SG_REL_ CGM_HS SG_ 311 Mins 1;
BA_REL_ "GenSigTimeoutTime" BU_SG_REL_ CGM_HS SG_ 311 VehSpeSta 250;
BA_REL_ "GenSigTimeoutMsg" BU_SG_REL_ CGM_HS SG_ 311 VehSpeSta 311;
BA_REL_ "GenSigSuprvResp" BU_SG_REL_ CGM_HS SG_ 311 VehSpeSta 1;
BA_REL_ "GenSigTimeoutTime" BU_SG_REL_ EBCM_HS SG_ 810 PsngSysLong 1000;
BA_REL_ "GenSigTimeoutMsg" BU_SG_REL_ EBCM_HS SG_ 810 PsngSysLong 810;
BA_REL_ "GenSigSuprvResp" BU_SG_REL_ EBCM_HS SG_ 810 PsngSysLong 1;
BA_REL_ "GenSigTimeoutTime" BU_SG_REL_ EBCM_HS SG_ 810 PsngSysLat 1000;
BA_REL_ "GenSigTimeoutMsg" BU_SG_REL_ EBCM_HS SG_ 810 PsngSysLat 810;
BA_REL_ "GenSigSuprvResp" BU_SG_REL_ EBCM_HS SG_ 810 PsngSysLat 1;
BA_REL_ "GenSigTimeoutTime" BU_SG_REL_ BSM_HS SG_ 1105 JmpStrtReq 500;
BA_REL_ "GenSigTimeoutMsg" BU_SG_REL_ BSM_HS SG_ 1105 JmpStrtReq 1105;
BA_REL_ "GenSigSuprvResp" BU_SG_REL_ BSM_HS SG_ 1105 JmpStrtReq 1;
BA_REL_ "GenSigTimeoutTime" BU_SG_REL_ EBCM_HS SG_ 1105 ClmCntFrBlwFnSp 1000;
BA_REL_ "GenSigTimeoutMsg" BU_SG_REL_ EBCM_HS SG_ 1105 ClmCntFrBlwFnSp 1105;
BA_REL_ "GenSigSuprvResp" BU_SG_REL_ EBCM_HS SG_ 1105 ClmCntFrBlwFnSp 1;
BA_REL_ "GenSigTimeoutTime" BU_SG_REL_ ECM_HS SG_ 322 IntDimLvl 250;
BA_REL_ "GenSigTimeoutMsg" BU_SG_REL_ ECM_HS SG_ 322 IntDimLvl 322;
BA_REL_ "GenSigSuprvResp" BU_SG_REL_ ECM_HS SG_ 322 IntDimLvl 1;
BA_REL_ "GenSigTimeoutTime" BU_SG_REL_ EBCM_HS SG_ 322 IntDimLvl 250;
BA_REL_ "GenSigTimeoutMsg" BU_SG_REL_ EBCM_HS SG_ 322 IntDimLvl 322;
BA_REL_ "GenSigRxStartValue" BU_SG_REL_ EBCM_HS SG_ 322 IntDimLvl "0";
BA_REL_ "GenSigSuprvResp" BU_SG_REL_ EBCM_HS SG_ 322 IntDimLvl 1;
BA_REL_ "GenSigTimeoutTime" BU_SG_REL_ CGM_HS SG_ 309 StBltTgtCSRq 250;
BA_REL_ "GenSigTimeoutMsg" BU_SG_REL_ CGM_HS SG_ 309 StBltTgtCSRq 309;
BA_REL_ "GenSigSuprvResp" BU_SG_REL_ CGM_HS SG_ 309 StBltTgtCSRq 1;
BA_REL_ "GenSigTimeoutTime" BU_SG_REL_ EBCM_HS SG_ 309 StBltTgtCSRq 500;
BA_REL_ "GenSigTimeoutMsg" BU_SG_REL_ EBCM_HS SG_ 309 StBltTgtCSRq 309;
BA_REL_ "GenSigSuprvResp" BU_SG_REL_ EBCM_HS SG_ 309 StBltTgtCSRq 1;
BA_REL_ "GenSigTimeoutTime" BU_SG_REL_ CGM_HS SG_ 309 ColPrSysCustReq 250;
BA_REL_ "GenSigTimeoutMsg" BU_SG_REL_ CGM_HS SG_ 309 ColPrSysCustReq 309;
BA_REL_ "GenSigSuprvResp" BU_SG_REL_ CGM_HS SG_ 309 ColPrSysCustReq 1;
BA_REL_ "GenSigTimeoutTime" BU_SG_REL_ CGM_HS SG_ 309 Sec 250;
BA_REL_ "GenSigTimeoutMsg" BU_SG_REL_ CGM_HS SG_ 309 Sec 309;
BA_REL_ "GenSigSuprvResp" BU_SG_REL_ CGM_HS SG_ 309 Sec 1;
BA_REL_ "GenSigTimeoutTime" BU_SG_REL_ CGM_HS SG_ 309 CldrYr_154 250;
BA_REL_ "GenSigTimeoutMsg" BU_SG_REL_ CGM_HS SG_ 309 CldrYr_154 309;
BA_REL_ "GenSigSuprvResp" BU_SG_REL_ CGM_HS SG_ 309 CldrYr_154 1;
BA_REL_ "GenSigTimeoutTime" BU_SG_REL_ CGM_HS SG_ 309 CldrYr 250;
BA_REL_ "GenSigTimeoutMsg" BU_SG_REL_ CGM_HS SG_ 309 CldrYr 309;
BA_REL_ "GenSigSuprvResp" BU_SG_REL_ CGM_HS SG_ 309 CldrYr 1;
BA_REL_ "GenSigTimeoutTime" BU_SG_REL_ EBCM_HS SG_ 309 CldrYr 500;
BA_REL_ "GenSigTimeoutMsg" BU_SG_REL_ EBCM_HS SG_ 309 CldrYr 309;
BA_REL_ "GenSigSuprvResp" BU_SG_REL_ EBCM_HS SG_ 309 CldrYr 1;
BA_REL_ "GenSigTimeoutTime" BU_SG_REL_ CGM_HS SG_ 309 CldrMth_154 250;
BA_REL_ "GenSigTimeoutMsg" BU_SG_REL_ CGM_HS SG_ 309 CldrMth_154 309;
BA_REL_ "GenSigSuprvResp" BU_SG_REL_ CGM_HS SG_ 309 CldrMth_154 1;
BA_REL_ "GenSigTimeoutTime" BU_SG_REL_ CGM_HS SG_ 309 CldrMth 250;
BA_REL_ "GenSigTimeoutMsg" BU_SG_REL_ CGM_HS SG_ 309 CldrMth 309;
BA_REL_ "GenSigSuprvResp" BU_SG_REL_ CGM_HS SG_ 309 CldrMth 1;
BA_REL_ "GenSigTimeoutTime" BU_SG_REL_ EBCM_HS SG_ 309 CldrMth 500;
BA_REL_ "GenSigTimeoutMsg" BU_SG_REL_ EBCM_HS SG_ 309 CldrMth 309;
BA_REL_ "GenSigSuprvResp" BU_SG_REL_ EBCM_HS SG_ 309 CldrMth 1;
BA_REL_ "GenSigTimeoutTime" BU_SG_REL_ CGM_HS SG_ 309 CldrDay_154 250;
BA_REL_ "GenSigTimeoutMsg" BU_SG_REL_ CGM_HS SG_ 309 CldrDay_154 309;
BA_REL_ "GenSigSuprvResp" BU_SG_REL_ CGM_HS SG_ 309 CldrDay_154 1;
BA_REL_ "GenSigTimeoutTime" BU_SG_REL_ CGM_HS SG_ 309 CldrDay 250;
BA_REL_ "GenSigTimeoutMsg" BU_SG_REL_ CGM_HS SG_ 309 CldrDay 309;
BA_REL_ "GenSigSuprvResp" BU_SG_REL_ CGM_HS SG_ 309 CldrDay 1;
BA_REL_ "GenSigTimeoutTime" BU_SG_REL_ EBCM_HS SG_ 309 CldrDay 500;
BA_REL_ "GenSigTimeoutMsg" BU_SG_REL_ EBCM_HS SG_ 309 CldrDay 309;
BA_REL_ "GenSigSuprvResp" BU_SG_REL_ EBCM_HS SG_ 309 CldrDay 1;
BA_REL_ "GenSigTimeoutTime" BU_SG_REL_ CGM_HS SG_ 309 CtLghtDet 250;
BA_REL_ "GenSigTimeoutMsg" BU_SG_REL_ CGM_HS SG_ 309 CtLghtDet 309;
BA_REL_ "GenSigSuprvResp" BU_SG_REL_ CGM_HS SG_ 309 CtLghtDet 1;
BA_REL_ "GenSigTimeoutTime" BU_SG_REL_ CGM_HS SG_ 309 TCSysDisSwAtv 250;
BA_REL_ "GenSigTimeoutMsg" BU_SG_REL_ CGM_HS SG_ 309 TCSysDisSwAtv 309;
BA_REL_ "GenSigSuprvResp" BU_SG_REL_ CGM_HS SG_ 309 TCSysDisSwAtv 1;
BA_REL_ "GenSigTimeoutTime" BU_SG_REL_ EBCM_HS SG_ 309 TCSysDisSwAtv 500;
BA_REL_ "GenSigTimeoutMsg" BU_SG_REL_ EBCM_HS SG_ 309 TCSysDisSwAtv 309;
BA_REL_ "GenSigSuprvResp" BU_SG_REL_ EBCM_HS SG_ 309 TCSysDisSwAtv 1;
BA_REL_ "GenSigTimeoutTime" BU_SG_REL_ CGM_HS SG_ 309 VehMovState 250;
BA_REL_ "GenSigTimeoutMsg" BU_SG_REL_ CGM_HS SG_ 309 VehMovState 309;
BA_REL_ "GenSigSuprvResp" BU_SG_REL_ CGM_HS SG_ 309 VehMovState 1;
BA_REL_ "GenSigTimeoutTime" BU_SG_REL_ EBCM_HS SG_ 309 VehMovState 500;
BA_REL_ "GenSigTimeoutMsg" BU_SG_REL_ EBCM_HS SG_ 309 VehMovState 309;
BA_REL_ "GenSigSuprvResp" BU_SG_REL_ EBCM_HS SG_ 309 VehMovState 1;
BA_REL_ "GenSigTimeoutTime" BU_SG_REL_ CGM_HS SG_ 309 WSWshSwAtv 250;
BA_REL_ "GenSigTimeoutMsg" BU_SG_REL_ CGM_HS SG_ 309 WSWshSwAtv 309;
BA_REL_ "GenSigSuprvResp" BU_SG_REL_ CGM_HS SG_ 309 WSWshSwAtv 1;
BA_REL_ "GenSigTimeoutTime" BU_SG_REL_ CGM_HS SG_ 309 HillDesCtrlMdSwAct 250;
BA_REL_ "GenSigTimeoutMsg" BU_SG_REL_ CGM_HS SG_ 309 HillDesCtrlMdSwAct 309;
BA_REL_ "GenSigSuprvResp" BU_SG_REL_ CGM_HS SG_ 309 HillDesCtrlMdSwAct 1;
BA_REL_ "GenSigTimeoutTime" BU_SG_REL_ EBCM_HS SG_ 309 HillDesCtrlMdSwAct 500;
BA_REL_ "GenSigTimeoutMsg" BU_SG_REL_ EBCM_HS SG_ 309 HillDesCtrlMdSwAct 309;
BA_REL_ "GenSigSuprvResp" BU_SG_REL_ EBCM_HS SG_ 309 HillDesCtrlMdSwAct 1;
BA_REL_ "GenSigTimeoutTime" BU_SG_REL_ CGM_HS SG_ 309 RrClosAjarSwAct 250;
BA_REL_ "GenSigTimeoutMsg" BU_SG_REL_ CGM_HS SG_ 309 RrClosAjarSwAct 309;
BA_REL_ "GenSigSuprvResp" BU_SG_REL_ CGM_HS SG_ 309 RrClosAjarSwAct 1;
BA_REL_ "GenSigTimeoutTime" BU_SG_REL_ CGM_HS SG_ 309 WSWprAct 250;
BA_REL_ "GenSigTimeoutMsg" BU_SG_REL_ CGM_HS SG_ 309 WSWprAct 309;
BA_REL_ "GenSigSuprvResp" BU_SG_REL_ CGM_HS SG_ 309 WSWprAct 1;
BA_REL_ "GenSigTimeoutTime" BU_SG_REL_ ECM_HS SG_ 309 WSWprAct 250;
BA_REL_ "GenSigTimeoutMsg" BU_SG_REL_ ECM_HS SG_ 309 WSWprAct 309;
BA_REL_ "GenSigSuprvResp" BU_SG_REL_ ECM_HS SG_ 309 WSWprAct 1;
BA_REL_ "GenSigTimeoutTime" BU_SG_REL_ EBCM_HS SG_ 309 WSWprAct 500;
BA_REL_ "GenSigTimeoutMsg" BU_SG_REL_ EBCM_HS SG_ 309 WSWprAct 309;
BA_REL_ "GenSigSuprvResp" BU_SG_REL_ EBCM_HS SG_ 309 WSWprAct 1;
BA_REL_ "GenSigTimeoutTime" BU_SG_REL_ ECM_HS SG_ 352 ShfFrmPrkAlwd 250;
BA_REL_ "GenSigTimeoutMsg" BU_SG_REL_ ECM_HS SG_ 352 ShfFrmPrkAlwd 352;
BA_REL_ "GenSigSuprvResp" BU_SG_REL_ ECM_HS SG_ 352 ShfFrmPrkAlwd 1;
BA_REL_ "GenSigTimeoutTime" BU_SG_REL_ EBCM_HS SG_ 352 AVHSwtchStats 500;
BA_REL_ "GenSigTimeoutMsg" BU_SG_REL_ EBCM_HS SG_ 352 AVHSwtchStats 352;
BA_REL_ "GenSigSuprvResp" BU_SG_REL_ EBCM_HS SG_ 352 AVHSwtchStats 1;
BA_REL_ "GenSigTimeoutTime" BU_SG_REL_ CGM_HS SG_ 352 TeenDrvAct 250;
BA_REL_ "GenSigTimeoutMsg" BU_SG_REL_ CGM_HS SG_ 352 TeenDrvAct 352;
BA_REL_ "GenSigSuprvResp" BU_SG_REL_ CGM_HS SG_ 352 TeenDrvAct 1;
BA_REL_ "GenSigTimeoutTime" BU_SG_REL_ EBCM_HS SG_ 352 TeenDrvAct 500;
BA_REL_ "GenSigTimeoutMsg" BU_SG_REL_ EBCM_HS SG_ 352 TeenDrvAct 352;
BA_REL_ "GenSigSuprvResp" BU_SG_REL_ EBCM_HS SG_ 352 TeenDrvAct 1;
BA_REL_ "GenSigTimeoutTime" BU_SG_REL_ EBCM_HS SG_ 352 LrnEnvIdSt 500;
BA_REL_ "GenSigTimeoutMsg" BU_SG_REL_ EBCM_HS SG_ 352 LrnEnvIdSt 352;
BA_REL_ "GenSigSuprvResp" BU_SG_REL_ EBCM_HS SG_ 352 LrnEnvIdSt 1;
BA_REL_ "GenSigTimeoutTime" BU_SG_REL_ EBCM_HS SG_ 352 LrnEnvId 500;
BA_REL_ "GenSigTimeoutMsg" BU_SG_REL_ EBCM_HS SG_ 352 LrnEnvId 352;
BA_REL_ "GenSigSuprvResp" BU_SG_REL_ EBCM_HS SG_ 352 LrnEnvId 1;
BA_REL_ "GenSigTimeoutTime" BU_SG_REL_ EBCM_HS SG_ 352 ImoId 500;
BA_REL_ "GenSigTimeoutMsg" BU_SG_REL_ EBCM_HS SG_ 352 ImoId 352;
BA_REL_ "GenSigSuprvResp" BU_SG_REL_ EBCM_HS SG_ 352 ImoId 1;
BA_REL_ "GenSigTimeoutTime" BU_SG_REL_ EBCM_HS SG_ 352 ImoIdSt 500;
BA_REL_ "GenSigTimeoutMsg" BU_SG_REL_ EBCM_HS SG_ 352 ImoIdSt 352;
BA_REL_ "GenSigSuprvResp" BU_SG_REL_ EBCM_HS SG_ 352 ImoIdSt 1;
BA_REL_ "GenSigTimeoutTime" BU_SG_REL_ CGM_HS SG_ 320 Ky_IdDevPrgmAuthReq 2500;
BA_REL_ "GenSigTimeoutMsg" BU_SG_REL_ CGM_HS SG_ 320 Ky_IdDevPrgmAuthReq 320;
BA_REL_ "GenSigSuprvResp" BU_SG_REL_ CGM_HS SG_ 320 Ky_IdDevPrgmAuthReq 1;
BA_REL_ "GenSigTimeoutTime" BU_SG_REL_ EPS_HS SG_ 320 Ky_IdDevPrgmAuthReq 2500;
BA_REL_ "GenSigTimeoutMsg" BU_SG_REL_ EPS_HS SG_ 320 Ky_IdDevPrgmAuthReq 320;
BA_REL_ "GenSigSuprvResp" BU_SG_REL_ EPS_HS SG_ 320 Ky_IdDevPrgmAuthReq 1;
BA_REL_ "GenSigTimeoutTime" BU_SG_REL_ CGM_HS SG_ 320 ClmnLckStat 2500;
BA_REL_ "GenSigTimeoutMsg" BU_SG_REL_ CGM_HS SG_ 320 ClmnLckStat 320;
BA_REL_ "GenSigSuprvResp" BU_SG_REL_ CGM_HS SG_ 320 ClmnLckStat 1;
BA_REL_ "GenSigTimeoutTime" BU_SG_REL_ EPS_HS SG_ 320 ClmnLckStat 2500;
BA_REL_ "GenSigTimeoutMsg" BU_SG_REL_ EPS_HS SG_ 320 ClmnLckStat 320;
BA_REL_ "GenSigSuprvResp" BU_SG_REL_ EPS_HS SG_ 320 ClmnLckStat 1;
BA_REL_ "GenSigTimeoutTime" BU_SG_REL_ CGM_HS SG_ 320 AutoBmSlctAllwd 2500;
BA_REL_ "GenSigTimeoutMsg" BU_SG_REL_ CGM_HS SG_ 320 AutoBmSlctAllwd 320;
BA_REL_ "GenSigSuprvResp" BU_SG_REL_ CGM_HS SG_ 320 AutoBmSlctAllwd 1;
BA_REL_ "GenSigTimeoutTime" BU_SG_REL_ CGM_HS SG_ 320 BrkLtsAtv 2500;
BA_REL_ "GenSigTimeoutMsg" BU_SG_REL_ CGM_HS SG_ 320 BrkLtsAtv 320;
BA_REL_ "GenSigSuprvResp" BU_SG_REL_ CGM_HS SG_ 320 BrkLtsAtv 1;
BA_REL_ "GenSigTimeoutTime" BU_SG_REL_ CGM_HS SG_ 320 TrnSwAct 2500;
BA_REL_ "GenSigTimeoutMsg" BU_SG_REL_ CGM_HS SG_ 320 TrnSwAct 320;
BA_REL_ "GenSigSuprvResp" BU_SG_REL_ CGM_HS SG_ 320 TrnSwAct 1;
BA_REL_ "GenSigTimeoutTime" BU_SG_REL_ ECM_HS SG_ 320 TrnSwAct 2500;
BA_REL_ "GenSigTimeoutMsg" BU_SG_REL_ ECM_HS SG_ 320 TrnSwAct 320;
BA_REL_ "GenSigSuprvResp" BU_SG_REL_ ECM_HS SG_ 320 TrnSwAct 1;
BA_REL_ "GenSigTimeoutTime" BU_SG_REL_ EBCM_HS SG_ 320 TrnSwAct 2500;
BA_REL_ "GenSigTimeoutMsg" BU_SG_REL_ EBCM_HS SG_ 320 TrnSwAct 320;
BA_REL_ "GenSigSuprvResp" BU_SG_REL_ EBCM_HS SG_ 320 TrnSwAct 1;
BA_REL_ "GenSigTimeoutTime" BU_SG_REL_ CGM_HS SG_ 320 RrFogLmpsAct 2500;
BA_REL_ "GenSigTimeoutMsg" BU_SG_REL_ CGM_HS SG_ 320 RrFogLmpsAct 320;
BA_REL_ "GenSigSuprvResp" BU_SG_REL_ CGM_HS SG_ 320 RrFogLmpsAct 1;
BA_REL_ "GenSigTimeoutTime" BU_SG_REL_ CGM_HS SG_ 320 OtsdAmbtLtLvlStat 2500;
BA_REL_ "GenSigTimeoutMsg" BU_SG_REL_ CGM_HS SG_ 320 OtsdAmbtLtLvlStat 320;
BA_REL_ "GenSigSuprvResp" BU_SG_REL_ CGM_HS SG_ 320 OtsdAmbtLtLvlStat 1;
BA_REL_ "GenSigTimeoutTime" BU_SG_REL_ ECM_HS SG_ 320 OtsdAmbtLtLvlStat 2500;
BA_REL_ "GenSigTimeoutMsg" BU_SG_REL_ ECM_HS SG_ 320 OtsdAmbtLtLvlStat 320;
BA_REL_ "GenSigSuprvResp" BU_SG_REL_ ECM_HS SG_ 320 OtsdAmbtLtLvlStat 1;
BA_REL_ "GenSigTimeoutTime" BU_SG_REL_ EBCM_HS SG_ 320 OtsdAmbtLtLvlStat 2500;
BA_REL_ "GenSigTimeoutMsg" BU_SG_REL_ EBCM_HS SG_ 320 OtsdAmbtLtLvlStat 320;
BA_REL_ "GenSigRxStartValue" BU_SG_REL_ EBCM_HS SG_ 320 OtsdAmbtLtLvlStat "2";
BA_REL_ "GenSigSuprvResp" BU_SG_REL_ EBCM_HS SG_ 320 OtsdAmbtLtLvlStat 1;
BA_REL_ "GenSigTimeoutTime" BU_SG_REL_ CGM_HS SG_ 320 MainLghtSw 2500;
BA_REL_ "GenSigTimeoutMsg" BU_SG_REL_ CGM_HS SG_ 320 MainLghtSw 320;
BA_REL_ "GenSigSuprvResp" BU_SG_REL_ CGM_HS SG_ 320 MainLghtSw 1;
BA_REL_ "GenSigTimeoutTime" BU_SG_REL_ CGM_HS SG_ 320 LowBmAct 2500;
BA_REL_ "GenSigTimeoutMsg" BU_SG_REL_ CGM_HS SG_ 320 LowBmAct 320;
BA_REL_ "GenSigSuprvResp" BU_SG_REL_ CGM_HS SG_ 320 LowBmAct 1;
BA_REL_ "GenSigTimeoutTime" BU_SG_REL_ CGM_HS SG_ 320 HighBmAct 2500;
BA_REL_ "GenSigTimeoutMsg" BU_SG_REL_ CGM_HS SG_ 320 HighBmAct 320;
BA_REL_ "GenSigSuprvResp" BU_SG_REL_ CGM_HS SG_ 320 HighBmAct 1;
BA_REL_ "GenSigTimeoutTime" BU_SG_REL_ CGM_HS SG_ 320 HdlmpBmSelectStat 2500;
BA_REL_ "GenSigTimeoutMsg" BU_SG_REL_ CGM_HS SG_ 320 HdlmpBmSelectStat 320;
BA_REL_ "GenSigSuprvResp" BU_SG_REL_ CGM_HS SG_ 320 HdlmpBmSelectStat 1;
BA_REL_ "GenSigTimeoutTime" BU_SG_REL_ CGM_HS SG_ 320 FlToPsSwAtv 2500;
BA_REL_ "GenSigTimeoutMsg" BU_SG_REL_ CGM_HS SG_ 320 FlToPsSwAtv 320;
BA_REL_ "GenSigSuprvResp" BU_SG_REL_ CGM_HS SG_ 320 FlToPsSwAtv 1;
BA_REL_ "GenSigTimeoutTime" BU_SG_REL_ CGM_HS SG_ 320 AdvFrntLghtSysEnbld 2500;
BA_REL_ "GenSigTimeoutMsg" BU_SG_REL_ CGM_HS SG_ 320 AdvFrntLghtSysEnbld 320;
BA_REL_ "GenSigSuprvResp" BU_SG_REL_ CGM_HS SG_ 320 AdvFrntLghtSysEnbld 1;
BA_REL_ "GenSigTimeoutTime" BU_SG_REL_ CGM_HS SG_ 320 FrFogLmpsAct 2500;
BA_REL_ "GenSigTimeoutMsg" BU_SG_REL_ CGM_HS SG_ 320 FrFogLmpsAct 320;
BA_REL_ "GenSigSuprvResp" BU_SG_REL_ CGM_HS SG_ 320 FrFogLmpsAct 1;
BA_REL_ "GenSigTimeoutTime" BU_SG_REL_ CGM_HS SG_ 320 AutLghtCtrl 2500;
BA_REL_ "GenSigTimeoutMsg" BU_SG_REL_ CGM_HS SG_ 320 AutLghtCtrl 320;
BA_REL_ "GenSigSuprvResp" BU_SG_REL_ CGM_HS SG_ 320 AutLghtCtrl 1;
BA_REL_ "GenSigRxStartValue" BU_SG_REL_ TCM_HS SG_ 499 PTShftPtrnOvrdAct "False";
BA_REL_ "GenSigRxStartValue" BU_SG_REL_ TCM_HS SG_ 499 PFTrnsTUDSecSwSt "$0 - No Activation";
BA_REL_ "GenSigRxStartValue" BU_SG_REL_ TCM_HS SG_ 499 TrnsPFShftPattSw4Act "False";
BA_REL_ "GenSigRxStartValue" BU_SG_REL_ ECM_HS SG_ 499 TrnsPFShftPattSw4Act "False";
BA_REL_ "GenSigRxStartValue" BU_SG_REL_ TCM_HS SG_ 499 TrnsPFShftPattSw3Act "False";
BA_REL_ "GenSigRxStartValue" BU_SG_REL_ ECM_HS SG_ 499 TrnsPFShftPattSw3Act "False";
BA_REL_ "GenSigRxStartValue" BU_SG_REL_ TCM_HS SG_ 499 TrnsPFShftPattSw2Act "False";
BA_REL_ "GenSigRxStartValue" BU_SG_REL_ ECM_HS SG_ 499 TrnsPFShftPattSw2Act "False";
BA_REL_ "GenSigRxStartValue" BU_SG_REL_ TCM_HS SG_ 499 TrnsPFShftPattSw1Act "False";
BA_REL_ "GenSigRxStartValue" BU_SG_REL_ ECM_HS SG_ 499 TrnsPFShftPattSw1Act "False";
BA_REL_ "GenSigRxStartValue" BU_SG_REL_ TCM_HS SG_ 499 PFTrnsTUDSwSt "$0 - No Activation";
BA_REL_ "GenSigRxStartValue" BU_SG_REL_ TCM_HS SG_ 499 PFTrnsTUDEnSwSt "$0 - No Activation";
BA_REL_ "GenSigTimeoutTime" BU_SG_REL_ EBCM_HS SG_ 298 ValetMdAct 250;
BA_REL_ "GenSigTimeoutMsg" BU_SG_REL_ EBCM_HS SG_ 298 ValetMdAct 298;
BA_REL_ "GenSigSuprvResp" BU_SG_REL_ EBCM_HS SG_ 298 ValetMdAct 1;
BA_REL_ "GenSigTimeoutTime" BU_SG_REL_ CGM_HS SG_ 298 AutoMdSpdLmtCnfrmd 250;
BA_REL_ "GenSigTimeoutMsg" BU_SG_REL_ CGM_HS SG_ 298 AutoMdSpdLmtCnfrmd 298;
BA_REL_ "GenSigSuprvResp" BU_SG_REL_ CGM_HS SG_ 298 AutoMdSpdLmtCnfrmd 1;
BA_REL_ "GenSigTimeoutTime" BU_SG_REL_ ECM_HS SG_ 298 AutoMdSpdLmtCnfrmd 250;
BA_REL_ "GenSigTimeoutMsg" BU_SG_REL_ ECM_HS SG_ 298 AutoMdSpdLmtCnfrmd 298;
BA_REL_ "GenSigSuprvResp" BU_SG_REL_ ECM_HS SG_ 298 AutoMdSpdLmtCnfrmd 1;
BA_REL_ "GenSigTimeoutTime" BU_SG_REL_ ECM_HS SG_ 298 TCSysDisSwAtvARC 250;
BA_REL_ "GenSigTimeoutMsg" BU_SG_REL_ ECM_HS SG_ 298 TCSysDisSwAtvARC 298;
BA_REL_ "GenSigSuprvResp" BU_SG_REL_ ECM_HS SG_ 298 TCSysDisSwAtvARC 1;
BA_REL_ "GenSigTimeoutTime" BU_SG_REL_ EBCM_HS SG_ 298 TCSysDisSwAtvARC 250;
BA_REL_ "GenSigTimeoutMsg" BU_SG_REL_ EBCM_HS SG_ 298 TCSysDisSwAtvARC 298;
BA_REL_ "GenSigSuprvResp" BU_SG_REL_ EBCM_HS SG_ 298 TCSysDisSwAtvARC 1;
BA_REL_ "GenSigTimeoutTime" BU_SG_REL_ CGM_HS SG_ 298 TCSysDisSwAtv_12A 250;
BA_REL_ "GenSigTimeoutMsg" BU_SG_REL_ CGM_HS SG_ 298 TCSysDisSwAtv_12A 298;
BA_REL_ "GenSigSuprvResp" BU_SG_REL_ CGM_HS SG_ 298 TCSysDisSwAtv_12A 1;
BA_REL_ "GenSigTimeoutTime" BU_SG_REL_ ECM_HS SG_ 298 TCSysDisSwAtv_12A 250;
BA_REL_ "GenSigTimeoutMsg" BU_SG_REL_ ECM_HS SG_ 298 TCSysDisSwAtv_12A 298;
BA_REL_ "GenSigSuprvResp" BU_SG_REL_ ECM_HS SG_ 298 TCSysDisSwAtv_12A 1;
BA_REL_ "GenSigTimeoutTime" BU_SG_REL_ CGM_HS SG_ 298 ChmAct 250;
BA_REL_ "GenSigTimeoutMsg" BU_SG_REL_ CGM_HS SG_ 298 ChmAct 298;
BA_REL_ "GenSigSuprvResp" BU_SG_REL_ CGM_HS SG_ 298 ChmAct 1;
BA_REL_ "GenSigTimeoutTime" BU_SG_REL_ CGM_HS SG_ 298 Ky_IdDevPr 250;
BA_REL_ "GenSigTimeoutMsg" BU_SG_REL_ CGM_HS SG_ 298 Ky_IdDevPr 298;
BA_REL_ "GenSigSuprvResp" BU_SG_REL_ CGM_HS SG_ 298 Ky_IdDevPr 1;
BA_REL_ "GenSigTimeoutTime" BU_SG_REL_ EBCM_HS SG_ 298 Ky_IdDevPr 250;
BA_REL_ "GenSigTimeoutMsg" BU_SG_REL_ EBCM_HS SG_ 298 Ky_IdDevPr 298;
BA_REL_ "GenSigSuprvResp" BU_SG_REL_ EBCM_HS SG_ 298 Ky_IdDevPr 1;
BA_REL_ "GenSigTimeoutTime" BU_SG_REL_ CGM_HS SG_ 298 CrshAlrtDrvrSlctdType 250;
BA_REL_ "GenSigTimeoutMsg" BU_SG_REL_ CGM_HS SG_ 298 CrshAlrtDrvrSlctdType 298;
BA_REL_ "GenSigSuprvResp" BU_SG_REL_ CGM_HS SG_ 298 CrshAlrtDrvrSlctdType 1;
BA_REL_ "GenSigTimeoutTime" BU_SG_REL_ EBCM_HS SG_ 298 CrshAlrtDrvrSlctdType 250;
BA_REL_ "GenSigTimeoutMsg" BU_SG_REL_ EBCM_HS SG_ 298 CrshAlrtDrvrSlctdType 298;
BA_REL_ "GenSigSuprvResp" BU_SG_REL_ EBCM_HS SG_ 298 CrshAlrtDrvrSlctdType 1;
BA_REL_ "GenSigTimeoutTime" BU_SG_REL_ CGM_HS SG_ 298 PsSbltAtc 250;
BA_REL_ "GenSigTimeoutMsg" BU_SG_REL_ CGM_HS SG_ 298 PsSbltAtc 298;
BA_REL_ "GenSigSuprvResp" BU_SG_REL_ CGM_HS SG_ 298 PsSbltAtc 1;
BA_REL_ "GenSigTimeoutTime" BU_SG_REL_ EBCM_HS SG_ 298 PsSbltAtc 250;
BA_REL_ "GenSigTimeoutMsg" BU_SG_REL_ EBCM_HS SG_ 298 PsSbltAtc 298;
BA_REL_ "GenSigSuprvResp" BU_SG_REL_ EBCM_HS SG_ 298 PsSbltAtc 1;
BA_REL_ "GenSigTimeoutTime" BU_SG_REL_ CGM_HS SG_ 298 TrlrBrkDsplyAct 250;
BA_REL_ "GenSigTimeoutMsg" BU_SG_REL_ CGM_HS SG_ 298 TrlrBrkDsplyAct 298;
BA_REL_ "GenSigSuprvResp" BU_SG_REL_ CGM_HS SG_ 298 TrlrBrkDsplyAct 1;
BA_REL_ "GenSigTimeoutTime" BU_SG_REL_ EBCM_HS SG_ 298 TrlrBrkDsplyAct 250;
BA_REL_ "GenSigTimeoutMsg" BU_SG_REL_ EBCM_HS SG_ 298 TrlrBrkDsplyAct 298;
BA_REL_ "GenSigVDAFailComment" BU_SG_REL_ EBCM_HS SG_ 298 TrlrBrkDsplyAct "IPCVDA";
BA_REL_ "GenSigVDAFailResp" BU_SG_REL_ EBCM_HS SG_ 298 TrlrBrkDsplyAct 1;
BA_REL_ "GenSigSuprvResp" BU_SG_REL_ EBCM_HS SG_ 298 TrlrBrkDsplyAct 1;
BA_REL_ "GenSigTimeoutTime" BU_SG_REL_ CGM_HS SG_ 298 RdSpdCatType 250;
BA_REL_ "GenSigTimeoutMsg" BU_SG_REL_ CGM_HS SG_ 298 RdSpdCatType 298;
BA_REL_ "GenSigSuprvResp" BU_SG_REL_ CGM_HS SG_ 298 RdSpdCatType 1;
BA_REL_ "GenSigTimeoutTime" BU_SG_REL_ CGM_HS SG_ 298 LnCat 250;
BA_REL_ "GenSigTimeoutMsg" BU_SG_REL_ CGM_HS SG_ 298 LnCat 298;
BA_REL_ "GenSigSuprvResp" BU_SG_REL_ CGM_HS SG_ 298 LnCat 1;
BA_REL_ "GenSigTimeoutTime" BU_SG_REL_ CGM_HS SG_ 298 FncRdClass 250;
BA_REL_ "GenSigTimeoutMsg" BU_SG_REL_ CGM_HS SG_ 298 FncRdClass 298;
BA_REL_ "GenSigSuprvResp" BU_SG_REL_ CGM_HS SG_ 298 FncRdClass 1;
BA_REL_ "GenSigTimeoutTime" BU_SG_REL_ CGM_HS SG_ 298 SprtLnRd 250;
BA_REL_ "GenSigTimeoutMsg" BU_SG_REL_ CGM_HS SG_ 298 SprtLnRd 298;
BA_REL_ "GenSigSuprvResp" BU_SG_REL_ CGM_HS SG_ 298 SprtLnRd 1;
BA_REL_ "GenSigTimeoutTime" BU_SG_REL_ CGM_HS SG_ 298 CntrldAccRd 250;
BA_REL_ "GenSigTimeoutMsg" BU_SG_REL_ CGM_HS SG_ 298 CntrldAccRd 298;
BA_REL_ "GenSigSuprvResp" BU_SG_REL_ CGM_HS SG_ 298 CntrldAccRd 1;
BA_REL_ "GenSigTimeoutTime" BU_SG_REL_ CGM_HS SG_ 298 BldUpArDet 250;
BA_REL_ "GenSigTimeoutMsg" BU_SG_REL_ CGM_HS SG_ 298 BldUpArDet 298;
BA_REL_ "GenSigSuprvResp" BU_SG_REL_ CGM_HS SG_ 298 BldUpArDet 1;
BA_REL_ "GenSigTimeoutTime" BU_SG_REL_ CGM_HS SG_ 298 MpDataAvlbl 250;
BA_REL_ "GenSigTimeoutMsg" BU_SG_REL_ CGM_HS SG_ 298 MpDataAvlbl 298;
BA_REL_ "GenSigSuprvResp" BU_SG_REL_ CGM_HS SG_ 298 MpDataAvlbl 1;
BA_REL_ "GenSigTimeoutTime" BU_SG_REL_ CGM_HS SG_ 298 SusCustStngReq 250;
BA_REL_ "GenSigTimeoutMsg" BU_SG_REL_ CGM_HS SG_ 298 SusCustStngReq 298;
BA_REL_ "GenSigSuprvResp" BU_SG_REL_ CGM_HS SG_ 298 SusCustStngReq 1;
BA_REL_ "GenSigTimeoutTime" BU_SG_REL_ EBCM_HS SG_ 298 SusCustStngReq 250;
BA_REL_ "GenSigTimeoutMsg" BU_SG_REL_ EBCM_HS SG_ 298 SusCustStngReq 298;
BA_REL_ "GenSigSuprvResp" BU_SG_REL_ EBCM_HS SG_ 298 SusCustStngReq 1;
BA_REL_ "GenSigTimeoutTime" BU_SG_REL_ CGM_HS SG_ 298 StrCustStngReq 250;
BA_REL_ "GenSigTimeoutMsg" BU_SG_REL_ CGM_HS SG_ 298 StrCustStngReq 298;
BA_REL_ "GenSigSuprvResp" BU_SG_REL_ CGM_HS SG_ 298 StrCustStngReq 1;
BA_REL_ "GenSigTimeoutTime" BU_SG_REL_ EBCM_HS SG_ 298 StrCustStngReq 250;
BA_REL_ "GenSigTimeoutMsg" BU_SG_REL_ EBCM_HS SG_ 298 StrCustStngReq 298;
BA_REL_ "GenSigSuprvResp" BU_SG_REL_ EBCM_HS SG_ 298 StrCustStngReq 1;
BA_REL_ "GenSigTimeoutTime" BU_SG_REL_ CGM_HS SG_ 298 RstrCustFctrDef 250;
BA_REL_ "GenSigTimeoutMsg" BU_SG_REL_ CGM_HS SG_ 298 RstrCustFctrDef 298;
BA_REL_ "GenSigSuprvResp" BU_SG_REL_ CGM_HS SG_ 298 RstrCustFctrDef 1;
BA_REL_ "GenSigTimeoutTime" BU_SG_REL_ EBCM_HS SG_ 298 RstrCustFctrDef 250;
BA_REL_ "GenSigTimeoutMsg" BU_SG_REL_ EBCM_HS SG_ 298 RstrCustFctrDef 298;
BA_REL_ "GenSigSuprvResp" BU_SG_REL_ EBCM_HS SG_ 298 RstrCustFctrDef 1;
BA_REL_ "GenSigTimeoutTime" BU_SG_REL_ CGM_HS SG_ 298 DrvlnCustStngReq 250;
BA_REL_ "GenSigTimeoutMsg" BU_SG_REL_ CGM_HS SG_ 298 DrvlnCustStngReq 298;
BA_REL_ "GenSigSuprvResp" BU_SG_REL_ CGM_HS SG_ 298 DrvlnCustStngReq 1;
BA_REL_ "GenSigTimeoutTime" BU_SG_REL_ EBCM_HS SG_ 298 DrvlnCustStngReq 250;
BA_REL_ "GenSigTimeoutMsg" BU_SG_REL_ EBCM_HS SG_ 298 DrvlnCustStngReq 298;
BA_REL_ "GenSigSuprvResp" BU_SG_REL_ EBCM_HS SG_ 298 DrvlnCustStngReq 1;
BA_REL_ "GenSigTimeoutTime" BU_SG_REL_ CGM_HS SG_ 298 RRDoorAjarSwAct 250;
BA_REL_ "GenSigTimeoutMsg" BU_SG_REL_ CGM_HS SG_ 298 RRDoorAjarSwAct 298;
BA_REL_ "GenSigSuprvResp" BU_SG_REL_ CGM_HS SG_ 298 RRDoorAjarSwAct 1;
BA_REL_ "GenSigTimeoutTime" BU_SG_REL_ CGM_HS SG_ 298 PDAjrSwAtv 250;
BA_REL_ "GenSigTimeoutMsg" BU_SG_REL_ CGM_HS SG_ 298 PDAjrSwAtv 298;
BA_REL_ "GenSigSuprvResp" BU_SG_REL_ CGM_HS SG_ 298 PDAjrSwAtv 1;
BA_REL_ "GenSigTimeoutTime" BU_SG_REL_ CGM_HS SG_ 298 DDAjrSwAtv 250;
BA_REL_ "GenSigTimeoutMsg" BU_SG_REL_ CGM_HS SG_ 298 DDAjrSwAtv 298;
BA_REL_ "GenSigSuprvResp" BU_SG_REL_ CGM_HS SG_ 298 DDAjrSwAtv 1;
BA_REL_ "GenSigTimeoutTime" BU_SG_REL_ ECM_HS SG_ 298 DDAjrSwAtv 250;
BA_REL_ "GenSigTimeoutMsg" BU_SG_REL_ ECM_HS SG_ 298 DDAjrSwAtv 298;
BA_REL_ "GenSigVDAFailComment" BU_SG_REL_ ECM_HS SG_ 298 DDAjrSwAtv "DrvrDrAjrSwVDA";
BA_REL_ "GenSigVDAFailResp" BU_SG_REL_ ECM_HS SG_ 298 DDAjrSwAtv 1;
BA_REL_ "GenSigSuprvResp" BU_SG_REL_ ECM_HS SG_ 298 DDAjrSwAtv 1;
BA_REL_ "GenSigTimeoutTime" BU_SG_REL_ EBCM_HS SG_ 298 DDAjrSwAtv 250;
BA_REL_ "GenSigTimeoutMsg" BU_SG_REL_ EBCM_HS SG_ 298 DDAjrSwAtv 298;
BA_REL_ "GenSigSuprvResp" BU_SG_REL_ EBCM_HS SG_ 298 DDAjrSwAtv 1;
BA_REL_ "GenSigTimeoutTime" BU_SG_REL_ CGM_HS SG_ 298 DrId 250;
BA_REL_ "GenSigTimeoutMsg" BU_SG_REL_ CGM_HS SG_ 298 DrId 298;
BA_REL_ "GenSigSuprvResp" BU_SG_REL_ CGM_HS SG_ 298 DrId 1;
BA_REL_ "GenSigTimeoutTime" BU_SG_REL_ EBCM_HS SG_ 298 DrId 250;
BA_REL_ "GenSigTimeoutMsg" BU_SG_REL_ EBCM_HS SG_ 298 DrId 298;
BA_REL_ "GenSigSuprvResp" BU_SG_REL_ EBCM_HS SG_ 298 DrId 1;
BA_REL_ "GenSigTimeoutTime" BU_SG_REL_ CGM_HS SG_ 298 EnrgMgtLdShdRq 250;
BA_REL_ "GenSigTimeoutMsg" BU_SG_REL_ CGM_HS SG_ 298 EnrgMgtLdShdRq 298;
BA_REL_ "GenSigSuprvResp" BU_SG_REL_ CGM_HS SG_ 298 EnrgMgtLdShdRq 1;
BA_REL_ "GenSigTimeoutTime" BU_SG_REL_ CGM_HS SG_ 298 TrlrHtchSwAtv 250;
BA_REL_ "GenSigTimeoutMsg" BU_SG_REL_ CGM_HS SG_ 298 TrlrHtchSwAtv 298;
BA_REL_ "GenSigSuprvResp" BU_SG_REL_ CGM_HS SG_ 298 TrlrHtchSwAtv 1;
BA_REL_ "GenSigTimeoutTime" BU_SG_REL_ RDCM_HS SG_ 298 TrlrHtchSwAtv 250;
BA_REL_ "GenSigTimeoutMsg" BU_SG_REL_ RDCM_HS SG_ 298 TrlrHtchSwAtv 298;
BA_REL_ "GenSigVDAFailComment" BU_SG_REL_ RDCM_HS SG_ 298 TrlrHtchSwAtv "Trailer Hardware Interface Virtual Device Availability";
BA_REL_ "GenSigVDAFailResp" BU_SG_REL_ RDCM_HS SG_ 298 TrlrHtchSwAtv 1;
BA_REL_ "GenSigSuprvResp" BU_SG_REL_ RDCM_HS SG_ 298 TrlrHtchSwAtv 1;
BA_REL_ "GenSigTimeoutTime" BU_SG_REL_ ECM_HS SG_ 298 TrlrHtchSwAtv 250;
BA_REL_ "GenSigTimeoutMsg" BU_SG_REL_ ECM_HS SG_ 298 TrlrHtchSwAtv 298;
BA_REL_ "GenSigSuprvResp" BU_SG_REL_ ECM_HS SG_ 298 TrlrHtchSwAtv 1;
BA_REL_ "GenSigTimeoutTime" BU_SG_REL_ EBCM_HS SG_ 298 TrlrHtchSwAtv 250;
BA_REL_ "GenSigTimeoutMsg" BU_SG_REL_ EBCM_HS SG_ 298 TrlrHtchSwAtv 298;
BA_REL_ "GenSigSuprvResp" BU_SG_REL_ EBCM_HS SG_ 298 TrlrHtchSwAtv 1;
BA_REL_ "GenSigTimeoutTime" BU_SG_REL_ CGM_HS SG_ 298 TreInfMonSysRstReq 250;
BA_REL_ "GenSigTimeoutMsg" BU_SG_REL_ CGM_HS SG_ 298 TreInfMonSysRstReq 298;
BA_REL_ "GenSigSuprvResp" BU_SG_REL_ CGM_HS SG_ 298 TreInfMonSysRstReq 1;
BA_REL_ "GenSigTimeoutTime" BU_SG_REL_ EBCM_HS SG_ 298 TreInfMonSysRstReq 250;
BA_REL_ "GenSigTimeoutMsg" BU_SG_REL_ EBCM_HS SG_ 298 TreInfMonSysRstReq 298;
BA_REL_ "GenSigSuprvResp" BU_SG_REL_ EBCM_HS SG_ 298 TreInfMonSysRstReq 1;
BA_REL_ "GenSigTimeoutTime" BU_SG_REL_ CGM_HS SG_ 298 HUDActv 250;
BA_REL_ "GenSigTimeoutMsg" BU_SG_REL_ CGM_HS SG_ 298 HUDActv 298;
BA_REL_ "GenSigSuprvResp" BU_SG_REL_ CGM_HS SG_ 298 HUDActv 1;
BA_REL_ "GenSigTimeoutTime" BU_SG_REL_ CGM_HS SG_ 298 BatVlt 250;
BA_REL_ "GenSigTimeoutMsg" BU_SG_REL_ CGM_HS SG_ 298 BatVlt 298;
BA_REL_ "GenSigSuprvResp" BU_SG_REL_ CGM_HS SG_ 298 BatVlt 1;
BA_REL_ "GenSigTimeoutTime" BU_SG_REL_ TCM_HS SG_ 298 BatVlt 250;
BA_REL_ "GenSigTimeoutMsg" BU_SG_REL_ TCM_HS SG_ 298 BatVlt 298;
BA_REL_ "GenSigSuprvResp" BU_SG_REL_ TCM_HS SG_ 298 BatVlt 1;
BA_REL_ "GenSigTimeoutTime" BU_SG_REL_ ECM_HS SG_ 298 BatVlt 250;
BA_REL_ "GenSigTimeoutMsg" BU_SG_REL_ ECM_HS SG_ 298 BatVlt 298;
BA_REL_ "GenSigSuprvResp" BU_SG_REL_ ECM_HS SG_ 298 BatVlt 1;
BA_REL_ "GenSigTimeoutTime" BU_SG_REL_ CGM_HS SG_ 298 RLDoorAjarSwAct 250;
BA_REL_ "GenSigTimeoutMsg" BU_SG_REL_ CGM_HS SG_ 298 RLDoorAjarSwAct 298;
BA_REL_ "GenSigSuprvResp" BU_SG_REL_ CGM_HS SG_ 298 RLDoorAjarSwAct 1;
BA_REL_ "GenSigTimeoutTime" BU_SG_REL_ CGM_HS SG_ 298 DrSbltAtc 250;
BA_REL_ "GenSigTimeoutMsg" BU_SG_REL_ CGM_HS SG_ 298 DrSbltAtc 298;
BA_REL_ "GenSigSuprvResp" BU_SG_REL_ CGM_HS SG_ 298 DrSbltAtc 1;
BA_REL_ "GenSigTimeoutTime" BU_SG_REL_ ECM_HS SG_ 298 DrSbltAtc 250;
BA_REL_ "GenSigTimeoutMsg" BU_SG_REL_ ECM_HS SG_ 298 DrSbltAtc 298;
BA_REL_ "GenSigSuprvResp" BU_SG_REL_ ECM_HS SG_ 298 DrSbltAtc 1;
BA_REL_ "GenSigTimeoutTime" BU_SG_REL_ EBCM_HS SG_ 298 DrSbltAtc 250;
BA_REL_ "GenSigTimeoutMsg" BU_SG_REL_ EBCM_HS SG_ 298 DrSbltAtc 298;
BA_REL_ "GenSigSuprvResp" BU_SG_REL_ EBCM_HS SG_ 298 DrSbltAtc 1;
BA_REL_ "GenSigTimeoutTime" BU_SG_REL_ RDCM_HS SG_ 1322 TireRRPrsStat 2500;
BA_REL_ "GenSigTimeoutMsg" BU_SG_REL_ RDCM_HS SG_ 1322 TireRRPrsStat 1322;
BA_REL_ "GenSigSuprvResp" BU_SG_REL_ RDCM_HS SG_ 1322 TireRRPrsStat 1;
BA_REL_ "GenSigTimeoutTime" BU_SG_REL_ EBCM_HS SG_ 1322 TireRRPrsStat 2500;
BA_REL_ "GenSigTimeoutMsg" BU_SG_REL_ EBCM_HS SG_ 1322 TireRRPrsStat 1322;
BA_REL_ "GenSigSuprvResp" BU_SG_REL_ EBCM_HS SG_ 1322 TireRRPrsStat 1;
BA_REL_ "GenSigTimeoutTime" BU_SG_REL_ RDCM_HS SG_ 1322 TireRRPrs 2500;
BA_REL_ "GenSigTimeoutMsg" BU_SG_REL_ RDCM_HS SG_ 1322 TireRRPrs 1322;
BA_REL_ "GenSigSuprvResp" BU_SG_REL_ RDCM_HS SG_ 1322 TireRRPrs 1;
BA_REL_ "GenSigTimeoutTime" BU_SG_REL_ EBCM_HS SG_ 1322 TireRRPrs 2500;
BA_REL_ "GenSigTimeoutMsg" BU_SG_REL_ EBCM_HS SG_ 1322 TireRRPrs 1322;
BA_REL_ "GenSigSuprvResp" BU_SG_REL_ EBCM_HS SG_ 1322 TireRRPrs 1;
BA_REL_ "GenSigTimeoutTime" BU_SG_REL_ RDCM_HS SG_ 1322 TireRFPrsStat 2500;
BA_REL_ "GenSigTimeoutMsg" BU_SG_REL_ RDCM_HS SG_ 1322 TireRFPrsStat 1322;
BA_REL_ "GenSigSuprvResp" BU_SG_REL_ RDCM_HS SG_ 1322 TireRFPrsStat 1;
BA_REL_ "GenSigTimeoutTime" BU_SG_REL_ EBCM_HS SG_ 1322 TireRFPrsStat 2500;
BA_REL_ "GenSigTimeoutMsg" BU_SG_REL_ EBCM_HS SG_ 1322 TireRFPrsStat 1322;
BA_REL_ "GenSigSuprvResp" BU_SG_REL_ EBCM_HS SG_ 1322 TireRFPrsStat 1;
BA_REL_ "GenSigTimeoutTime" BU_SG_REL_ RDCM_HS SG_ 1322 TireRFPrs 2500;
BA_REL_ "GenSigTimeoutMsg" BU_SG_REL_ RDCM_HS SG_ 1322 TireRFPrs 1322;
BA_REL_ "GenSigSuprvResp" BU_SG_REL_ RDCM_HS SG_ 1322 TireRFPrs 1;
BA_REL_ "GenSigTimeoutTime" BU_SG_REL_ EBCM_HS SG_ 1322 TireRFPrs 2500;
BA_REL_ "GenSigTimeoutMsg" BU_SG_REL_ EBCM_HS SG_ 1322 TireRFPrs 1322;
BA_REL_ "GenSigSuprvResp" BU_SG_REL_ EBCM_HS SG_ 1322 TireRFPrs 1;
BA_REL_ "GenSigTimeoutTime" BU_SG_REL_ RDCM_HS SG_ 1322 TireLRPrsStat 2500;
BA_REL_ "GenSigTimeoutMsg" BU_SG_REL_ RDCM_HS SG_ 1322 TireLRPrsStat 1322;
BA_REL_ "GenSigSuprvResp" BU_SG_REL_ RDCM_HS SG_ 1322 TireLRPrsStat 1;
BA_REL_ "GenSigTimeoutTime" BU_SG_REL_ EBCM_HS SG_ 1322 TireLRPrsStat 2500;
BA_REL_ "GenSigTimeoutMsg" BU_SG_REL_ EBCM_HS SG_ 1322 TireLRPrsStat 1322;
BA_REL_ "GenSigSuprvResp" BU_SG_REL_ EBCM_HS SG_ 1322 TireLRPrsStat 1;
BA_REL_ "GenSigTimeoutTime" BU_SG_REL_ RDCM_HS SG_ 1322 TireLRPrs 2500;
BA_REL_ "GenSigTimeoutMsg" BU_SG_REL_ RDCM_HS SG_ 1322 TireLRPrs 1322;
BA_REL_ "GenSigSuprvResp" BU_SG_REL_ RDCM_HS SG_ 1322 TireLRPrs 1;
BA_REL_ "GenSigTimeoutTime" BU_SG_REL_ EBCM_HS SG_ 1322 TireLRPrs 2500;
BA_REL_ "GenSigTimeoutMsg" BU_SG_REL_ EBCM_HS SG_ 1322 TireLRPrs 1322;
BA_REL_ "GenSigSuprvResp" BU_SG_REL_ EBCM_HS SG_ 1322 TireLRPrs 1;
BA_REL_ "GenSigTimeoutTime" BU_SG_REL_ RDCM_HS SG_ 1322 TireLFPrsStat 2500;
BA_REL_ "GenSigTimeoutMsg" BU_SG_REL_ RDCM_HS SG_ 1322 TireLFPrsStat 1322;
BA_REL_ "GenSigSuprvResp" BU_SG_REL_ RDCM_HS SG_ 1322 TireLFPrsStat 1;
BA_REL_ "GenSigTimeoutTime" BU_SG_REL_ EBCM_HS SG_ 1322 TireLFPrsStat 2500;
BA_REL_ "GenSigTimeoutMsg" BU_SG_REL_ EBCM_HS SG_ 1322 TireLFPrsStat 1322;
BA_REL_ "GenSigSuprvResp" BU_SG_REL_ EBCM_HS SG_ 1322 TireLFPrsStat 1;
BA_REL_ "GenSigTimeoutTime" BU_SG_REL_ RDCM_HS SG_ 1322 TireLFPrs 2500;
BA_REL_ "GenSigTimeoutMsg" BU_SG_REL_ RDCM_HS SG_ 1322 TireLFPrs 1322;
BA_REL_ "GenSigSuprvResp" BU_SG_REL_ RDCM_HS SG_ 1322 TireLFPrs 1;
BA_REL_ "GenSigTimeoutTime" BU_SG_REL_ EBCM_HS SG_ 1322 TireLFPrs 2500;
BA_REL_ "GenSigTimeoutMsg" BU_SG_REL_ EBCM_HS SG_ 1322 TireLFPrs 1322;
BA_REL_ "GenSigSuprvResp" BU_SG_REL_ EBCM_HS SG_ 1322 TireLFPrs 1;
BA_REL_ "GenSigTimeoutTime" BU_SG_REL_ CGM_HS SG_ 1300 VehIdNmDig2_9 2500;
BA_REL_ "GenSigTimeoutMsg" BU_SG_REL_ CGM_HS SG_ 1300 VehIdNmDig2_9 1300;
BA_REL_ "GenSigSuprvResp" BU_SG_REL_ CGM_HS SG_ 1300 VehIdNmDig2_9 1;
BA_REL_ "GenSigTimeoutTime" BU_SG_REL_ RDCM_HS SG_ 1300 VehIdNmDig2_9 2500;
BA_REL_ "GenSigTimeoutMsg" BU_SG_REL_ RDCM_HS SG_ 1300 VehIdNmDig2_9 1300;
BA_REL_ "GenSigSuprvResp" BU_SG_REL_ RDCM_HS SG_ 1300 VehIdNmDig2_9 1;
BA_REL_ "GenSigTimeoutTime" BU_SG_REL_ EBCM_HS SG_ 1300 VehIdNmDig2_9 2500;
BA_REL_ "GenSigTimeoutMsg" BU_SG_REL_ EBCM_HS SG_ 1300 VehIdNmDig2_9 1300;
BA_REL_ "GenSigSuprvResp" BU_SG_REL_ EBCM_HS SG_ 1300 VehIdNmDig2_9 1;
BA_REL_ "GenSigTimeoutMsg" BU_SG_REL_ CGM_HS SG_ 288 VehOdo 288;
BA_REL_ "GenSigSuprvResp" BU_SG_REL_ CGM_HS SG_ 288 VehOdo 1;
BA_REL_ "GenSigTimeoutMsg" BU_SG_REL_ RDCM_HS SG_ 288 VehOdo 288;
BA_REL_ "GenSigSuprvResp" BU_SG_REL_ RDCM_HS SG_ 288 VehOdo 1;
BA_REL_ "GenSigTimeoutTime" BU_SG_REL_ ECM_HS SG_ 288 VehOdo 2500;
BA_REL_ "GenSigTimeoutMsg" BU_SG_REL_ ECM_HS SG_ 288 VehOdo 288;
BA_REL_ "GenSigSuprvResp" BU_SG_REL_ ECM_HS SG_ 288 VehOdo 1;
BA_REL_ "GenSigTimeoutMsg" BU_SG_REL_ EBCM_HS SG_ 288 VehOdo 288;
BA_REL_ "GenSigSuprvResp" BU_SG_REL_ EBCM_HS SG_ 288 VehOdo 1;
BA_REL_ "GenSigTimeoutTime" BU_SG_REL_ ECM_HS SG_ 1009 EngAirFltMonDrvrReq 625;
BA_REL_ "GenSigTimeoutMsg" BU_SG_REL_ ECM_HS SG_ 1009 EngAirFltMonDrvrReq 1009;
BA_REL_ "GenSigSuprvResp" BU_SG_REL_ ECM_HS SG_ 1009 EngAirFltMonDrvrReq 1;
BA_REL_ "GenSigTimeoutTime" BU_SG_REL_ ECM_HS SG_ 1009 RstrctdPTOpModeReqd 625;
BA_REL_ "GenSigTimeoutMsg" BU_SG_REL_ ECM_HS SG_ 1009 RstrctdPTOpModeReqd 1009;
BA_REL_ "GenSigSuprvResp" BU_SG_REL_ ECM_HS SG_ 1009 RstrctdPTOpModeReqd 1;
BA_REL_ "GenSigTimeoutTime" BU_SG_REL_ ECM_HS SG_ 1009 ClmtCtrlHtrEngRunRq 625;
BA_REL_ "GenSigTimeoutMsg" BU_SG_REL_ ECM_HS SG_ 1009 ClmtCtrlHtrEngRunRq 1009;
BA_REL_ "GenSigSuprvResp" BU_SG_REL_ ECM_HS SG_ 1009 ClmtCtrlHtrEngRunRq 1;
BA_REL_ "GenSigRxStartValue" BU_SG_REL_ ECM_HS SG_ 1009 OutAirTempVDA "$1 - Virtual Device Available";
BA_REL_ "GenSigTimeoutTime" BU_SG_REL_ RDCM_HS SG_ 1009 OtsAirTmpCrVal 625;
BA_REL_ "GenSigTimeoutMsg" BU_SG_REL_ RDCM_HS SG_ 1009 OtsAirTmpCrVal 1009;
BA_REL_ "GenSigSuprvResp" BU_SG_REL_ RDCM_HS SG_ 1009 OtsAirTmpCrVal 1;
BA_REL_ "GenSigTimeoutTime" BU_SG_REL_ EPS_HS SG_ 1009 OtsAirTmpCrVal 625;
BA_REL_ "GenSigTimeoutMsg" BU_SG_REL_ EPS_HS SG_ 1009 OtsAirTmpCrVal 1009;
BA_REL_ "GenSigSuprvResp" BU_SG_REL_ EPS_HS SG_ 1009 OtsAirTmpCrVal 1;
BA_REL_ "GenSigTimeoutTime" BU_SG_REL_ EBCM_HS SG_ 1009 OtsAirTmpCrVal 625;
BA_REL_ "GenSigTimeoutMsg" BU_SG_REL_ EBCM_HS SG_ 1009 OtsAirTmpCrVal 1009;
BA_REL_ "GenSigSuprvResp" BU_SG_REL_ EBCM_HS SG_ 1009 OtsAirTmpCrVal 1;
BA_REL_ "GenSigTimeoutTime" BU_SG_REL_ EBCM_HS SG_ 1009 EngOffTmVDA 625;
BA_REL_ "GenSigTimeoutMsg" BU_SG_REL_ EBCM_HS SG_ 1009 EngOffTmVDA 1009;
BA_REL_ "GenSigSuprvResp" BU_SG_REL_ EBCM_HS SG_ 1009 EngOffTmVDA 1;
BA_REL_ "GenSigTimeoutTime" BU_SG_REL_ ECM_HS SG_ 1009 IntDimDspLvl 625;
BA_REL_ "GenSigTimeoutMsg" BU_SG_REL_ ECM_HS SG_ 1009 IntDimDspLvl 1009;
BA_REL_ "GenSigSuprvResp" BU_SG_REL_ ECM_HS SG_ 1009 IntDimDspLvl 1;
BA_REL_ "GenSigTimeoutTime" BU_SG_REL_ EBCM_HS SG_ 1009 IntDimDspLvl 625;
BA_REL_ "GenSigTimeoutMsg" BU_SG_REL_ EBCM_HS SG_ 1009 IntDimDspLvl 1009;
BA_REL_ "GenSigRxStartValue" BU_SG_REL_ EBCM_HS SG_ 1009 IntDimDspLvl "0";
BA_REL_ "GenSigSuprvResp" BU_SG_REL_ EBCM_HS SG_ 1009 IntDimDspLvl 1;
BA_REL_ "GenSigTimeoutTime" BU_SG_REL_ RDCM_HS SG_ 1009 EngOffTmExtRng 625;
BA_REL_ "GenSigTimeoutMsg" BU_SG_REL_ RDCM_HS SG_ 1009 EngOffTmExtRng 1009;
BA_REL_ "GenSigVBitResp" BU_SG_REL_ RDCM_HS SG_ 1009 EngOffTmExtRng 1;
BA_REL_ "GenSigSuprvResp" BU_SG_REL_ RDCM_HS SG_ 1009 EngOffTmExtRng 1;
BA_REL_ "GenSigTimeoutTime" BU_SG_REL_ EBCM_HS SG_ 1009 EngOffTmExtRng 625;
BA_REL_ "GenSigTimeoutMsg" BU_SG_REL_ EBCM_HS SG_ 1009 EngOffTmExtRng 1009;
BA_REL_ "GenSigSuprvResp" BU_SG_REL_ EBCM_HS SG_ 1009 EngOffTmExtRng 1;
BA_REL_ "GenSigTimeoutTime" BU_SG_REL_ ECM_HS SG_ 1009 PF_MinIdlBstLvlReq 625;
BA_REL_ "GenSigTimeoutMsg" BU_SG_REL_ ECM_HS SG_ 1009 PF_MinIdlBstLvlReq 1009;
BA_REL_ "GenSigRxStartValue" BU_SG_REL_ ECM_HS SG_ 1009 PF_MinIdlBstLvlReq "$0 - No Boost Requested";
BA_REL_ "GenSigSuprvResp" BU_SG_REL_ ECM_HS SG_ 1009 PF_MinIdlBstLvlReq 1;
BA_REL_ "GenSigTimeoutTime" BU_SG_REL_ ECM_HS SG_ 1009 VehTopSpdLmtReq 625;
BA_REL_ "GenSigTimeoutMsg" BU_SG_REL_ ECM_HS SG_ 1009 VehTopSpdLmtReq 1009;
BA_REL_ "GenSigSuprvResp" BU_SG_REL_ ECM_HS SG_ 1009 VehTopSpdLmtReq 1;
BA_REL_ "GenSigTimeoutTime" BU_SG_REL_ RDCM_HS SG_ 1257 ElpsdTimeCntRstOcc 2500;
BA_REL_ "GenSigTimeoutMsg" BU_SG_REL_ RDCM_HS SG_ 1257 ElpsdTimeCntRstOcc 1257;
BA_REL_ "GenSigSuprvResp" BU_SG_REL_ RDCM_HS SG_ 1257 ElpsdTimeCntRstOcc 1;
BA_REL_ "GenSigTimeoutTime" BU_SG_REL_ RDCM_HS SG_ 1257 ElpsdTimeCnt 2500;
BA_REL_ "GenSigTimeoutMsg" BU_SG_REL_ RDCM_HS SG_ 1257 ElpsdTimeCnt 1257;
BA_REL_ "GenSigSuprvResp" BU_SG_REL_ RDCM_HS SG_ 1257 ElpsdTimeCnt 1;
BA_REL_ "GenSigTimeoutTime" BU_SG_REL_ BCM_HS SG_ 505 AllNodesVNA_1F9 250;
BA_REL_ "GenSigTimeoutMsg" BU_SG_REL_ BCM_HS SG_ 505 AllNodesVNA_1F9 505;
BA_REL_ "GenSigSuprvResp" BU_SG_REL_ BCM_HS SG_ 505 AllNodesVNA_1F9 1;
BA_REL_ "GenSigTimeoutTime" BU_SG_REL_ BCM_HS SG_ 505 PTOVehTopSpdLimVal 250;
BA_REL_ "GenSigTimeoutMsg" BU_SG_REL_ BCM_HS SG_ 505 PTOVehTopSpdLimVal 505;
BA_REL_ "GenSigSuprvResp" BU_SG_REL_ BCM_HS SG_ 505 PTOVehTopSpdLimVal 1;
BA_REL_ "GenSigTimeoutTime" BU_SG_REL_ ECM_HS SG_ 505 AccPdlPwrTkOffOvrAct 75;
BA_REL_ "GenSigTimeoutMsg" BU_SG_REL_ ECM_HS SG_ 505 AccPdlPwrTkOffOvrAct 505;
BA_REL_ "GenSigRxStartValue" BU_SG_REL_ ECM_HS SG_ 505 AccPdlPwrTkOffOvrAct "False";
BA_REL_ "GenSigSuprvResp" BU_SG_REL_ ECM_HS SG_ 505 AccPdlPwrTkOffOvrAct 1;
BA_REL_ "GenSigRxStartValue" BU_SG_REL_ ECM_HS SG_ 505 FstIdlMdAct "False";
BA_REL_ "GenSigRxStartValue" BU_SG_REL_ ECM_HS SG_ 505 PTOMdAct "False";
BA_REL_ "GenSigTimeoutTime" BU_SG_REL_ EBCM_HS SG_ 505 PTOMdAct 250;
BA_REL_ "GenSigTimeoutMsg" BU_SG_REL_ EBCM_HS SG_ 505 PTOMdAct 505;
BA_REL_ "GenSigSuprvResp" BU_SG_REL_ EBCM_HS SG_ 505 PTOMdAct 1;
BA_REL_ "GenSigRxStartValue" BU_SG_REL_ ECM_HS SG_ 505 PTOEngTrqLmtRchd "False";
BA_REL_ "GenSigRxStartValue" BU_SG_REL_ ECM_HS SG_ 505 PTOEngTrqLmtValER "2040 Nm";
BA_REL_ "GenSigRxStartValue" BU_SG_REL_ TCM_HS SG_ 505 PltfrmEngSpdCmdMdAct "False";
BA_REL_ "GenSigRxStartValue" BU_SG_REL_ ECM_HS SG_ 505 PltfrmEngSpdCmdMdAct "False";
BA_REL_ "GenSigTimeoutTime" BU_SG_REL_ EBCM_HS SG_ 505 PltfrmEngSpdCmdMdAct 250;
BA_REL_ "GenSigTimeoutMsg" BU_SG_REL_ EBCM_HS SG_ 505 PltfrmEngSpdCmdMdAct 505;
BA_REL_ "GenSigSuprvResp" BU_SG_REL_ EBCM_HS SG_ 505 PltfrmEngSpdCmdMdAct 1;
BA_REL_ "GenSigRxStartValue" BU_SG_REL_ TCM_HS SG_ 505 PltfrmEngSpdReq "0 RPM";
BA_REL_ "GenSigRxStartValue" BU_SG_REL_ ECM_HS SG_ 505 PltfrmEngSpdReq "0 RPM";
BA_REL_ "GenSigTimeoutTime" BU_SG_REL_ EBCM_HS SG_ 505 PltfrmEngSpdReq 250;
BA_REL_ "GenSigTimeoutMsg" BU_SG_REL_ EBCM_HS SG_ 505 PltfrmEngSpdReq 505;
BA_REL_ "GenSigSuprvResp" BU_SG_REL_ EBCM_HS SG_ 505 PltfrmEngSpdReq 1;
BA_REL_ "GenSigRxStartValue" BU_SG_REL_ ECM_HS SG_ 505 PFESpdCmdOnSwAct "False";
BA_REL_ "GenSigRxStartValue" BU_SG_REL_ ECM_HS SG_ 505 PFESpdCmdDeSwAct "False";
BA_REL_ "GenSigRxStartValue" BU_SG_REL_ ECM_HS SG_ 505 PFESpdCmdInSwAct "False";
BA_REL_ "GenSigRxStartValue" BU_SG_REL_ ECM_HS SG_ 505 PFESpdCmdSwDIntg "$1 - Data Invalid";
BA_REL_ "GenSigTimeoutTime" BU_SG_REL_ EBCM_HS SG_ 505 PFEngSpdCmdAlvRlgCnt 250;
BA_REL_ "GenSigTimeoutMsg" BU_SG_REL_ EBCM_HS SG_ 505 PFEngSpdCmdAlvRlgCnt 505;
BA_REL_ "GenSigSuprvResp" BU_SG_REL_ EBCM_HS SG_ 505 PFEngSpdCmdAlvRlgCnt 1;
BA_REL_ "GenSigTimeoutTime" BU_SG_REL_ EBCM_HS SG_ 505 PltfrmEngSpdCmdProtVal 250;
BA_REL_ "GenSigTimeoutMsg" BU_SG_REL_ EBCM_HS SG_ 505 PltfrmEngSpdCmdProtVal 505;
BA_REL_ "GenSigSuprvResp" BU_SG_REL_ EBCM_HS SG_ 505 PltfrmEngSpdCmdProtVal 1;
BA_REL_ "GenSigTimeoutTime" BU_SG_REL_ ECM_HS SG_ 505 PTORmtEngShtdwnReqd 75;
BA_REL_ "GenSigTimeoutMsg" BU_SG_REL_ ECM_HS SG_ 505 PTORmtEngShtdwnReqd 505;
BA_REL_ "GenSigRxStartValue" BU_SG_REL_ ECM_HS SG_ 505 PTORmtEngShtdwnReqd "False";
BA_REL_ "GenSigSuprvResp" BU_SG_REL_ ECM_HS SG_ 505 PTORmtEngShtdwnReqd 1;
BA_REL_ "GenSigTimeoutTime" BU_SG_REL_ BCM_HS SG_ 505 PTORmtEngShtdwnReqd 250;
BA_REL_ "GenSigTimeoutMsg" BU_SG_REL_ BCM_HS SG_ 505 PTORmtEngShtdwnReqd 505;
BA_REL_ "GenSigSuprvRespSubValue" BU_SG_REL_ BCM_HS SG_ 505 PTORmtEngShtdwnReqd 1;
BA_REL_ "GenSigSuprvResp" BU_SG_REL_ BCM_HS SG_ 505 PTORmtEngShtdwnReqd 2;
BA_REL_ "GenSigTimeoutTime" BU_SG_REL_ CGM_HS SG_ 497 ElvtdIdlCstStReq 250;
BA_REL_ "GenSigTimeoutMsg" BU_SG_REL_ CGM_HS SG_ 497 ElvtdIdlCstStReq 497;
BA_REL_ "GenSigSuprvResp" BU_SG_REL_ CGM_HS SG_ 497 ElvtdIdlCstStReq 1;
BA_REL_ "GenSigTimeoutTime" BU_SG_REL_ ECM_HS SG_ 497 ElvtdIdlCstStReq 250;
BA_REL_ "GenSigTimeoutMsg" BU_SG_REL_ ECM_HS SG_ 497 ElvtdIdlCstStReq 497;
BA_REL_ "GenSigSuprvResp" BU_SG_REL_ ECM_HS SG_ 497 ElvtdIdlCstStReq 1;
BA_REL_ "GenSigTimeoutTime" BU_SG_REL_ CGM_HS SG_ 497 FuelFltLfRstRqd 250;
BA_REL_ "GenSigTimeoutMsg" BU_SG_REL_ CGM_HS SG_ 497 FuelFltLfRstRqd 497;
BA_REL_ "GenSigSuprvResp" BU_SG_REL_ CGM_HS SG_ 497 FuelFltLfRstRqd 1;
BA_REL_ "GenSigTimeoutTime" BU_SG_REL_ EBCM_HS SG_ 497 BkupPwrModeMstrVDA 250;
BA_REL_ "GenSigTimeoutMsg" BU_SG_REL_ EBCM_HS SG_ 497 BkupPwrModeMstrVDA 497;
BA_REL_ "GenSigSuprvResp" BU_SG_REL_ EBCM_HS SG_ 497 BkupPwrModeMstrVDA 2;
BA_REL_ "GenSigTimeoutTime" BU_SG_REL_ CGM_HS SG_ 497 SysBkupPwrMdEn 250;
BA_REL_ "GenSigTimeoutMsg" BU_SG_REL_ CGM_HS SG_ 497 SysBkupPwrMdEn 497;
BA_REL_ "GenSigSuprvResp" BU_SG_REL_ CGM_HS SG_ 497 SysBkupPwrMdEn 1;
BA_REL_ "GenSigTimeoutTime" BU_SG_REL_ TCM_HS SG_ 497 SysBkupPwrMdEn 250;
BA_REL_ "GenSigTimeoutMsg" BU_SG_REL_ TCM_HS SG_ 497 SysBkupPwrMdEn 497;
BA_REL_ "GenSigSuprvResp" BU_SG_REL_ TCM_HS SG_ 497 SysBkupPwrMdEn 1;
BA_REL_ "GenSigTimeoutTime" BU_SG_REL_ RDCM_HS SG_ 497 SysBkupPwrMdEn 250;
BA_REL_ "GenSigTimeoutMsg" BU_SG_REL_ RDCM_HS SG_ 497 SysBkupPwrMdEn 497;
BA_REL_ "GenSigSuprvResp" BU_SG_REL_ RDCM_HS SG_ 497 SysBkupPwrMdEn 1;
BA_REL_ "GenSigTimeoutTime" BU_SG_REL_ ECM_HS SG_ 497 SysBkupPwrMdEn 250;
BA_REL_ "GenSigTimeoutMsg" BU_SG_REL_ ECM_HS SG_ 497 SysBkupPwrMdEn 497;
BA_REL_ "GenSigSuprvResp" BU_SG_REL_ ECM_HS SG_ 497 SysBkupPwrMdEn 1;
BA_REL_ "GenSigTimeoutTime" BU_SG_REL_ EPS_HS SG_ 497 SysBkupPwrMdEn 500;
BA_REL_ "GenSigTimeoutMsg" BU_SG_REL_ EPS_HS SG_ 497 SysBkupPwrMdEn 497;
BA_REL_ "GenSigSuprvResp" BU_SG_REL_ EPS_HS SG_ 497 SysBkupPwrMdEn 1;
BA_REL_ "GenSigTimeoutTime" BU_SG_REL_ EBCM_HS SG_ 497 SysBkupPwrMdEn 250;
BA_REL_ "GenSigTimeoutMsg" BU_SG_REL_ EBCM_HS SG_ 497 SysBkupPwrMdEn 497;
BA_REL_ "GenSigVDAFailComment" BU_SG_REL_ EBCM_HS SG_ 497 SysBkupPwrMdEn "Backup Power Mode Master Virtual Device Availability";
BA_REL_ "GenSigVDAFailResp" BU_SG_REL_ EBCM_HS SG_ 497 SysBkupPwrMdEn 1;
BA_REL_ "GenSigSuprvResp" BU_SG_REL_ EBCM_HS SG_ 497 SysBkupPwrMdEn 1;
BA_REL_ "GenSigTimeoutTime" BU_SG_REL_ CGM_HS SG_ 497 SysBkUpPwrMd 250;
BA_REL_ "GenSigTimeoutMsg" BU_SG_REL_ CGM_HS SG_ 497 SysBkUpPwrMd 497;
BA_REL_ "GenSigSuprvResp" BU_SG_REL_ CGM_HS SG_ 497 SysBkUpPwrMd 1;
BA_REL_ "GenSigTimeoutTime" BU_SG_REL_ TCM_HS SG_ 497 SysBkUpPwrMd 250;
BA_REL_ "GenSigTimeoutMsg" BU_SG_REL_ TCM_HS SG_ 497 SysBkUpPwrMd 497;
BA_REL_ "GenSigSuprvResp" BU_SG_REL_ TCM_HS SG_ 497 SysBkUpPwrMd 1;
BA_REL_ "GenSigTimeoutTime" BU_SG_REL_ RDCM_HS SG_ 497 SysBkUpPwrMd 250;
BA_REL_ "GenSigTimeoutMsg" BU_SG_REL_ RDCM_HS SG_ 497 SysBkUpPwrMd 497;
BA_REL_ "GenSigSuprvResp" BU_SG_REL_ RDCM_HS SG_ 497 SysBkUpPwrMd 1;
BA_REL_ "GenSigTimeoutTime" BU_SG_REL_ ECM_HS SG_ 497 SysBkUpPwrMd 250;
BA_REL_ "GenSigTimeoutMsg" BU_SG_REL_ ECM_HS SG_ 497 SysBkUpPwrMd 497;
BA_REL_ "GenSigSuprvResp" BU_SG_REL_ ECM_HS SG_ 497 SysBkUpPwrMd 1;
BA_REL_ "GenSigTimeoutTime" BU_SG_REL_ EPS_HS SG_ 497 SysBkUpPwrMd 500;
BA_REL_ "GenSigTimeoutMsg" BU_SG_REL_ EPS_HS SG_ 497 SysBkUpPwrMd 497;
BA_REL_ "GenSigSuprvResp" BU_SG_REL_ EPS_HS SG_ 497 SysBkUpPwrMd 1;
BA_REL_ "GenSigTimeoutTime" BU_SG_REL_ EBCM_HS SG_ 497 SysBkUpPwrMd 250;
BA_REL_ "GenSigTimeoutMsg" BU_SG_REL_ EBCM_HS SG_ 497 SysBkUpPwrMd 497;
BA_REL_ "GenSigSuprvResp" BU_SG_REL_ EBCM_HS SG_ 497 SysBkUpPwrMd 1;
BA_REL_ "GenSigTimeoutTime" BU_SG_REL_ CGM_HS SG_ 497 SysPwrMd 250;
BA_REL_ "GenSigTimeoutMsg" BU_SG_REL_ CGM_HS SG_ 497 SysPwrMd 497;
BA_REL_ "GenSigSuprvResp" BU_SG_REL_ CGM_HS SG_ 497 SysPwrMd 1;
BA_REL_ "GenSigTimeoutTime" BU_SG_REL_ TCM_HS SG_ 497 SysPwrMd 250;
BA_REL_ "GenSigTimeoutMsg" BU_SG_REL_ TCM_HS SG_ 497 SysPwrMd 497;
BA_REL_ "GenSigSuprvResp" BU_SG_REL_ TCM_HS SG_ 497 SysPwrMd 1;
BA_REL_ "GenSigTimeoutTime" BU_SG_REL_ RDCM_HS SG_ 497 SysPwrMd 250;
BA_REL_ "GenSigTimeoutMsg" BU_SG_REL_ RDCM_HS SG_ 497 SysPwrMd 497;
BA_REL_ "GenSigSuprvResp" BU_SG_REL_ RDCM_HS SG_ 497 SysPwrMd 1;
BA_REL_ "GenSigTimeoutTime" BU_SG_REL_ ECM_HS SG_ 497 SysPwrMd 250;
BA_REL_ "GenSigTimeoutMsg" BU_SG_REL_ ECM_HS SG_ 497 SysPwrMd 497;
BA_REL_ "GenSigSuprvResp" BU_SG_REL_ ECM_HS SG_ 497 SysPwrMd 1;
BA_REL_ "GenSigTimeoutTime" BU_SG_REL_ EPS_HS SG_ 497 SysPwrMd 500;
BA_REL_ "GenSigTimeoutMsg" BU_SG_REL_ EPS_HS SG_ 497 SysPwrMd 497;
BA_REL_ "GenSigSuprvResp" BU_SG_REL_ EPS_HS SG_ 497 SysPwrMd 1;
BA_REL_ "GenSigTimeoutTime" BU_SG_REL_ EBCM_HS SG_ 497 SysPwrMd 250;
BA_REL_ "GenSigTimeoutMsg" BU_SG_REL_ EBCM_HS SG_ 497 SysPwrMd 497;
BA_REL_ "GenSigSuprvResp" BU_SG_REL_ EBCM_HS SG_ 497 SysPwrMd 1;
BA_REL_ "GenSigTimeoutTime" BU_SG_REL_ BSM_HS SG_ 497 SysPwrMd 500;
BA_REL_ "GenSigTimeoutMsg" BU_SG_REL_ BSM_HS SG_ 497 SysPwrMd 497;
BA_REL_ "GenSigSuprvResp" BU_SG_REL_ BSM_HS SG_ 497 SysPwrMd 1;
BA_REL_ "GenSigTimeoutTime" BU_SG_REL_ CGM_HS SG_ 497 TrStLgMdAtv 250;
BA_REL_ "GenSigTimeoutMsg" BU_SG_REL_ CGM_HS SG_ 497 TrStLgMdAtv 497;
BA_REL_ "GenSigSuprvResp" BU_SG_REL_ CGM_HS SG_ 497 TrStLgMdAtv 1;
BA_REL_ "GenSigTimeoutTime" BU_SG_REL_ EBCM_HS SG_ 497 TrStLgMdAtv 250;
BA_REL_ "GenSigTimeoutMsg" BU_SG_REL_ EBCM_HS SG_ 497 TrStLgMdAtv 497;
BA_REL_ "GenSigSuprvResp" BU_SG_REL_ EBCM_HS SG_ 497 TrStLgMdAtv 1;
BA_REL_ "GenSigTimeoutTime" BU_SG_REL_ CGM_HS SG_ 497 DispMeasSys 250;
BA_REL_ "GenSigTimeoutMsg" BU_SG_REL_ CGM_HS SG_ 497 DispMeasSys 497;
BA_REL_ "GenSigSuprvResp" BU_SG_REL_ CGM_HS SG_ 497 DispMeasSys 1;
BA_REL_ "GenSigTimeoutTime" BU_SG_REL_ CGM_HS SG_ 497 ACCmpsrFldOn 250;
BA_REL_ "GenSigTimeoutMsg" BU_SG_REL_ CGM_HS SG_ 497 ACCmpsrFldOn 497;
BA_REL_ "GenSigSuprvResp" BU_SG_REL_ CGM_HS SG_ 497 ACCmpsrFldOn 1;
BA_REL_ "GenSigTimeoutTime" BU_SG_REL_ CGM_HS SG_ 497 ACCompModReq 250;
BA_REL_ "GenSigTimeoutMsg" BU_SG_REL_ CGM_HS SG_ 497 ACCompModReq 497;
BA_REL_ "GenSigSuprvResp" BU_SG_REL_ CGM_HS SG_ 497 ACCompModReq 1;
BA_REL_ "GenSigTimeoutTime" BU_SG_REL_ CGM_HS SG_ 497 ACCompNormLd 250;
BA_REL_ "GenSigTimeoutMsg" BU_SG_REL_ CGM_HS SG_ 497 ACCompNormLd 497;
BA_REL_ "GenSigSuprvResp" BU_SG_REL_ CGM_HS SG_ 497 ACCompNormLd 1;
BA_REL_ "GenSigVBitResp" BU_SG_REL_ ECM_HS SG_ 497 ACCompNormLd 1;
BA_REL_ "GenSigVDAFailComment" BU_SG_REL_ ECM_HS SG_ 497 ACCompNormLd "Air Conditioning Compressor System VDA";
BA_REL_ "GenSigVDAFailResp" BU_SG_REL_ ECM_HS SG_ 497 ACCompNormLd 1;
BA_REL_ "GenSigTimeoutTime" BU_SG_REL_ CGM_HS SG_ 497 PTORSMstrEngShtReq 250;
BA_REL_ "GenSigTimeoutMsg" BU_SG_REL_ CGM_HS SG_ 497 PTORSMstrEngShtReq 497;
BA_REL_ "GenSigSuprvResp" BU_SG_REL_ CGM_HS SG_ 497 PTORSMstrEngShtReq 1;
BA_REL_ "GenSigTimeoutTime" BU_SG_REL_ ECM_HS SG_ 497 PTORSMstrEngShtReq 250;
BA_REL_ "GenSigTimeoutMsg" BU_SG_REL_ ECM_HS SG_ 497 PTORSMstrEngShtReq 497;
BA_REL_ "GenSigRxStartValue" BU_SG_REL_ ECM_HS SG_ 497 PTORSMstrEngShtReq "False";
BA_REL_ "GenSigSuprvResp" BU_SG_REL_ ECM_HS SG_ 497 PTORSMstrEngShtReq 1;
BA_REL_ "GenSigTimeoutTime" BU_SG_REL_ CGM_HS SG_ 497 EngOilLfRstRq 250;
BA_REL_ "GenSigTimeoutMsg" BU_SG_REL_ CGM_HS SG_ 497 EngOilLfRstRq 497;
BA_REL_ "GenSigSuprvResp" BU_SG_REL_ CGM_HS SG_ 497 EngOilLfRstRq 1;
BA_REL_ "GenSigTimeoutTime" BU_SG_REL_ CGM_HS SG_ 497 SIRDpl 250;
BA_REL_ "GenSigTimeoutMsg" BU_SG_REL_ CGM_HS SG_ 497 SIRDpl 497;
BA_REL_ "GenSigSuprvResp" BU_SG_REL_ CGM_HS SG_ 497 SIRDpl 1;
BA_REL_ "GenSigRxStartValue" BU_SG_REL_ ECM_HS SG_ 497 SIRDpl "False";
BA_REL_ "GenSigTimeoutTime" BU_SG_REL_ CGM_HS SG_ 497 PTORmStMsEngStRq 250;
BA_REL_ "GenSigTimeoutMsg" BU_SG_REL_ CGM_HS SG_ 497 PTORmStMsEngStRq 497;
BA_REL_ "GenSigSuprvResp" BU_SG_REL_ CGM_HS SG_ 497 PTORmStMsEngStRq 1;
BA_REL_ "GenSigTimeoutTime" BU_SG_REL_ TCM_HS SG_ 497 PTORmStMsEngStRq 250;
BA_REL_ "GenSigTimeoutMsg" BU_SG_REL_ TCM_HS SG_ 497 PTORmStMsEngStRq 497;
BA_REL_ "GenSigSuprvResp" BU_SG_REL_ TCM_HS SG_ 497 PTORmStMsEngStRq 1;
BA_REL_ "GenSigTimeoutTime" BU_SG_REL_ CGM_HS SG_ 497 RmVehStrRq 250;
BA_REL_ "GenSigTimeoutMsg" BU_SG_REL_ CGM_HS SG_ 497 RmVehStrRq 497;
BA_REL_ "GenSigSuprvResp" BU_SG_REL_ CGM_HS SG_ 497 RmVehStrRq 1;
BA_REL_ "GenSigTimeoutTime" BU_SG_REL_ CGM_HS SG_ 497 ThrtlPrgrsnReq 250;
BA_REL_ "GenSigTimeoutMsg" BU_SG_REL_ CGM_HS SG_ 497 ThrtlPrgrsnReq 497;
BA_REL_ "GenSigSuprvResp" BU_SG_REL_ CGM_HS SG_ 497 ThrtlPrgrsnReq 1;
BA_REL_ "GenSigTimeoutTime" BU_SG_REL_ ECM_HS SG_ 497 ThrtlPrgrsnReq 250;
BA_REL_ "GenSigTimeoutMsg" BU_SG_REL_ ECM_HS SG_ 497 ThrtlPrgrsnReq 497;
BA_REL_ "GenSigRxStartValue" BU_SG_REL_ ECM_HS SG_ 497 ThrtlPrgrsnReq "$0 - Map A";
BA_REL_ "GenSigSuprvResp" BU_SG_REL_ ECM_HS SG_ 497 ThrtlPrgrsnReq 1;
BA_REL_ "GenSigTimeoutTime" BU_SG_REL_ CGM_HS SG_ 497 PrkBrkSwAtv 250;
BA_REL_ "GenSigTimeoutMsg" BU_SG_REL_ CGM_HS SG_ 497 PrkBrkSwAtv 497;
BA_REL_ "GenSigSuprvResp" BU_SG_REL_ CGM_HS SG_ 497 PrkBrkSwAtv 1;
BA_REL_ "GenSigTimeoutTime" BU_SG_REL_ RDCM_HS SG_ 497 PrkBrkSwAtv 250;
BA_REL_ "GenSigTimeoutMsg" BU_SG_REL_ RDCM_HS SG_ 497 PrkBrkSwAtv 497;
BA_REL_ "GenSigSuprvResp" BU_SG_REL_ RDCM_HS SG_ 497 PrkBrkSwAtv 1;
BA_REL_ "GenSigTimeoutTime" BU_SG_REL_ EBCM_HS SG_ 497 PrkBrkSwAtv 250;
BA_REL_ "GenSigTimeoutMsg" BU_SG_REL_ EBCM_HS SG_ 497 PrkBrkSwAtv 497;
BA_REL_ "GenSigSuprvResp" BU_SG_REL_ EBCM_HS SG_ 497 PrkBrkSwAtv 1;
BA_REL_ "GenSigTimeoutTime" BU_SG_REL_ CGM_HS SG_ 497 PMMAccTrmSt 250;
BA_REL_ "GenSigTimeoutMsg" BU_SG_REL_ CGM_HS SG_ 497 PMMAccTrmSt 497;
BA_REL_ "GenSigSuprvResp" BU_SG_REL_ CGM_HS SG_ 497 PMMAccTrmSt 1;
BA_REL_ "GenSigTimeoutTime" BU_SG_REL_ CGM_HS SG_ 497 PMMRunCrkTrmSt 250;
BA_REL_ "GenSigTimeoutMsg" BU_SG_REL_ CGM_HS SG_ 497 PMMRunCrkTrmSt 497;
BA_REL_ "GenSigSuprvResp" BU_SG_REL_ CGM_HS SG_ 497 PMMRunCrkTrmSt 1;
BA_REL_ "GenSigTimeoutTime" BU_SG_REL_ CGM_HS SG_ 497 ImmblzrPreRelPswdStat 250;
BA_REL_ "GenSigTimeoutMsg" BU_SG_REL_ CGM_HS SG_ 497 ImmblzrPreRelPswdStat 497;
BA_REL_ "GenSigSuprvResp" BU_SG_REL_ CGM_HS SG_ 497 ImmblzrPreRelPswdStat 1;
BA_REL_ "GenSigRxStartValue" BU_SG_REL_ ECM_HS SG_ 497 ImmblzrPreRelPswdStat "$0 - No Information";
BA_REL_ "GenSigTimeoutTime" BU_SG_REL_ CGM_HS SG_ 497 ImmblzrPreRelPswrd 250;
BA_REL_ "GenSigTimeoutMsg" BU_SG_REL_ CGM_HS SG_ 497 ImmblzrPreRelPswrd 497;
BA_REL_ "GenSigSuprvResp" BU_SG_REL_ CGM_HS SG_ 497 ImmblzrPreRelPswrd 1;
BA_REL_ "GenSigTimeoutTime" BU_SG_REL_ CGM_HS SG_ 1249 VehIdNmDig10_17 2500;
BA_REL_ "GenSigTimeoutMsg" BU_SG_REL_ CGM_HS SG_ 1249 VehIdNmDig10_17 1249;
BA_REL_ "GenSigSuprvResp" BU_SG_REL_ CGM_HS SG_ 1249 VehIdNmDig10_17 1;
BA_REL_ "GenSigTimeoutTime" BU_SG_REL_ RDCM_HS SG_ 1249 VehIdNmDig10_17 2500;
BA_REL_ "GenSigTimeoutMsg" BU_SG_REL_ RDCM_HS SG_ 1249 VehIdNmDig10_17 1249;
BA_REL_ "GenSigSuprvResp" BU_SG_REL_ RDCM_HS SG_ 1249 VehIdNmDig10_17 1;
BA_REL_ "GenSigTimeoutTime" BU_SG_REL_ EBCM_HS SG_ 1249 VehIdNmDig10_17 2500;
BA_REL_ "GenSigTimeoutMsg" BU_SG_REL_ EBCM_HS SG_ 1249 VehIdNmDig10_17 1249;
BA_REL_ "GenSigSuprvResp" BU_SG_REL_ EBCM_HS SG_ 1249 VehIdNmDig10_17 1;
BA_REL_ "GenSigTimeoutTime" BU_SG_REL_ CGM_HS SG_ 481 CrsSecSwStat 250;
BA_REL_ "GenSigTimeoutMsg" BU_SG_REL_ CGM_HS SG_ 481 CrsSecSwStat 481;
BA_REL_ "GenSigSuprvResp" BU_SG_REL_ CGM_HS SG_ 481 CrsSecSwStat 1;
BA_REL_ "GenSigTimeoutTime" BU_SG_REL_ CGM_HS SG_ 481 DrvSelMdSw3Sta 250;
BA_REL_ "GenSigTimeoutMsg" BU_SG_REL_ CGM_HS SG_ 481 DrvSelMdSw3Sta 481;
BA_REL_ "GenSigSuprvResp" BU_SG_REL_ CGM_HS SG_ 481 DrvSelMdSw3Sta 1;
BA_REL_ "GenSigTimeoutTime" BU_SG_REL_ CGM_HS SG_ 481 DrvSelMdSw2Sta 250;
BA_REL_ "GenSigTimeoutMsg" BU_SG_REL_ CGM_HS SG_ 481 DrvSelMdSw2Sta 481;
BA_REL_ "GenSigSuprvResp" BU_SG_REL_ CGM_HS SG_ 481 DrvSelMdSw2Sta 1;
BA_REL_ "GenSigTimeoutTime" BU_SG_REL_ CGM_HS SG_ 481 AuxHtrRq 250;
BA_REL_ "GenSigTimeoutMsg" BU_SG_REL_ CGM_HS SG_ 481 AuxHtrRq 481;
BA_REL_ "GenSigSuprvResp" BU_SG_REL_ CGM_HS SG_ 481 AuxHtrRq 1;
BA_REL_ "GenSigTimeoutTime" BU_SG_REL_ CGM_HS SG_ 481 AuxHtrAtv 250;
BA_REL_ "GenSigTimeoutMsg" BU_SG_REL_ CGM_HS SG_ 481 AuxHtrAtv 481;
BA_REL_ "GenSigSuprvResp" BU_SG_REL_ CGM_HS SG_ 481 AuxHtrAtv 1;
BA_REL_ "GenSigTimeoutTime" BU_SG_REL_ CGM_HS SG_ 481 DrvSelMdSw1Sta 250;
BA_REL_ "GenSigTimeoutMsg" BU_SG_REL_ CGM_HS SG_ 481 DrvSelMdSw1Sta 481;
BA_REL_ "GenSigSuprvResp" BU_SG_REL_ CGM_HS SG_ 481 DrvSelMdSw1Sta 1;
BA_REL_ "GenSigTimeoutTime" BU_SG_REL_ CGM_HS SG_ 481 FuelMdSwAct 250;
BA_REL_ "GenSigTimeoutMsg" BU_SG_REL_ CGM_HS SG_ 481 FuelMdSwAct 481;
BA_REL_ "GenSigSuprvResp" BU_SG_REL_ CGM_HS SG_ 481 FuelMdSwAct 1;
BA_REL_ "GenSigTimeoutTime" BU_SG_REL_ CGM_HS SG_ 481 CrsSpdLmtrSwStat 250;
BA_REL_ "GenSigTimeoutMsg" BU_SG_REL_ CGM_HS SG_ 481 CrsSpdLmtrSwStat 481;
BA_REL_ "GenSigSuprvResp" BU_SG_REL_ CGM_HS SG_ 481 CrsSpdLmtrSwStat 1;
BA_REL_ "GenSigTimeoutTime" BU_SG_REL_ EBCM_HS SG_ 481 CrsSpdLmtrSwStat 250;
BA_REL_ "GenSigTimeoutMsg" BU_SG_REL_ EBCM_HS SG_ 481 CrsSpdLmtrSwStat 481;
BA_REL_ "GenSigSuprvResp" BU_SG_REL_ EBCM_HS SG_ 481 CrsSpdLmtrSwStat 1;
BA_REL_ "GenSigTimeoutTime" BU_SG_REL_ CGM_HS SG_ 481 AdptCrsGapSwAct 250;
BA_REL_ "GenSigTimeoutMsg" BU_SG_REL_ CGM_HS SG_ 481 AdptCrsGapSwAct 481;
BA_REL_ "GenSigSuprvResp" BU_SG_REL_ CGM_HS SG_ 481 AdptCrsGapSwAct 1;
BA_REL_ "GenSigTimeoutTime" BU_SG_REL_ CGM_HS SG_ 481 CrsCntrlSwStCanSwAct 250;
BA_REL_ "GenSigTimeoutMsg" BU_SG_REL_ CGM_HS SG_ 481 CrsCntrlSwStCanSwAct 481;
BA_REL_ "GenSigSuprvResp" BU_SG_REL_ CGM_HS SG_ 481 CrsCntrlSwStCanSwAct 1;
BA_REL_ "GenSigTimeoutTime" BU_SG_REL_ CGM_HS SG_ 481 CrsCntrlSwStSwDataIntgty 250;
BA_REL_ "GenSigTimeoutMsg" BU_SG_REL_ CGM_HS SG_ 481 CrsCntrlSwStSwDataIntgty 481;
BA_REL_ "GenSigSuprvResp" BU_SG_REL_ CGM_HS SG_ 481 CrsCntrlSwStSwDataIntgty 1;
BA_REL_ "GenSigTimeoutTime" BU_SG_REL_ CGM_HS SG_ 481 CrsCntrlSwStSpdInSwAct 250;
BA_REL_ "GenSigTimeoutMsg" BU_SG_REL_ CGM_HS SG_ 481 CrsCntrlSwStSpdInSwAct 481;
BA_REL_ "GenSigSuprvResp" BU_SG_REL_ CGM_HS SG_ 481 CrsCntrlSwStSpdInSwAct 1;
BA_REL_ "GenSigTimeoutTime" BU_SG_REL_ CGM_HS SG_ 481 CrsCntrlSwStSpDcSwAct 250;
BA_REL_ "GenSigTimeoutMsg" BU_SG_REL_ CGM_HS SG_ 481 CrsCntrlSwStSpDcSwAct 481;
BA_REL_ "GenSigSuprvResp" BU_SG_REL_ CGM_HS SG_ 481 CrsCntrlSwStSpDcSwAct 1;
BA_REL_ "GenSigTimeoutTime" BU_SG_REL_ CGM_HS SG_ 481 CrsCntrlSwStSetSwAct 250;
BA_REL_ "GenSigTimeoutMsg" BU_SG_REL_ CGM_HS SG_ 481 CrsCntrlSwStSetSwAct 481;
BA_REL_ "GenSigSuprvResp" BU_SG_REL_ CGM_HS SG_ 481 CrsCntrlSwStSetSwAct 1;
BA_REL_ "GenSigTimeoutTime" BU_SG_REL_ CGM_HS SG_ 481 CrsCntrlSwStResSwAct 250;
BA_REL_ "GenSigTimeoutMsg" BU_SG_REL_ CGM_HS SG_ 481 CrsCntrlSwStResSwAct 481;
BA_REL_ "GenSigSuprvResp" BU_SG_REL_ CGM_HS SG_ 481 CrsCntrlSwStResSwAct 1;
BA_REL_ "GenSigTimeoutTime" BU_SG_REL_ CGM_HS SG_ 481 CrsCntrlSwStOnSwAct 250;
BA_REL_ "GenSigTimeoutMsg" BU_SG_REL_ CGM_HS SG_ 481 CrsCntrlSwStOnSwAct 481;
BA_REL_ "GenSigSuprvResp" BU_SG_REL_ CGM_HS SG_ 481 CrsCntrlSwStOnSwAct 1;
BA_REL_ "GenSigTimeoutTime" BU_SG_REL_ CGM_HS SG_ 481 CrsCntCncRq 250;
BA_REL_ "GenSigTimeoutMsg" BU_SG_REL_ CGM_HS SG_ 481 CrsCntCncRq 481;
BA_REL_ "GenSigSuprvResp" BU_SG_REL_ CGM_HS SG_ 481 CrsCntCncRq 1;
BA_REL_ "GenSigTimeoutTime" BU_SG_REL_ EPS_HS SG_ 241 NotEventStat 250;
BA_REL_ "GenSigTimeoutMsg" BU_SG_REL_ EPS_HS SG_ 241 NotEventStat 241;
BA_REL_ "GenSigSuprvResp" BU_SG_REL_ EPS_HS SG_ 241 NotEventStat 1;
BA_REL_ "GenSigTimeoutTime" BU_SG_REL_ CGM_HS SG_ 241 NotEventStat 250;
BA_REL_ "GenSigTimeoutMsg" BU_SG_REL_ CGM_HS SG_ 241 NotEventStat 241;
BA_REL_ "GenSigSuprvResp" BU_SG_REL_ CGM_HS SG_ 241 NotEventStat 1;
BA_REL_ "GenSigTimeoutTime" BU_SG_REL_ EBCM_HS SG_ 241 NotEventStat 250;
BA_REL_ "GenSigTimeoutMsg" BU_SG_REL_ EBCM_HS SG_ 241 NotEventStat 241;
BA_REL_ "GenSigSuprvResp" BU_SG_REL_ EBCM_HS SG_ 241 NotEventStat 1;
BA_REL_ "GenSigTimeoutTime" BU_SG_REL_ CGM_HS SG_ 241 BrkPdlChkData 250;
BA_REL_ "GenSigTimeoutMsg" BU_SG_REL_ CGM_HS SG_ 241 BrkPdlChkData 241;
BA_REL_ "GenSigSuprvResp" BU_SG_REL_ CGM_HS SG_ 241 BrkPdlChkData 1;
BA_REL_ "GenSigTimeoutTime" BU_SG_REL_ EPS_HS SG_ 241 BrkAppSnsrHmPosLrnd 250;
BA_REL_ "GenSigTimeoutMsg" BU_SG_REL_ EPS_HS SG_ 241 BrkAppSnsrHmPosLrnd 241;
BA_REL_ "GenSigSuprvResp" BU_SG_REL_ EPS_HS SG_ 241 BrkAppSnsrHmPosLrnd 1;
BA_REL_ "GenSigTimeoutTime" BU_SG_REL_ CGM_HS SG_ 241 BrkAppSnsrHmPosLrnd 250;
BA_REL_ "GenSigTimeoutMsg" BU_SG_REL_ CGM_HS SG_ 241 BrkAppSnsrHmPosLrnd 241;
BA_REL_ "GenSigSuprvResp" BU_SG_REL_ CGM_HS SG_ 241 BrkAppSnsrHmPosLrnd 1;
BA_REL_ "GenSigTimeoutTime" BU_SG_REL_ EBCM_HS SG_ 241 BrkAppSnsrHmPosLrnd 250;
BA_REL_ "GenSigTimeoutMsg" BU_SG_REL_ EBCM_HS SG_ 241 BrkAppSnsrHmPosLrnd 241;
BA_REL_ "GenSigSuprvResp" BU_SG_REL_ EBCM_HS SG_ 241 BrkAppSnsrHmPosLrnd 1;
BA_REL_ "GenSigTimeoutTime" BU_SG_REL_ RDCM_HS SG_ 241 BrkPedTrvlAchvd 250;
BA_REL_ "GenSigTimeoutMsg" BU_SG_REL_ RDCM_HS SG_ 241 BrkPedTrvlAchvd 241;
BA_REL_ "GenSigSuprvResp" BU_SG_REL_ RDCM_HS SG_ 241 BrkPedTrvlAchvd 1;
BA_REL_ "GenSigTimeoutTime" BU_SG_REL_ ECM_HS SG_ 241 BrkPedTrvlAchvd 250;
BA_REL_ "GenSigTimeoutMsg" BU_SG_REL_ ECM_HS SG_ 241 BrkPedTrvlAchvd 241;
BA_REL_ "GenSigSuprvResp" BU_SG_REL_ ECM_HS SG_ 241 BrkPedTrvlAchvd 1;
BA_REL_ "GenSigTimeoutTime" BU_SG_REL_ EPS_HS SG_ 241 BrkPedTrvlAchvd 250;
BA_REL_ "GenSigTimeoutMsg" BU_SG_REL_ EPS_HS SG_ 241 BrkPedTrvlAchvd 241;
BA_REL_ "GenSigSuprvResp" BU_SG_REL_ EPS_HS SG_ 241 BrkPedTrvlAchvd 1;
BA_REL_ "GenSigTimeoutTime" BU_SG_REL_ CGM_HS SG_ 241 BrkPedTrvlAchvd 250;
BA_REL_ "GenSigTimeoutMsg" BU_SG_REL_ CGM_HS SG_ 241 BrkPedTrvlAchvd 241;
BA_REL_ "GenSigSuprvResp" BU_SG_REL_ CGM_HS SG_ 241 BrkPedTrvlAchvd 1;
BA_REL_ "GenSigTimeoutTime" BU_SG_REL_ EBCM_HS SG_ 241 BrkPedTrvlAchvd 250;
BA_REL_ "GenSigTimeoutMsg" BU_SG_REL_ EBCM_HS SG_ 241 BrkPedTrvlAchvd 241;
BA_REL_ "GenSigSuprvResp" BU_SG_REL_ EBCM_HS SG_ 241 BrkPedTrvlAchvd 1;
BA_REL_ "GenSigTimeoutTime" BU_SG_REL_ BSM_HS SG_ 241 BrkPedTrvlAchvd 500;
BA_REL_ "GenSigTimeoutMsg" BU_SG_REL_ BSM_HS SG_ 241 BrkPedTrvlAchvd 241;
BA_REL_ "GenSigSuprvResp" BU_SG_REL_ BSM_HS SG_ 241 BrkPedTrvlAchvd 1;
BA_REL_ "GenSigTimeoutTime" BU_SG_REL_ RDCM_HS SG_ 241 BrkPedTrvlAchvdV 250;
BA_REL_ "GenSigTimeoutMsg" BU_SG_REL_ RDCM_HS SG_ 241 BrkPedTrvlAchvdV 241;
BA_REL_ "GenSigSuprvResp" BU_SG_REL_ RDCM_HS SG_ 241 BrkPedTrvlAchvdV 1;
BA_REL_ "GenSigTimeoutTime" BU_SG_REL_ ECM_HS SG_ 241 BrkPedTrvlAchvdV 250;
BA_REL_ "GenSigTimeoutMsg" BU_SG_REL_ ECM_HS SG_ 241 BrkPedTrvlAchvdV 241;
BA_REL_ "GenSigSuprvResp" BU_SG_REL_ ECM_HS SG_ 241 BrkPedTrvlAchvdV 1;
BA_REL_ "GenSigTimeoutTime" BU_SG_REL_ EPS_HS SG_ 241 BrkPedTrvlAchvdV 250;
BA_REL_ "GenSigTimeoutMsg" BU_SG_REL_ EPS_HS SG_ 241 BrkPedTrvlAchvdV 241;
BA_REL_ "GenSigSuprvResp" BU_SG_REL_ EPS_HS SG_ 241 BrkPedTrvlAchvdV 1;
BA_REL_ "GenSigTimeoutTime" BU_SG_REL_ CGM_HS SG_ 241 BrkPedTrvlAchvdV 250;
BA_REL_ "GenSigTimeoutMsg" BU_SG_REL_ CGM_HS SG_ 241 BrkPedTrvlAchvdV 241;
BA_REL_ "GenSigSuprvResp" BU_SG_REL_ CGM_HS SG_ 241 BrkPedTrvlAchvdV 1;
BA_REL_ "GenSigTimeoutTime" BU_SG_REL_ EBCM_HS SG_ 241 BrkPedTrvlAchvdV 250;
BA_REL_ "GenSigTimeoutMsg" BU_SG_REL_ EBCM_HS SG_ 241 BrkPedTrvlAchvdV 241;
BA_REL_ "GenSigSuprvResp" BU_SG_REL_ EBCM_HS SG_ 241 BrkPedTrvlAchvdV 1;
BA_REL_ "GenSigTimeoutTime" BU_SG_REL_ BSM_HS SG_ 241 BrkPedTrvlAchvdV 500;
BA_REL_ "GenSigTimeoutMsg" BU_SG_REL_ BSM_HS SG_ 241 BrkPedTrvlAchvdV 241;
BA_REL_ "GenSigSuprvResp" BU_SG_REL_ BSM_HS SG_ 241 BrkPedTrvlAchvdV 1;
BA_REL_ "GenSigTimeoutTime" BU_SG_REL_ EPS_HS SG_ 241 BrkPdlPosGrad 250;
BA_REL_ "GenSigTimeoutMsg" BU_SG_REL_ EPS_HS SG_ 241 BrkPdlPosGrad 241;
BA_REL_ "GenSigSuprvResp" BU_SG_REL_ EPS_HS SG_ 241 BrkPdlPosGrad 1;
BA_REL_ "GenSigTimeoutTime" BU_SG_REL_ CGM_HS SG_ 241 BrkPdlPosGrad 250;
BA_REL_ "GenSigTimeoutMsg" BU_SG_REL_ CGM_HS SG_ 241 BrkPdlPosGrad 241;
BA_REL_ "GenSigSuprvResp" BU_SG_REL_ CGM_HS SG_ 241 BrkPdlPosGrad 1;
BA_REL_ "GenSigTimeoutTime" BU_SG_REL_ EBCM_HS SG_ 241 BrkPdlPosGrad 250;
BA_REL_ "GenSigTimeoutMsg" BU_SG_REL_ EBCM_HS SG_ 241 BrkPdlPosGrad 241;
BA_REL_ "GenSigSuprvResp" BU_SG_REL_ EBCM_HS SG_ 241 BrkPdlPosGrad 1;
BA_REL_ "GenSigTimeoutTime" BU_SG_REL_ ECM_HS SG_ 241 BrkPdlPos 250;
BA_REL_ "GenSigTimeoutMsg" BU_SG_REL_ ECM_HS SG_ 241 BrkPdlPos 241;
BA_REL_ "GenSigSuprvResp" BU_SG_REL_ ECM_HS SG_ 241 BrkPdlPos 1;
BA_REL_ "GenSigTimeoutTime" BU_SG_REL_ EPS_HS SG_ 241 BrkPdlPos 250;
BA_REL_ "GenSigTimeoutMsg" BU_SG_REL_ EPS_HS SG_ 241 BrkPdlPos 241;
BA_REL_ "GenSigSuprvResp" BU_SG_REL_ EPS_HS SG_ 241 BrkPdlPos 1;
BA_REL_ "GenSigTimeoutTime" BU_SG_REL_ CGM_HS SG_ 241 BrkPdlPos 250;
BA_REL_ "GenSigTimeoutMsg" BU_SG_REL_ CGM_HS SG_ 241 BrkPdlPos 241;
BA_REL_ "GenSigSuprvResp" BU_SG_REL_ CGM_HS SG_ 241 BrkPdlPos 1;
BA_REL_ "GenSigTimeoutTime" BU_SG_REL_ EBCM_HS SG_ 241 BrkPdlPos 250;
BA_REL_ "GenSigTimeoutMsg" BU_SG_REL_ EBCM_HS SG_ 241 BrkPdlPos 241;
BA_REL_ "GenSigSuprvResp" BU_SG_REL_ EBCM_HS SG_ 241 BrkPdlPos 1;
BA_REL_ "GenSigTimeoutTime" BU_SG_REL_ EPS_HS SG_ 241 BrkPedPosAlvRolngCnt 250;
BA_REL_ "GenSigTimeoutMsg" BU_SG_REL_ EPS_HS SG_ 241 BrkPedPosAlvRolngCnt 241;
BA_REL_ "GenSigSuprvResp" BU_SG_REL_ EPS_HS SG_ 241 BrkPedPosAlvRolngCnt 1;
BA_REL_ "GenSigTimeoutTime" BU_SG_REL_ EBCM_HS SG_ 241 BrkPedPosAlvRolngCnt 250;
BA_REL_ "GenSigTimeoutMsg" BU_SG_REL_ EBCM_HS SG_ 241 BrkPedPosAlvRolngCnt 241;
BA_REL_ "GenSigSuprvResp" BU_SG_REL_ EBCM_HS SG_ 241 BrkPedPosAlvRolngCnt 1;
BA_REL_ "GenSigVBitResp" BU_SG_REL_ ECM_HS SG_ 241 BrkPdlModTrvl 1;
BA_REL_ "GenSigTimeoutTime" BU_SG_REL_ EPS_HS SG_ 241 BrkPdlModTrvl 250;
BA_REL_ "GenSigTimeoutMsg" BU_SG_REL_ EPS_HS SG_ 241 BrkPdlModTrvl 241;
BA_REL_ "GenSigSuprvResp" BU_SG_REL_ EPS_HS SG_ 241 BrkPdlModTrvl 1;
BA_REL_ "GenSigTimeoutTime" BU_SG_REL_ CGM_HS SG_ 241 BrkPdlModTrvl 250;
BA_REL_ "GenSigTimeoutMsg" BU_SG_REL_ CGM_HS SG_ 241 BrkPdlModTrvl 241;
BA_REL_ "GenSigSuprvResp" BU_SG_REL_ CGM_HS SG_ 241 BrkPdlModTrvl 1;
BA_REL_ "GenSigTimeoutTime" BU_SG_REL_ EBCM_HS SG_ 241 BrkPdlModTrvl 250;
BA_REL_ "GenSigTimeoutMsg" BU_SG_REL_ EBCM_HS SG_ 241 BrkPdlModTrvl 241;
BA_REL_ "GenSigSuprvResp" BU_SG_REL_ EBCM_HS SG_ 241 BrkPdlModTrvl 1;
BA_REL_ "GenSigTimeoutTime" BU_SG_REL_ EPS_HS SG_ 241 BrkPdlInTrvPrt 250;
BA_REL_ "GenSigTimeoutMsg" BU_SG_REL_ EPS_HS SG_ 241 BrkPdlInTrvPrt 241;
BA_REL_ "GenSigSuprvResp" BU_SG_REL_ EPS_HS SG_ 241 BrkPdlInTrvPrt 1;
BA_REL_ "GenSigTimeoutTime" BU_SG_REL_ CGM_HS SG_ 241 BrkPdlInTrvPrt 250;
BA_REL_ "GenSigTimeoutMsg" BU_SG_REL_ CGM_HS SG_ 241 BrkPdlInTrvPrt 241;
BA_REL_ "GenSigSuprvResp" BU_SG_REL_ CGM_HS SG_ 241 BrkPdlInTrvPrt 1;
BA_REL_ "GenSigTimeoutTime" BU_SG_REL_ EBCM_HS SG_ 241 BrkPdlInTrvPrt 250;
BA_REL_ "GenSigTimeoutMsg" BU_SG_REL_ EBCM_HS SG_ 241 BrkPdlInTrvPrt 241;
BA_REL_ "GenSigSuprvResp" BU_SG_REL_ EBCM_HS SG_ 241 BrkPdlInTrvPrt 1;
VAL_ 313 LnchCtrlRelLnLockReqd 1 "true" 0 "false" ;
VAL_ 313 VehStbEnhmntCurStRq 2 "On" 1 "Off" 0 "No Action" ;
VAL_ 313 TCSysCurStReq 2 "On" 1 "Off" 0 "No Action" ;
VAL_ 313 DrvrDrOpenSwVDA 1 "Virtual Device Available" 0 "Virtual Device Unavailable" ;
VAL_ 313 DrDoorOpenSwActV 1 "Invalid" 0 "Valid" ;
VAL_ 313 DrDoorOpenSwAct 1 "true" 0 "false" ;
VAL_ 313 LnchCtrlWhlSlpReq 31 "Unused and Reserved 10" 30 "Unused and Reserved 9" 29 "Unused and Reserved 8" 28 "Unused and Reserved 7" 27 "Unused and Reserved 6" 26 "Unused and Reserved 5" 25 "Unused and Reserved 4" 24 "Unused and Reserved 3" 23 "Unused and Reserved 2" 22 "Unused and Reserved 1" 21 "Fifteen Percent" 20 "Fourteen And A Half Percent" 19 "Fourteen Percent" 18 "Thirteen And A Half Percent" 17 "Thirteen Percent" 16 "Twelve And A Half Percent" 15 "Twelve Percent" 14 "Eleven And a Half Percent" 13 "Eleven Percent" 12 "Ten And A Half Percent" 11 "Ten Percent" 10 "Nine And A Half Percent" 9 "Nine Percent" 8 "Eight And A Half Percent" 7 "Eight Percent" 6 "Seven And A Half Percent" 5 "Seven Percent" 4 "Six And A Half Percent" 3 "Six Percent" 2 "Five And A Half Percent" 1 "Five Percent" 0 "No Action" ;
VAL_ 313 LnchCtrlMdReq 3 "Burn Out" 2 "Custom" 1 "Automatic" 0 "No Action" ;
VAL_ 313 LnchCtrlEngRPMReq 63 "Unused and Reserved 30" 62 "Unused and Reserved 29" 61 "Unused and Reserved 28" 60 "Unused and Reserved 27" 59 "Unused and Reserved 26" 58 "Unused and Reserved 25" 57 "Unused and Reserved 24" 56 "Unused and Reserved 23" 55 "Unused and Reserved 22" 54 "Unused and Reserved 21" 53 "Unused and Reserved 20" 52 "Unused and Reserved 19" 51 "Unused and Reserved 18" 50 "Unused and Reserved 17" 49 "Unused and Reserved 16" 48 "Unused and Reserved 15" 47 "Unused and Reserved 14" 46 "Unused and Reserved 13" 45 "Unused and Reserved 12" 44 "Unused and Reserved 11" 43 "Unused and Reserved 10" 42 "Unused and Reserved 9" 41 "Unused and Reserved 8" 40 "Unused and Reserved 7" 39 "Unused and Reserved 6" 38 "Unused and Reserved 5" 37 "Unused and Reserved 4" 36 "Unused and Reserved 3" 35 "Unused and Reserved 2" 34 "Unused and Reserved 1" 33 "4000" 32 "3900" 31 "3800" 30 "3700" 29 "3600" 28 "3500" 27 "3400" 26 "3300" 25 "3200" 24 "3100" 23 "3000" 22 "2900" 21 "2800" 20 "2700" 19 "2600" 18 "2500" 17 "2400" 16 "2300" 15 "2200" 14 "2100" 13 "2000" 12 "1900" 11 "1800" 10 "1700" 9 "1600" 8 "1500" 7 "1400" 6 "1300" 5 "1200" 4 "1100" 3 "1000" 2 "900" 1 "800" 0 "No Action" ;
VAL_ 313 ExtHlStrAssCsStRq 2 "Standard Hold" 1 "Extended Hold" 0 "No Action" ;
VAL_ 313 DrvStyPerfMdCsStReq 7 "Performance Mode 7" 6 "Performance Mode 6" 5 "Performance Mode 5" 4 "Performance Mode 4" 3 "Performance Mode 3" 2 "Performance Mode 2" 1 "Performance Mode 1" 0 "No Action" ;
VAL_ 313 PsngStPerfMdCsStReq 7 "Auto" 6 "Performance Mode 6" 5 "Performance Mode 5" 4 "Performance Mode 4" 3 "Performance Mode 3" 2 "Performance Mode 2" 1 "Performance Mode 1" 0 "No Action" ;
VAL_ 313 DrvrStPerfMdCsStReq 7 "Auto" 6 "Performance Mode 6" 5 "Performance Mode 5" 4 "Performance Mode 4" 3 "Performance Mode 3" 2 "Performance Mode 2" 1 "Performance Mode 1" 0 "No Action" ;
VAL_ 313 ACCPerfMdCsStReq 7 "Auto" 6 "Performance Mode 6" 5 "Performance Mode 5" 4 "Performance Mode 4" 3 "Performance Mode 3" 2 "Performance Mode 2" 1 "Performance Mode 1" 0 "No Action" ;
VAL_ 313 PrkAstAdvSysAct 1 "true" 0 "false" ;
VAL_ 313 SndPerfMdCsStRq 0 "No Action" 1 "Performance Mode 1" 2 "Performance Mode 2" 3 "Performance Mode 3" 4 "Performance Mode 4" 5 "Performance Mode 5" 6 "Performance Mode 6" 7 "Auto" ;
VAL_ 313 HptcStVbnStat 0 "Normal Operation" 1 "Unknown" 2 "Failed" ;
VAL_ 313 ACCSettingType 0 "Manual" 1 "Auto" ;
VAL_ 313 FCABrkPrflReq 1 "true" 0 "false" ;
VAL_ 313 ISA2CCC_ScndCdChr 0 "Unknown" 1 "A" 2 "B" 3 "C" 4 "D" 5 "E" 6 "F" 7 "G" 8 "H" 9 "I" 10 "J" 11 "K" 12 "L" 13 "M" 14 "N" 15 "O" 16 "P" 17 "Q" 18 "R" 19 "S" 20 "T" 21 "U" 22 "V" 23 "W" 24 "X" 25 "Y" 26 "Z" ;
VAL_ 313 ISA2CCC_FrstCdChr 0 "Unknown" 1 "A" 2 "B" 3 "C" 4 "D" 5 "E" 6 "F" 7 "G" 8 "H" 9 "I" 10 "J" 11 "K" 12 "L" 13 "M" 14 "N" 15 "O" 16 "P" 17 "Q" 18 "R" 19 "S" 20 "T" 21 "U" 22 "V" 23 "W" 24 "X" 25 "Y" 26 "Z" ;
VAL_ 313 DispPerfMdCsStRq 0 "No Action" 1 "Performance Mode 1" 2 "Performance Mode 2" 3 "Performance Mode 3" 4 "Performance Mode 4" 5 "Performance Mode 5" 6 "Performance Mode 6" 7 "Auto" ;
VAL_ 313 CrshAlrtStPrsnt 1 "true" 0 "false" ;
VAL_ 313 FwdClnAlrtCustStngReq 0 "No Action" 1 "Off" 2 "On" ;
VAL_ 313 GNCustStngReq 0 "No Action" 1 "Off" 2 "On" ;
VAL_ 1328 ACSAlarm9 2 "Expired" 1 "Active" 0 "Inactive" ;
VAL_ 1328 ACSAlarm8 2 "Expired" 1 "Active" 0 "Inactive" ;
VAL_ 1328 ACSAlarm7 2 "Expired" 1 "Active" 0 "Inactive" ;
VAL_ 1328 ACSAlarm6 2 "Expired" 1 "Active" 0 "Inactive" ;
VAL_ 1328 ACSAlarm5 2 "Expired" 1 "Active" 0 "Inactive" ;
VAL_ 1328 ACSAlarm4 2 "Expired" 1 "Active" 0 "Inactive" ;
VAL_ 1328 ACSAlarm3 2 "Expired" 1 "Active" 0 "Inactive" ;
VAL_ 1328 ACSAlarm2 2 "Expired" 1 "Active" 0 "Inactive" ;
VAL_ 1328 ACSAlarm15 2 "Expired" 1 "Active" 0 "Inactive" ;
VAL_ 1328 ACSAlarm14 2 "Expired" 1 "Active" 0 "Inactive" ;
VAL_ 1328 ACSAlarm13 2 "Expired" 1 "Active" 0 "Inactive" ;
VAL_ 1328 ACSAlarm12 2 "Expired" 1 "Active" 0 "Inactive" ;
VAL_ 1328 ACSAlarm11 2 "Expired" 1 "Active" 0 "Inactive" ;
VAL_ 1328 ACSAlarm10 2 "Expired" 1 "Active" 0 "Inactive" ;
VAL_ 1328 ACSAlarm1 2 "Expired" 1 "Active" 0 "Inactive" ;
VAL_ 1328 ACSAlarm0 2 "Expired" 1 "Active" 0 "Inactive" ;
VAL_ 311 PsngSysHdingV 1 "Invalid" 0 "Valid" ;
VAL_ 311 HrsV 1 "Invalid" 0 "Valid" ;
VAL_ 311 MinsV 1 "Invalid" 0 "Valid" ;
VAL_ 311 PsngSysDilPrcsV 1 "Invalid" 0 "Valid" ;
VAL_ 311 PsngSysElvtnV 1 "Invalid" 0 "Valid" ;
VAL_ 311 VehSpeSta 3 "Invalid" 2 "Fast" 1 "Slow" 0 "Stationary" ;
VAL_ 810 PsngSysLongV 1 "Invalid" 0 "Valid" ;
VAL_ 810 PsngSysLatV 1 "Invalid" 0 "Valid" ;
VAL_ 304 PedFrndlyAlrtCsStReq 0 "No Action" 1 "Off" 2 "On" ;
VAL_ 304 AlrmStat 4 "Arming Delay" 3 "Alarm Active" 2 "Disarmed" 1 "Armed" 0 "Off" ;
VAL_ 1105 BrkPdLfSysDrvrRq 4 "Reset Rear" 3 "Reset Front" 2 "Enable" 1 "Disable" 0 "No Action" ;
VAL_ 1105 HybImpSnsDsbld 1 "true" 0 "false" ;
VAL_ 1105 JmpStrtReq 1 "true" 0 "false" ;
VAL_ 1105 HybVehHiVltInvDisRqd 1 "true" 0 "false" ;
VAL_ 1105 NESSRoSevSt 1 "true" 0 "false" ;
VAL_ 1105 NESSRiSiSevSt 1 "true" 0 "false" ;
VAL_ 1105 NESSReImpSevSt 1 "true" 0 "false" ;
VAL_ 1105 NESSLeSiSevSt 1 "true" 0 "false" ;
VAL_ 1105 NESSFrImpSt2SevSt 1 "true" 0 "false" ;
VAL_ 1105 NESSFrImpSt1SevSt 1 "true" 0 "false" ;
VAL_ 1105 NESSFrImpPreSevSt 1 "true" 0 "false" ;
VAL_ 322 TCSTmpDsblReqConf 2 "Yes" 1 "No" 0 "No Action" ;
VAL_ 322 VehStbCmptvMdCurStRq 2 "On" 1 "Off" 0 "No Action" ;
VAL_ 322 RgtLnChgThrt 1 "true" 0 "false" ;
VAL_ 322 LftLnChgThrt 1 "true" 0 "false" ;
VAL_ 322 AFLGPSCstStReq 0 "No Action" 1 "Corner And Curve Lighting Only" 2 "Intelligent Light Distribution" 3 "GPS Assistance" 4 "Reserved1" 5 "Reserved2" 6 "Reserved3" 7 "Off" ;
VAL_ 322 AFLCstStReq 0 "No Action" 1 "Corner And Curve Lighting Only" 2 "Intelligent Light Distribution" 3 "Reserved1" 4 "Reserved2" 5 "Reserved3" 6 "Reserved4" 7 "Off" ;
VAL_ 322 LtRtHnTrCstStReq 0 "No Action" 1 "Left Hand Traffic" 2 "Right Hand Traffic" ;
VAL_ 322 AdpHgBmAsSnCsStRq 0 "No Action" 1 "Off" 2 "Normal Sensitivity" 3 "Reduced Sensitivity" 4 "Reserved1" 5 "Reserved2" 6 "Reserved3" 7 "Reserved4" ;
VAL_ 322 AdpHgBmAstCstStRq 0 "No Action" 1 "Off" 2 "On" 3 "Reserved1" 4 "Reserved2" 5 "Reserved3" 6 "Reserved4" 7 "Reserved5" ;
VAL_ 322 LtRtHnTrGPSCstStRq 0 "No Action" 1 "Left Hand Traffic" 2 "Right Hand Traffic" 3 "Automatic" 4 "Reserved1" 5 "Reserved2" 6 "Reserved3" 7 "Reserved4" ;
VAL_ 322 AutHgBmAsSnCsStRq 0 "No Action" 1 "Off" 2 "On Normal Sensitivity" 3 "On Reduced Sensitivity" 4 "Reserved1" 5 "Reserved2" 6 "Reserved3" 7 "Reserved4" ;
VAL_ 322 AutHgBmAstCstStRq 0 "No Action" 1 "Off" 2 "On" 3 "Reserved1" 4 "Reserved2" 5 "Reserved3" 6 "Reserved4" 7 "Reserved5" ;
VAL_ 322 HtVwAutnmsEPBAplyReqd 1 "true" 0 "false" ;
VAL_ 309 PedFrndlyAlrtSndMnAct 1 "true" 0 "false" ;
VAL_ 309 StBltTgtCSRq 0 "No Action" 1 "Low" 2 "Normal" 3 "Performance" 4 "Locked" ;
VAL_ 309 ColPrSysCustReq 4 "Alert and Brake and Steer" 0 "No Action" 1 "Off" 2 "Alert" 3 "Alert and Brake" ;
VAL_ 309 SecV 1 "Invalid" 0 "Valid" ;
VAL_ 309 CldrMth_154 1 "January" 0 "Unknown" 12 "December" 11 "November" 10 "October" 9 "September" 8 "August" 7 "July" 6 "June" 5 "May" 4 "April" 3 "March" 2 "February" ;
VAL_ 309 CldrMth 12 "December" 11 "November" 10 "October" 9 "September" 8 "August" 7 "July" 6 "June" 5 "May" 4 "April" 3 "March" 2 "February" 1 "January" 0 "Unknown" ;
VAL_ 309 AutoHiBmVDA 1 "VirtualDeviceAvailable" 0 "VirtualDeviceUnavailable" ;
VAL_ 309 CtLghtDet 1 "true" 0 "false" ;
VAL_ 309 RrClosVDA 1 "VirtualDeviceAvailable" 0 "VirtualDeviceUnavailable" ;
VAL_ 309 TCSysDisSwAtv 1 "true" 0 "false" ;
VAL_ 309 VehMovState 4 "Invalid" 3 "Reverse" 2 "Forward" 1 "Neutral" 0 "Parked" ;
VAL_ 309 TCSysDisSwAtvV 1 "Invalid" 0 "Valid" ;
VAL_ 309 HillDesCtrlMdSwActV 1 "Invalid" 0 "Valid" ;
VAL_ 309 WSWshSwAtv 1 "true" 0 "false" ;
VAL_ 309 HillDesCtrlMdSwAct 1 "true" 0 "false" ;
VAL_ 309 RrClosAjarSwAct 1 "true" 0 "false" ;
VAL_ 309 WSWprAct 1 "true" 0 "false" ;
VAL_ 352 ShfFrmPrkAlwd 1 "true" 0 "false" ;
VAL_ 352 AVHSwtchStats 1 "Active" 0 "Not Active" ;
VAL_ 352 SmrtHgBmAstCstCurrSetVal 7 "Unused and Reserved 5" 6 "Unused and Reserved 4" 5 "Unused and Reserved 3" 4 "Unused and Reserved 2" 3 "Unused and Reserved 1" 2 "Adaptive High Beam" 1 "Auto High Beam" 0 "No Action" ;
VAL_ 352 TeenDrvAct 1 "true" 0 "false" ;
VAL_ 352 LrnEnvIdSt 1 "Info_valid" 0 "No_info" ;
VAL_ 352 ImoIdSt 1 "Info valid" 0 "No info" ;
VAL_ 320 Ky_IdDevPrgmAuthReq 1 "true" 0 "false" ;
VAL_ 320 ClmnLckStatV 1 "Invalid" 0 "Valid" ;
VAL_ 320 ClmnLckStat 2 "Locked unsuccessful" 1 "Unlocked" 0 "Locked" 3 "Unlocked unsuccessful" ;
VAL_ 320 AutoBmSlctAllwd 1 "true" 0 "false" ;
VAL_ 320 BrkLtsAtv 1 "true" 0 "false" ;
VAL_ 320 TrnSwAct 2 "Right" 1 "Left" 0 "No Activation" ;
VAL_ 320 RrFogLmpsAct 1 "true" 0 "false" ;
VAL_ 320 OtsdAmbtLtLvlStatV 1 "Invalid" 0 "Valid" ;
VAL_ 320 OtsdAmbtLtLvlStat 2 "Day" 1 "Night" 0 "Unknown" ;
VAL_ 320 MainLghtSw 3 "HEADLAMP" 2 "PARKLAMP" 1 "OFF" 0 "AUTO" ;
VAL_ 320 LowBmAct 1 "true" 0 "false" ;
VAL_ 320 HighBmAct 1 "true" 0 "false" ;
VAL_ 320 HdlmpBmSelectStat 2 "High Beams" 1 "Low Beams" 0 "Unknown" ;
VAL_ 320 FlToPsSwAtv 1 "true" 0 "false" ;
VAL_ 320 AdvFrntLghtSysEnbld 1 "true" 0 "false" ;
VAL_ 320 FrFogLmpsAct 1 "true" 0 "false" ;
VAL_ 320 AutLghtCtrl 1 "true" 0 "false" ;
VAL_ 499 PTShftPtrnOvrdAct 1 "true" 0 "false" ;
VAL_ 499 PFTrnsTUDSecSwSt 3 "Illegal Up/Down Switch State Active" 2 "Decrement Switch Active" 1 "Increment Switch Active" 0 "No Activation" ;
VAL_ 499 TrnsPFShftPattSw4Act 1 "true" 0 "false" ;
VAL_ 499 TrnsPFShftPattSw3Act 1 "true" 0 "false" ;
VAL_ 499 TrnsPFShftPattSw2Act 1 "true" 0 "false" ;
VAL_ 499 TrnsPFShftPattSw1Act 1 "true" 0 "false" ;
VAL_ 499 PFTrnsTUDSwSt 3 "Illegal Up/Down Switch State Active" 2 "Decrement Switch Active" 1 "Increment Switch Active" 0 "No Activation" ;
VAL_ 499 PFTrnsTUDEnSwSt 3 "Illegal Enable Switch State" 2 "Electronic Range Select Enable Sw" 1 "Driver Shift Control Enable Switch" 0 "No Activation" ;
VAL_ 499 OvrdrvDsblReqd 1 "true" 0 "false" ;
VAL_ 298 DrvrDrAjrSwVDA 1 "Virtual Device Available" 0 "Virtual Device Unavailable" ;
VAL_ 298 ValetMdAct 1 "true" 0 "false" ;
VAL_ 298 AutoMdSpdLmtCnfrmd 1 "true" 0 "false" ;
VAL_ 298 TCSysDisSwAtv_12A 1 "true" 0 "false" ;
VAL_ 298 ChmAct 1 "true" 0 "false" ;
VAL_ 298 Ky_IdDevPr 1 "true" 0 "false" ;
VAL_ 298 DDAjrSwAtvM 0 "Don't Use Data" 1 "Use Data" ;
VAL_ 298 CrshAlrtDrvrSlctdType 0 "Chime" 1 "Seat" ;
VAL_ 298 PsSbltAtcV 1 "Invalid" 0 "Valid" ;
VAL_ 298 PsSbltAtc 1 "true" 0 "false" ;
VAL_ 298 TrlrBrkDsplyAct 1 "true" 0 "false" ;
VAL_ 298 RdSpdCatType 3 "all speed categories 0 - 50 km/h" 2 "all speed categories 51-80 km/h" 1 "all speed categories 81-130 km/h" 0 "all speed categories > 130 km/h" ;
VAL_ 298 LnCat 3 "Four Or More Lanes" 2 "Two Or Three Lanes" 1 "One lane" 0 "no info available" ;
VAL_ 298 FncRdClass 7 "COLLECTOR" 6 "ALLEY" 5 "ARTERIAL" 4 "HIGHWAY" 3 "PED-MALL" 2 "FREEWAY" 1 "SFREEWAY" 0 "LOCAL (Residential Road)" ;
VAL_ 298 SprtLnRd 1 "true" 0 "false" ;
VAL_ 298 CntrldAccRd 1 "true" 0 "false" ;
VAL_ 298 BldUpArDet 1 "true" 0 "false" ;
VAL_ 298 MpDataAvlbl 1 "true" 0 "false" ;
VAL_ 298 SusCustStngReq 7 "Auto" 6 "Performance Mode 6" 5 "Performance Mode 5" 4 "Performance Mode 4" 3 "Performance Mode 3" 2 "Performance Mode 2" 1 "Performance Mode 1" 0 "No Action" ;
VAL_ 298 StrCustStngReq 7 "Auto" 6 "Performance Mode 6" 5 "Performance Mode 5" 4 "Performance Mode 4" 3 "Performance Mode 3" 2 "Performance Mode 2" 1 "Performance Mode 1" 0 "No Action" ;
VAL_ 298 RstrCustFctrDef 1 "Restore Defaults" 0 "No Action" ;
VAL_ 298 DrvlnCustStngReq 7 "Auto" 6 "Performance Mode 6" 5 "Performance Mode 5" 4 "Performance Mode 4" 3 "Performance Mode 3" 2 "Performance Mode 2" 1 "Performance Mode 1" 0 "No Action" ;
VAL_ 298 ChmMstrVDA 1 "VirtualDeviceAvailable" 0 "VirtualDeviceUnavailable" ;
VAL_ 298 IPCVDA 1 "VirtualDeviceAvailable" 0 "VirtualDeviceUnavailable" ;
VAL_ 298 HeadUpDispVDA 1 "VirtualDeviceAvailable" 0 "VirtualDeviceUnavailable" ;
VAL_ 298 HapticSeatVDA 1 "VirtualDeviceAvailable" 0 "VirtualDeviceUnavailable" ;
VAL_ 298 RRDoorAjarSwAct 1 "true" 0 "false" ;
VAL_ 298 PDAjrSwAtv 1 "true" 0 "false" ;
VAL_ 298 DDAjrSwAtv 1 "true" 0 "false" ;
VAL_ 298 TrlrHWIntrfcVDA 1 "VirtualDeviceAvailable" 0 "VirtualDeviceUnavailable" ;
VAL_ 298 DrId 7 "Unknown" 6 "Driver #7" 5 "Driver #6" 4 "Driver #5" 3 "Driver #4" 2 "Driver #3" 1 "Driver #2" 0 "Driver #1" ;
VAL_ 298 EnrgMgtLdShdRq 4 "Load Shed Level 4" 3 "Load Shed Level 3" 2 "Load Shed Level 2" 1 "Load Shed Level 1" 0 "No Load Shedding" ;
VAL_ 298 DrSbltAtcV 1 "Invalid" 0 "Valid" ;
VAL_ 298 TrlrHtchSwAtv 1 "true" 0 "false" ;
VAL_ 298 TreInfMonSysRstReq 1 "true" 0 "false" ;
VAL_ 298 HUDActv 1 "true" 0 "false" ;
VAL_ 298 BatVltV 1 "Invalid" 0 "Valid" ;
VAL_ 298 RLDoorAjarSwAct 1 "true" 0 "false" ;
VAL_ 298 DrSbltAtc 1 "true" 0 "false" ;
VAL_ 1322 TireRRPrsV 1 "Invalid" 0 "Valid" ;
VAL_ 1322 TireRRPrsStat 5 "High" 4 "Low - Extended Mobility" 3 "Low" 2 "Low - Service Now" 1 "Nominal" 0 "Unknown" ;
VAL_ 1322 TireRFPrsV 1 "Invalid" 0 "Valid" ;
VAL_ 1322 TireRFPrsStat 5 "High" 4 "Low - Extended Mobility" 3 "Low" 2 "Low - Service Now" 1 "Nominal" 0 "Unknown" ;
VAL_ 1322 TireLRPrsV 1 "Invalid" 0 "Valid" ;
VAL_ 1322 TireLRPrsStat 5 "High" 4 "Low - Extended Mobility" 3 "Low" 2 "Low - Service Now" 1 "Nominal" 0 "Unknown" ;
VAL_ 1322 TireLFPrsV 1 "Invalid" 0 "Valid" ;
VAL_ 1322 TireLFPrsStat 5 "High" 4 "Low - Extended Mobility" 3 "Low" 2 "Low - Service Now" 1 "Nominal" 0 "Unknown" ;
VAL_ 288 VehOdoV 1 "Invalid" 0 "Valid" ;
VAL_ 1009 EngAirFltMonDrvrReq 3 "Reset" 2 "Disable" 1 "Enable" 0 "No Action" ;
VAL_ 1009 RstrctdPTOpModeReqd 1 "true" 0 "false" ;
VAL_ 1009 ClmtCtrlHtrEngRunRq 1 "Engine Run Requested" 0 "No Action" ;
VAL_ 1009 OtsAirTmpCrValMsk 0 "Don't Use Data" 1 "Use Data" ;
VAL_ 1009 ACCmEngRunReq 1 "Engine Run Requested" 0 "No Action" ;
VAL_ 1009 OutAirTempVDA 1 "VirtualDeviceAvailable" 0 "VirtualDeviceUnavailable" ;
VAL_ 1009 OtsAirTmpCrValV 1 "Invalid" 0 "Valid" ;
VAL_ 1009 EngOffTmVDA 1 "VirtualDeviceAvailable" 0 "VirtualDeviceUnavailable" ;
VAL_ 1009 ClntCircPmpRq 1 "On" 0 "Off" ;
VAL_ 1009 EngOffTmExtRngV 1 "Invalid" 0 "Valid" ;
VAL_ 1009 PF_MinIdlBstLvlReq 3 "Boost Level 3" 2 "Boost Level 2" 1 "Boost Level 1" 0 "No Boost Requested" ;
VAL_ 1257 ElpsdTimeCntRstOcc 1 "true" 0 "false" ;
VAL_ 1257 VSESysPrs 1 "true" 0 "false" ;
VAL_ 1257 ABSPr 1 "true" 0 "false" ;
VAL_ 1257 TCSysPr 1 "true" 0 "false" ;
VAL_ 1257 VehSpdCntlSystmType 2 "Adaptive Cruise Control" 1 "Conventional Cruise Control" 0 "No Vehicle Speed Control" ;
VAL_ 1257 PltfrmEngSpdCmdSysTp 6 "Auto Elevated Idle" 5 "Enhanced Fast Idle" 4 "Fast Idle" 3 "Mobile Variable PTO" 2 "Stationary Variable PTO" 1 "Stationary PTO" 0 "No Platform Eng. Speed Command Sys." ;
VAL_ 505 AllNodesVNA_1F9 1 "Activate Virtual Network" 0 "No Activation" ;
VAL_ 505 AccPdlPwrTkOffOvrAct 1 "true" 0 "false" ;
VAL_ 505 PTOTGRReqdGear 10 "Tenth Gear" 9 "Ninth Gear" 8 "Eighth Gear" 7 "Seventh Gear" 6 "Sixth Gear" 5 "Fifth Gear" 4 "Fourth Gear" 3 "Third Gear" 2 "Second Gear" 1 "First Gear" 0 "No Action" ;
VAL_ 505 PTOTGRReqType 3 "Hold Gear" 2 "Min Gear Request" 1 "Max Gear Request" 0 "No Action" ;
VAL_ 505 PTORmtEngStrtReq 1 "PTO Remote Start Requested" 0 "PTO Remote Start Not Requested" ;
VAL_ 505 TrnsPTOCltchRelRqd 1 "true" 0 "false" ;
VAL_ 505 FstIdlMdAct 1 "true" 0 "false" ;
VAL_ 505 PTOMdAct 1 "true" 0 "false" ;
VAL_ 505 PTOEngTrqLmtRchd 1 "true" 0 "false" ;
VAL_ 505 PltfrmEngSpdCmdMdAct 1 "true" 0 "false" ;
VAL_ 505 PFESpdCmdOnSwAct 1 "true" 0 "false" ;
VAL_ 505 PFESpdCmdDeSwAct 1 "true" 0 "false" ;
VAL_ 505 PFESpdCmdInSwAct 1 "true" 0 "false" ;
VAL_ 505 PFESpdCmdSwDIntg 2 "Failure Detected" 1 "Data Invalid" 0 "Data Valid" ;
VAL_ 505 PTORmtEngShtdwnReqd 1 "true" 0 "false" ;
VAL_ 497 ElvtdIdlCstStReq 0 "No Action" 1 "Off" 2 "On" ;
VAL_ 497 FuelFltLfRstRqd 1 "true" 0 "false" ;
VAL_ 497 ACCompSysVDA 1 "VirtualDeviceAvailable" 0 "VirtualDeviceUnavailable" ;
VAL_ 497 BkupPwrModeMstrVDA 1 "VirtualDeviceAvailable" 0 "VirtualDeviceUnavailable" ;
VAL_ 497 PrkBrkVDA 1 "VirtualDeviceAvailable" 0 "VirtualDeviceUnavailable" ;
VAL_ 497 PrkBrkVDM 1 "Use Data" 0 "Don't Use Data" ;
VAL_ 497 BkupPwrModeMstrVDM 1 "Use Data" 0 "Don't Use Data" ;
VAL_ 497 ACCompSysVDM 1 "Use Data" 0 "Don't Use Data" ;
VAL_ 497 AirbgVDA 1 "VirtualDeviceAvailable" 0 "VirtualDeviceUnavailable" ;
VAL_ 497 SysBkupPwrMdEn 1 "true" 0 "false" ;
VAL_ 497 SysBkUpPwrMd 3 "Crank Request" 2 "Run" 1 "Accessory" 0 "Off" ;
VAL_ 497 SysPwrMd 3 "Crank Request" 2 "Run" 1 "Accessory" 0 "Off" ;
VAL_ 497 TrStLgMdAtv 1 "true" 0 "false" ;
VAL_ 497 DispMeasSys 1 "English" 0 "Metric" ;
VAL_ 497 ACCmpsrFldOn 1 "true" 0 "false" ;
VAL_ 497 ACCompModReq 3 "No Action" 2 "Engage" 1 "Disengage" 0 "Disengage Immediately" ;
VAL_ 497 ACCompNormLdV 1 "Invalid" 0 "Valid" ;
VAL_ 497 PTORSMstrEngShtReq 1 "true" 0 "false" ;
VAL_ 497 EngOilLfRstRq 1 "true" 0 "false" ;
VAL_ 497 SIRDpl 1 "true" 0 "false" ;
VAL_ 497 PTORmStMsEngStRq 1 "PTO Remote Start Requested" 0 "PTO Remote Start Not Requested" ;
VAL_ 497 RmVehStrRq 1 "Remote Start Requested" 0 "Remote Start Not Requested" ;
VAL_ 497 ThrtlPrgrsnReq 2 "Map C" 1 "Map B" 0 "Map A" ;
VAL_ 497 PrkBrkSwAtv 1 "true" 0 "false" ;
VAL_ 497 PMMAccTrmSt 1 "Active" 0 "Inactive" ;
VAL_ 497 PMMRunCrkTrmSt 1 "Active" 0 "Inactive" ;
VAL_ 497 ImmblzrPreRelPswdStat 1 "Information Valid" 0 "No Information" ;
VAL_ 481 CrsSecSwStat 15 "Unused and Reserved 5" 14 "Unused and Reserved 4" 13 "Unused and Reserved 3" 12 "Unused and Reserved 2" 11 "Unused and Reserved 1" 10 "Lane Centering Control" 9 "Between Ranges" 8 "Short to Power" 7 "Open/Short to Ground" 6 "Speed Decrease High" 5 "Speed Increase High" 4 "Gap Up" 3 "Gap Down" 2 "Lane Keep Assist" 1 "No Activation" 0 "Indeterminate" ;
VAL_ 481 DrvSelMdSw3Sta 1 "Active" 0 "Inactive" ;
VAL_ 481 DrvSelMdSw2Sta 1 "Active" 0 "Inactive" ;
VAL_ 481 AuxHtrRq 1 "On" 0 "Off" ;
VAL_ 481 AuxHtrAtv 1 "true" 0 "false" ;
VAL_ 481 DrvSelMdSw1Sta 1 "Active" 0 "Inactive" ;
VAL_ 481 FuelMdSwActV 1 "Invalid" 0 "Valid" ;
VAL_ 481 FuelMdSwAct 1 "True" 0 "False" ;
VAL_ 481 CrsSpdLmtrSwStat 9 "Between Ranges" 8 "Short to Power" 7 "Open/Short to Ground" 6 "Cancel" 5 "Cruise On/Off" 4 "SL/SW On/Off/GAP" 3 "Set" 2 "Resume" 1 "No Activation" 0 "Indeterminate" ;
VAL_ 481 AdptCrsGapSwAct 2 "Increase Gap" 1 "Decrease Gap" 0 "No Activation" ;
VAL_ 481 CrsCntrlSwStCanSwAct 1 "true" 0 "false" ;
VAL_ 481 CrsCntrlSwStSwDataIntgty 3 "Illegal Range" 2 "Failure Detected" 1 "Data Invalid" 0 "Data Valid" ;
VAL_ 481 CrsCntrlSwStSpdInSwAct 1 "true" 0 "false" ;
VAL_ 481 CrsCntrlSwStSpDcSwAct 1 "true" 0 "false" ;
VAL_ 481 CrsCntrlSwStSetSwAct 1 "true" 0 "false" ;
VAL_ 481 CrsCntrlSwStResSwAct 1 "true" 0 "false" ;
VAL_ 481 CrsCntrlSwStOnSwAct 1 "true" 0 "false" ;
VAL_ 481 CrsCntCncRq 1 "Cancel" 0 "Do Not Cancel" ;
VAL_ 241 NotEventStat 2 "Pretensioner Deployment Event" 1 "Near Deployment Event" 0 "No Event" 3 "Airbag Deployment Event" ;
VAL_ 241 BrkAppSnsrHmPosLrnd 1 "true" 0 "false" ;
VAL_ 241 BrkPedTrvlAchvd 1 "true" 0 "false" ;
VAL_ 241 BrkPedTrvlAchvdV 1 "Invalid" 0 "Valid" ;
VAL_ 241 BrkPdlModTrvlV 1 "Invalid" 0 "Valid" ;
VAL_ 241 BrkPdlModTrvl 1 "true" 0 "false" ;
SIG_GROUP_ 313 IntlStdAlph2CddCntryCd 1 : ISA2CCC_ScndCdChr ISA2CCC_FrstCdChr;
SIG_GROUP_ 1328 AlrmClkStat 1 : ACSAlarm9 ACSAlarm8 ACSAlarm7 ACSAlarm6 ACSAlarm5 ACSAlarm4 ACSAlarm3 ACSAlarm2 ACSAlarm15 ACSAlarm14 ACSAlarm13 ACSAlarm12 ACSAlarm11 ACSAlarm10 ACSAlarm1 ACSAlarm0;
SIG_GROUP_ 1105 NoEvSevSt 1 : NESSRoSevSt NESSRiSiSevSt NESSReImpSevSt NESSLeSiSevSt NESSFrImpSt2SevSt NESSFrImpSt1SevSt NESSFrImpPreSevSt;
SIG_GROUP_ 505 PTOTransGearReq 1 : PTOTGRReqdGear PTOTGRReqType;
SIG_GROUP_ 505 PltfrmEngSpdCmmnd 1 : PltfrmEngSpdCmdMdAct PltfrmEngSpdReq;
SIG_GROUP_ 481 CrsCntrlSwStat 1 : CrsCntrlSwStCanSwAct CrsCntrlSwStSwDataIntgty CrsCntrlSwStSpdInSwAct CrsCntrlSwStSpDcSwAct CrsCntrlSwStSetSwAct CrsCntrlSwStResSwAct CrsCntrlSwStOnSwAct;
SIG_GROUP_ 241 BrkPedInitTrvlAchvdStat 1 : BrkPedTrvlAchvd BrkPedTrvlAchvdV;
